VERSION ""

NS_ :

BS_:

BU_: PowertrainControlModule AtmosphericSensor SafetyRestraintSystem2 Aftertreatment_2_GasOutlet Aftertreatment_2_GasIntake DieselParticulateFilterControl Turbocharger SafetyRestraintSystem1 CabDisplay2 Aftertreatment_1_GasOutlet Aftertreatment_1_GasIntake OnBoardDataLogger OffBoardDiagnosticTool2 OffBoardDiagnosticTool1 FileServer ParkingBrakeController SeatController2 FanDriveController SteeringColumnUnit CommunicationUnitRadio CommunicationUnitSatellite CommunicationUnitCellular PropulsionBatteryCharger ChassisController2 ChassisController1 EngineValveControl AuxiliaryHeater2 AuxiliaryHeater1 ClutchUnit RampControl InformationSystem1 SuspensionSystemController2 OilSensor VehicleDynamicStability ExhaustEmissionController TransmissionDisplay2 TransmissionDisplay1 ClimateControl2 WaterPumpController RearAxleSteeringController LightingOperatorControl SeatController1 IgnitionController2 IgnitionController1 TirePressureController CabController2 CabController1 PneumaticSystemController SuspensionSystemController1 HydraulicPumpController EnduranceBrakingSystem RetarderExhaustEngine2 OnBoardDiagnosticUnit HeadwayController RetarderExhaustEngine1 CabDisplay1 ManagementComputer VirtualTerminal OffVehicleGateway PowerTakeOffFront HitchControl AuxiliaryValveControl BodyController TractorTrailerBridge1 StarterSystem ElectricalSystem VehicleSecurity VehicleNavigation AerodynamicControl ElectricalChargingSystem ClimateControl1 TripRecorder InstrumentCluster SuspensionDriveAxle2 SuspensionDriveAxle1 SuspensionSteerAxle SteeringController FuelSystem CruiseControl RetarderDriveline RetarderEngine BrakesDriveAxle2 BrakesDriveAxle1 BrakesSystemController BrakesSteerAxle AxleDrive2 AxleDrive1 AxleSteering PowerTakeOff ShiftConsoleSecondary ShiftConsolePrimary Transmission2 Transmission1 Engine2 Engine1
VAL_TABLE_ FMI 0 "Above normal (most severe)" 1 "Below normal (most severe)" 2 "Data erratic" 3 "Voltage above normal" 4 "Voltage below normal" 5 "Current below normal" 6 "Current above normal" 7 "Mechanical system not responding" 8 "Abnormal frequency" 9 "Abnormal update rate" 10 "Abnormal rate of change" 11 "Root cause not known" 12 "Bad intelligent device" 13 "Out of calibration" 14 "Special intstructions" 15 "Above normal (least severe)" 16 "Above normal (moderately severe)" 17 "Below normal (least severe)" 18 "Below normal (moderately severe)" 19 "Received network data in error" 20 "Data drifted high" 21 "Data drifted low" 31 "Condition exists" ;
VAL_TABLE_ InvertedBit 1 "orig: 0x0" 0 "orig: 0x1" ;
VAL_TABLE_ InvertedByte 129 "orig: 126 / 0x7E" 255 "orig: 0 / 0x0" 254 "orig: 1 / 0x1" 253 "orig: 2 / 0x2" 252 "orig: 3 / 0x3" 251 "orig: 4 / 0x4" 250 "orig: 5 / 0x5" 249 "orig: 6 / 0x6" 248 "orig: 7 / 0x7" 247 "orig: 8 / 0x8" 246 "orig: 9 / 0x9" 245 "orig: 10 / 0xA" 244 "orig: 11 / 0xB" 243 "orig: 12 / 0xC" 242 "orig: 13 / 0xD" 241 "orig: 14 / 0xE" 240 "orig: 15 / 0xF" 239 "orig: 16 / 0x10" 238 "orig: 17 / 0x11" 237 "orig: 17 / 0x12" 236 "orig: 19 / 0x13" 235 "orig: 20 / 0x14" 234 "orig: 21 / 0x15" 233 "orig: 22 / 0x16" 232 "orig: 23 / 0x17" 231 "orig: 24 / 0x18" 230 "orig: 25 / 0x19" 229 "orig: 26 / 0x1A" 228 "orig: 27 / 0x1B" 227 "orig: 28 / 0x1C" 226 "orig: 29 / 0x1D" 225 "orig: 30 / 0x1E" 224 "orig: 31 / 0x1F" 223 "orig: 32 / 0x20" 222 "orig: 33 / 0x21" 221 "orig: 34 / 0x22" 220 "orig: 35 / 0x23" 219 "orig: 36 / 0x24" 218 "orig: 37 / 0x25" 217 "orig: 38 / 0x26" 216 "orig: 39 / 0x27" 215 "orig: 40 / 0x28" 214 "orig: 41 / 0x29" 213 "orig: 42 / 0x2A" 212 "orig: 43 / 0x2B" 211 "orig: 44 / 0x2C" 210 "orig: 45 / 0x2D" 209 "orig: 46 / 0x2E" 208 "orig: 47 / 0x2F" 207 "orig: 48 / 0x30" 206 "orig: 49 / 0x31" 205 "orig: 50 / 0x32" 204 "orig: 51 / 0x33" 203 "orig: 52 / 0x34" 202 "orig: 53 / 0x35" 201 "orig: 54 / 0x36" 200 "orig: 55 / 0x37" 199 "orig: 56 / 0x38" 198 "orig: 57 / 0x39" 197 "orig: 58 / 0x3A" 196 "orig: 59 / 0x3B" 195 "orig: 60 / 0x3C" 194 "orig: 61 / 0x3D" 193 "orig: 62 / 0x3E" 192 "orig: 63 / 0x3F" 191 "orig: 64 / 0x40" 190 "orig: 65 / 0x41" 189 "orig: 66 / 0x42" 188 "orig: 67 / 0x43" 187 "orig: 68 / 0x44" 186 "orig: 69 / 0x45" 185 "orig: 70 / 0x46" 184 "orig: 71 / 0x47" 183 "orig: 72 / 0x48" 182 "orig: 73 / 0x49" 181 "orig: 74 / 0x4A" 180 "orig: 75 / 0x4B" 179 "orig: 76 / 0x4C" 178 "orig: 77 / 0x4D" 177 "orig: 78 / 0x4E" 176 "orig: 79 / 0x4F" 175 "orig: 80 / 0x50" 174 "orig: 81 / 0x51" 173 "orig: 82 / 0x52" 172 "orig: 83 / 0x53" 171 "orig: 84 / 0x54" 170 "orig: 85 / 0x55" 169 "orig: 86 / 0x56" 168 "orig: 87 / 0x57" 167 "orig: 88 / 0x58" 166 "orig: 89 / 0x59" 165 "orig: 90 / 0x5A" 164 "orig: 91 / 0x5B" 163 "orig: 92 / 0x5C" 162 "orig: 93 / 0x5D" 161 "orig: 94 / 0x5E" 160 "orig: 95 / 0x5F" 159 "orig: 96 / 0x60" 158 "orig: 97 / 0x61" 157 "orig: 98 / 0x62" 156 "orig: 99 / 0x63" 155 "orig: 100 / 0x64" 154 "orig: 101 / 0x65" 153 "orig: 102 / 0x66" 152 "orig: 103 / 0x67" 151 "orig: 104 / 0x68" 150 "orig: 105 / 0x69" 149 "orig: 106 / 0x6A" 148 "orig: 107 / 0x6B" 147 "orig: 108 / 0x6C" 146 "orig: 109 / 0x6D" 145 "orig: 110 / 0x6E" 144 "orig: 111 / 0x6F" 143 "orig: 112 / 0x70" 142 "orig: 113 / 0x71" 141 "orig: 114 / 0x72" 140 "orig: 115 / 0x73" 139 "orig: 116 / 0x74" 138 "orig: 117 / 0x75" 137 "orig: 118 / 0x76" 136 "orig: 119 / 0x77" 135 "orig: 120 / 0x78" 134 "orig: 121 / 0x79" 133 "orig: 122 / 0x7A" 132 "orig: 123 / 0x7B" 131 "orig: 124 / 0x7C" 130 "orig: 125 / 0x7D" 128 "orig: 127 / 0x7F" 127 "orig: 128 / 0x80" 126 "orig: 129 / 0x81" 125 "orig: 130 / 0x82" 124 "orig: 131 / 0x83" 123 "orig: 132 / 0x84" 122 "orig: 133 / 0x85" 121 "orig: 134 / 0x86" 120 "orig: 135 / 0x87" 119 "orig: 136 / 0x88" 118 "orig: 137 / 0x89" 117 "orig: 138 / 0x8A" 116 "orig: 139 / 0x8B" 115 "orig: 140 / 0x8C" 114 "orig: 141 / 0x8D" 113 "orig: 142 / 0x8E" 112 "orig: 143 / 0x8F" 111 "orig: 144 / 0x90" 110 "orig: 145 / 0x91" 109 "orig: 146 / 0x92" 108 "orig: 147 / 0x93" 107 "orig: 148 / 0x94" 106 "orig: 149 / 0x95" 105 "orig: 150 / 0x96" 104 "orig: 151 / 0x97" 103 "orig: 152 / 0x98" 102 "orig: 153 / 0x99" 101 "orig: 154 / 0x9A" 100 "orig: 155 / 0x9B" 99 "orig: 156 / 0x9C" 98 "orig: 157 / 0x9D" 97 "orig: 158 / 0x9E" 96 "orig: 159 / 0x9F" 95 "orig: 160 / 0xA0" 94 "orig: 161 / 0xA1" 93 "orig: 162 / 0xA2" 92 "orig: 163 / 0xA3" 91 "orig: 164 / 0xA4" 90 "orig: 165 / 0xA5" 89 "orig: 166 / 0xA6" 88 "orig: 167 / 0xA7" 87 "orig: 168 / 0xA8" 86 "orig: 169 / 0xA9" 85 "orig: 170 / 0xAA" 84 "orig: 171 / 0xAB" 83 "orig: 172 / 0xAC" 82 "orig: 173 / 0xAD" 81 "orig: 174 / 0xAE" 80 "orig: 175 / 0xAF" 79 "orig: 176 / 0xB0" 78 "orig: 177 / 0xB1" 77 "orig: 178 / 0xB2" 76 "orig: 179 / 0xB3" 75 "orig: 180 / 0xB4" 74 "orig: 181 / 0xB5" 73 "orig: 182 / 0xB6" 72 "orig: 183 / 0xB7" 71 "orig: 184 / 0xB8" 70 "orig: 185 / 0xB9" 69 "orig: 186 / 0xBA" 68 "orig: 187 / 0xBB" 67 "orig: 188 / 0xBC" 66 "orig: 189 / 0xBD" 65 "orig: 190 / 0xBE" 64 "orig: 191 / 0xBF" 63 "orig: 192 / 0xC0" 62 "orig: 193 / 0xC1" 61 "orig: 194 / 0xC2" 60 "orig: 195 / 0xC3" 59 "orig: 196 / 0xC4" 58 "orig: 197 / 0xC5" 57 "orig: 198 / 0xC6" 56 "orig: 199 / 0xC7" 55 "orig: 200 / 0xC8" 54 "orig: 201 / 0xC9" 53 "orig: 202 / 0xCA" 52 "orig: 203 / 0xCB" 51 "orig: 204 / 0xCC" 50 "orig: 205 / 0xCD" 49 "orig: 206 / 0xCE" 48 "orig: 207 / 0xCF" 47 "orig: 208 / 0xD0" 46 "orig: 209 / 0xD1" 45 "orig: 210 / 0xD2" 44 "orig: 211 / 0xD3" 43 "orig: 212 / 0xD4" 42 "orig: 213 / 0xD5" 41 "orig: 214 / 0xD6" 40 "orig: 215 / 0xD7" 39 "orig: 216 / 0xD8" 38 "orig: 217 / 0xD9" 37 "orig: 218 / 0xDA" 36 "orig: 219 / 0xDB" 35 "orig: 220 / 0xDC" 34 "orig: 221 / 0xDD" 33 "orig: 222 / 0xDE" 32 "orig: 223 / 0xDF" 31 "orig: 224 / 0xE0" 30 "orig: 225 / 0xE1" 29 "orig: 226 / 0xE2" 28 "orig: 227 / 0xE3" 27 "orig: 228 / 0xE4" 26 "orig: 229 / 0xE5" 25 "orig: 230 / 0xE6" 24 "orig: 231 / 0xE7" 23 "orig: 232 / 0xE8" 22 "orig: 233 / 0xE9" 21 "orig: 234 / 0xEA" 20 "orig: 235 / 0xEB" 19 "orig: 236 / 0xEC" 18 "orig: 237 / 0xED" 17 "orig: 238 / 0xEE" 16 "orig: 239 / 0xEF" 15 "orig: 240 / 0xF0" 14 "orig: 241 / 0xF1" 13 "orig: 242 / 0xF2" 12 "orig: 243 / 0xF3" 11 "orig: 244 / 0xF4" 10 "orig: 245 / 0xF5" 9 "orig: 246 / 0xF6" 8 "orig: 247 / 0xF7" 7 "orig: 248 / 0xF8" 6 "orig: 249 / 0xF9" 5 "orig: 250 / 0xFA" 4 "orig: 251 / 0xFB" 3 "orig: 252 / 0xFC" 2 "orig: 253 / 0xFD" 1 "orig: 254 / 0xFE" 0 "orig: 255 / 0xFF" ;
VAL_TABLE_ Ports 21 "Global (All ports)" 0 "Local" ;

BO_ 3221225472 VECTOR__INDEPENDENT_SIG_MSG: 0 Vector__XXX
 SG_ SourceAddress : 0|8@1+ (1,0) [0|0] "" Vector__XXX
 SG_ NncntnuslyMonitoredSystemsStatus : 0|16@1+ (1,0) [0|0] "" Vector__XXX
 SG_ NncntnslyMonitoredSystemsSupport : 0|16@1+ (1,0) [0|0] "" Vector__XXX
 SG_ CntnslyMntrdSystmsSupport_Status : 0|8@1+ (1,0) [0|0] "" Vector__XXX
 SG_ AETCTorqueValue : 0|16@1+ (1,0) [0|64255] "Nm" Vector__XXX
 SG_ TrailerWeight : 0|16@1+ (2,0) [0|128510] "kg" Vector__XXX
 SG_ ReferenceTirePressSetting : 0|8@1+ (8,0) [0|2000] "kPa" Vector__XXX
 SG_ ReferenceTirePress : 0|8@1+ (8,0) [0|2000] "kPa" Vector__XXX
 SG_ TirePressThresholdDetection : 0|3@1+ (1,0) [0|7] "" Vector__XXX
 SG_ TireAirLeakageRate : 0|16@1+ (0.1,0) [0|6425.5] "Pa/s" Vector__XXX
 SG_ CTIWheelEndElectricalFault : 0|2@1+ (1,0) [0|3] "" Vector__XXX
 SG_ CTITireStatus : 0|2@1+ (1,0) [0|3] "" Vector__XXX
 SG_ CTIWheelSensorStatus : 0|2@1+ (1,0) [0|3] "" Vector__XXX
 SG_ TireTemp : 0|16@1+ (0.03125,-273) [-273|1734.96875] "deg C" Vector__XXX
 SG_ TirePress : 0|8@1+ (4,0) [0|1000] "kPa" Vector__XXX
 SG_ EngTurningGearEngaged : 0|2@1+ (1,0) [0|3] "" Vector__XXX
 SG_ AETCSpeedValue : 0|16@1+ (0.125,0) [0|8031.875] "rpm" Vector__XXX
 SG_ CPGLen : 0|8@0+ (1,0) [0|60] "" Vector__XXX
 SG_ CPGN : 0|18@0+ (1,0) [0|262143] "" Vector__XXX
 SG_ TrailerFormat : 0|3@0+ (1,0) [0|7] "" Vector__XXX
 SG_ TypeOfService : 0|3@0+ (1,0) [0|7] "" Vector__XXX

BO_ 2365342974 HVESSD15: 8 Vector__XXX
 SG_ NomChargeCurLmt : 16|16@1+ (0.125,-4000) [0|4031.875] "A" Vector__XXX
 SG_ NomDisCurLmt : 0|16@1+ (0.125,-4000) [-4000|0] "A" Vector__XXX

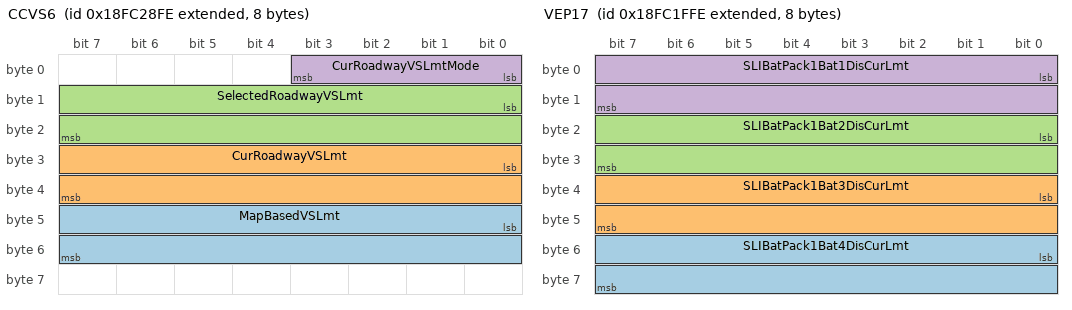
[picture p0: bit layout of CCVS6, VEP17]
BO_ 2566662398 CCVS6: 8 Vector__XXX
 SG_ MapBasedVSLmt : 40|16@1+ (0.00390625,0) [0|250.99609375] "km/h" Vector__XXX
 SG_ CurRoadwayVSLmt : 24|16@1+ (0.00390625,0) [0|250.99609375] "km/h" Vector__XXX
 SG_ SelectedRoadwayVSLmt : 8|16@1+ (0.00390625,0) [0|250.99609375] "km/h" Vector__XXX
 SG_ CurRoadwayVSLmtMode : 0|4@1+ (1,0) [0|15] "" Vector__XXX

BO_ 2365334014 HVESSMS3: 8 Vector__XXX
 SG_ Module96OperationalSt : 62|2@1+ (1,0) [0|3] "" Vector__XXX
 SG_ Module95OperationalSt : 60|2@1+ (1,0) [0|3] "" Vector__XXX
 SG_ Module94OperationalSt : 58|2@1+ (1,0) [0|3] "" Vector__XXX
 SG_ Module93OperationalSt : 56|2@1+ (1,0) [0|3] "" Vector__XXX
 SG_ Module92OperationalSt : 54|2@1+ (1,0) [0|3] "" Vector__XXX
 SG_ Module91OperationalSt : 52|2@1+ (1,0) [0|3] "" Vector__XXX
 SG_ Module90OperationalSt : 50|2@1+ (1,0) [0|3] "" Vector__XXX
 SG_ Module89OperationalSt : 48|2@1+ (1,0) [0|3] "" Vector__XXX
 SG_ Module88OperationalSt : 46|2@1+ (1,0) [0|3] "" Vector__XXX
 SG_ Module87OperationalSt : 44|2@1+ (1,0) [0|3] "" Vector__XXX
 SG_ Module86OperationalSt : 42|2@1+ (1,0) [0|3] "" Vector__XXX
 SG_ Module85OperationalSt : 40|2@1+ (1,0) [0|3] "" Vector__XXX
 SG_ Module84OperationalSt : 38|2@1+ (1,0) [0|3] "" Vector__XXX
 SG_ Module83OperationalSt : 36|2@1+ (1,0) [0|3] "" Vector__XXX
 SG_ Module82OperationalSt : 34|2@1+ (1,0) [0|3] "" Vector__XXX
 SG_ Module81OperationalSt : 32|2@1+ (1,0) [0|3] "" Vector__XXX
 SG_ Module80OperationalSt : 30|2@1+ (1,0) [0|3] "" Vector__XXX
 SG_ Module79OperationalSt : 28|2@1+ (1,0) [0|3] "" Vector__XXX
 SG_ Module78OperationalSt : 26|2@1+ (1,0) [0|3] "" Vector__XXX
 SG_ Module77OperationalSt : 24|2@1+ (1,0) [0|3] "" Vector__XXX
 SG_ Module76OperationalSt : 22|2@1+ (1,0) [0|3] "" Vector__XXX
 SG_ Module75OperationalSt : 20|2@1+ (1,0) [0|3] "" Vector__XXX
 SG_ Module74OperationalSt : 18|2@1+ (1,0) [0|3] "" Vector__XXX
 SG_ Module73OperationalSt : 16|2@1+ (1,0) [0|3] "" Vector__XXX
 SG_ Module72OperationalSt : 14|2@1+ (1,0) [0|3] "" Vector__XXX
 SG_ Module71OperationalSt : 12|2@1+ (1,0) [0|3] "" Vector__XXX
 SG_ Module70OperationalSt : 10|2@1+ (1,0) [0|3] "" Vector__XXX
 SG_ Module69OperationalSt : 8|2@1+ (1,0) [0|3] "" Vector__XXX
 SG_ Module68OperationalSt : 6|2@1+ (1,0) [0|3] "" Vector__XXX
 SG_ Module67OperationalSt : 4|2@1+ (1,0) [0|3] "" Vector__XXX
 SG_ Module66OperationalSt : 2|2@1+ (1,0) [0|3] "" Vector__XXX
 SG_ Module65OperationalSt : 0|2@1+ (1,0) [0|3] "" Vector__XXX

BO_ 2365333758 HVESSMS2: 8 Vector__XXX
 SG_ Module64OperationalSt : 62|2@1+ (1,0) [0|3] "" Vector__XXX
 SG_ Module63OperationalSt : 60|2@1+ (1,0) [0|3] "" Vector__XXX
 SG_ Module62OperationalSt : 58|2@1+ (1,0) [0|3] "" Vector__XXX
 SG_ Module61OperationalSt : 56|2@1+ (1,0) [0|3] "" Vector__XXX
 SG_ Module60OperationalSt : 54|2@1+ (1,0) [0|3] "" Vector__XXX
 SG_ Module59OperationalSt : 52|2@1+ (1,0) [0|3] "" Vector__XXX
 SG_ Module58OperationalSt : 50|2@1+ (1,0) [0|3] "" Vector__XXX
 SG_ Module57OperationalSt : 48|2@1+ (1,0) [0|3] "" Vector__XXX
 SG_ Module56OperationalSt : 46|2@1+ (1,0) [0|3] "" Vector__XXX
 SG_ Module55OperationalSt : 44|2@1+ (1,0) [0|3] "" Vector__XXX
 SG_ Module54OperationalSt : 42|2@1+ (1,0) [0|3] "" Vector__XXX
 SG_ Module53OperationalSt : 40|2@1+ (1,0) [0|3] "" Vector__XXX
 SG_ Module52OperationalSt : 38|2@1+ (1,0) [0|3] "" Vector__XXX
 SG_ Module51OperationalSt : 36|2@1+ (1,0) [0|3] "" Vector__XXX
 SG_ Module50OperationalSt : 34|2@1+ (1,0) [0|3] "" Vector__XXX
 SG_ Module49OperationalSt : 32|2@1+ (1,0) [0|3] "" Vector__XXX
 SG_ Module48OperationalSt : 30|2@1+ (1,0) [0|3] "" Vector__XXX
 SG_ Module47OperationalSt : 28|2@1+ (1,0) [0|3] "" Vector__XXX
 SG_ Module46OperationalSt : 26|2@1+ (1,0) [0|3] "" Vector__XXX
 SG_ Module45OperationalSt : 24|2@1+ (1,0) [0|3] "" Vector__XXX
 SG_ Module44OperationalSt : 22|2@1+ (1,0) [0|3] "" Vector__XXX
 SG_ Module43OperationalSt : 20|2@1+ (1,0) [0|3] "" Vector__XXX
 SG_ Module42OperationalSt : 18|2@1+ (1,0) [0|3] "" Vector__XXX
 SG_ Module41OperationalSt : 16|2@1+ (1,0) [0|3] "" Vector__XXX
 SG_ Module40OperationalSt : 14|2@1+ (1,0) [0|3] "" Vector__XXX
 SG_ Module39OperationalSt : 12|2@1+ (1,0) [0|3] "" Vector__XXX
 SG_ Module38OperationalSt : 10|2@1+ (1,0) [0|3] "" Vector__XXX
 SG_ Module37OperationalSt : 8|2@1+ (1,0) [0|3] "" Vector__XXX
 SG_ Module36OperationalSt : 6|2@1+ (1,0) [0|3] "" Vector__XXX
 SG_ Module35OperationalSt : 4|2@1+ (1,0) [0|3] "" Vector__XXX
 SG_ Module34OperationalSt : 2|2@1+ (1,0) [0|3] "" Vector__XXX
 SG_ Module33OperationalSt : 0|2@1+ (1,0) [0|3] "" Vector__XXX

BO_ 2566660094 VEP17: 8 Vector__XXX
 SG_ SLIBatPack1Bat4DisCurLmt : 48|16@1+ (0.05,-1600) [-1|0] "A" Vector__XXX
 SG_ SLIBatPack1Bat3DisCurLmt : 32|16@1+ (0.05,-1600) [-1|0] "A" Vector__XXX
 SG_ SLIBatPack1Bat2DisCurLmt : 16|16@1+ (0.05,-1600) [-1|0] "A" Vector__XXX
 SG_ SLIBatPack1Bat1DisCurLmt : 0|16@1+ (0.05,-1600) [-1|0] "A" Vector__XXX

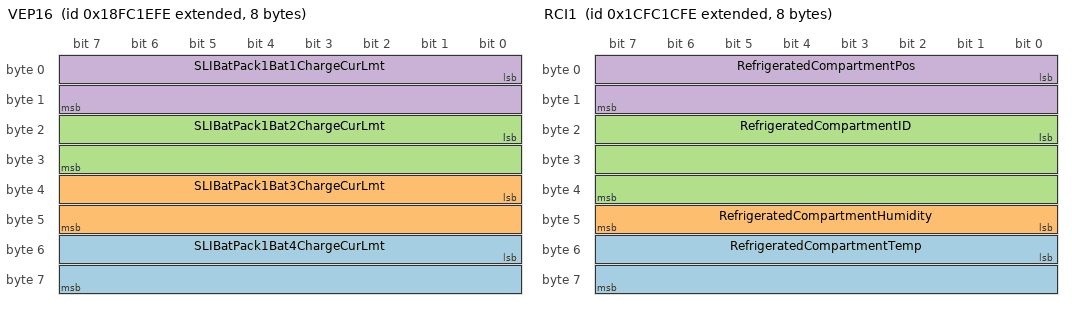
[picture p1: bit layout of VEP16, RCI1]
BO_ 2566659838 VEP16: 8 Vector__XXX
 SG_ SLIBatPack1Bat4ChargeCurLmt : 48|16@1+ (0.05,-1600) [0|1] "A" Vector__XXX
 SG_ SLIBatPack1Bat3ChargeCurLmt : 32|16@1+ (0.05,-1600) [0|1] "A" Vector__XXX
 SG_ SLIBatPack1Bat2ChargeCurLmt : 16|16@1+ (0.05,-1600) [0|1] "A" Vector__XXX
 SG_ SLIBatPack1Bat1ChargeCurLmt : 0|16@1+ (0.05,-1600) [0|1] "A" Vector__XXX

BO_ 2633768446 RCI2: 8 Vector__XXX
 SG_ TransportationCompartmentDoorSt : 8|2@1+ (1,0) [0|3] "" Vector__XXX
 SG_ TransportationCompartmentDoorID : 0|8@1+ (1,0) [0|250] "" Vector__XXX

BO_ 2633768190 RCI1: 8 Vector__XXX
 SG_ RefrigeratedCompartmentTemp : 48|16@1+ (0.03125,-273) [-273|1734.96875] "°C" Vector__XXX
 SG_ RefrigeratedCompartmentHumidity : 40|8@1+ (0.4,0) [0|100] "%" Vector__XXX
 SG_ RefrigeratedCompartmentID : 16|24@1+ (1,0) [0|16449535] "" Vector__XXX
 SG_ RefrigeratedCompartmentPos : 0|16@1+ (1,0) [0|64255] "" Vector__XXX

BO_ 2633761022 TWBW: 16 Vector__XXX
 SG_ RemTlrAxle8RightWheel : 120|8@1+ (0.4,0) [0|100] "%" Vector__XXX
 SG_ RemTlrAxle8LeftWheel : 112|8@1+ (0.4,0) [0|100] "%" Vector__XXX
 SG_ RemTlrAxle7RightWheel : 104|8@1+ (0.4,0) [0|100] "%" Vector__XXX
 SG_ RemTlrAxle7LeftWheel : 96|8@1+ (0.4,0) [0|100] "%" Vector__XXX
 SG_ RemTlrAxle6RightWheel : 88|8@1+ (0.4,0) [0|100] "%" Vector__XXX
 SG_ RemTlrAxle6LeftWheel : 80|8@1+ (0.4,0) [0|100] "%" Vector__XXX
 SG_ RemTlrAxle5RightWheel : 72|8@1+ (0.4,0) [0|100] "%" Vector__XXX
 SG_ RemTlrAxle5LeftWheel : 64|8@1+ (0.4,0) [0|100] "%" Vector__XXX
 SG_ RemTlrAxle4RightWheel : 56|8@1+ (0.4,0) [0|100] "%" Vector__XXX
 SG_ RemTlrAxle4LeftWheel : 48|8@1+ (0.4,0) [0|100] "%" Vector__XXX
 SG_ RemTlrAxle3RightWheel : 40|8@1+ (0.4,0) [0|100] "%" Vector__XXX
 SG_ RemTlrAxle3LeftWheel : 32|8@1+ (0.4,0) [0|100] "%" Vector__XXX
 SG_ RemTlrAxle2RightWheel : 24|8@1+ (0.4,0) [0|100] "%" Vector__XXX
 SG_ RemTlrAxle2LeftWheel : 16|8@1+ (0.4,0) [0|100] "%" Vector__XXX
 SG_ RemTlrAxle1RightWheel : 8|8@1+ (0.4,0) [0|100] "%" Vector__XXX
 SG_ RemTlrAxle1LeftWheel : 0|8@1+ (0.4,0) [0|100] "%" Vector__XXX

BO_ 2566648574 EFS3: 8 Vector__XXX
 SG_ FuelFilter : 16|16@1+ (0.03125,-273) [-273|1734.96875] "°C" Vector__XXX
 SG_ FuelFilterDiffPress : 0|16@1+ (0.01,0) [0|642.55] "kPa" Vector__XXX

BO_ 2566584574 ENGMXT: 8 Vector__XXX
 SG_ TrqValue : 40|8@1+ (0.4,0) [0|100] "%" Vector__XXX
 SG_ SpdValue : 32|16@1+ (0.125,0) [0|8031.875] "rpm" Vector__XXX
 SG_ ReferenceNetTrq : 24|16@1+ (1,0) [0|64255] "Nm" Vector__XXX
 SG_ ActiveDerate : 16|2@1+ (1,0) [0|3] "" Vector__XXX
 SG_ TotalCount : 12|4@1+ (1,0) [0|15] "" Vector__XXX
 SG_ ActiveInstance : 8|4@1+ (1,0) [0|15] "" Vector__XXX
 SG_ Instance : 4|4@1+ (1,0) [1|15] "" Vector__XXX
 SG_ NumOfPoints : 0|4@1+ (1,0) [2|15] "" Vector__XXX

BO_ 2566537214 EC4: 8 Vector__XXX
 SG_ CoolingFanInManifoldActTemp : 16|16@1+ (0.03125,-273) [-273|1734.96875] "°C" Vector__XXX
 SG_ CoolingFanCoolantActTemp : 0|16@1+ (0.03125,-273) [-273|1734.96875] "°C" Vector__XXX

BO_ 2499428094 TS: 8 Vector__XXX
 SG_ SignSpdLmt : 0|16@1+ (0.00390625,0) [0|250.99609375] "km/h" Vector__XXX

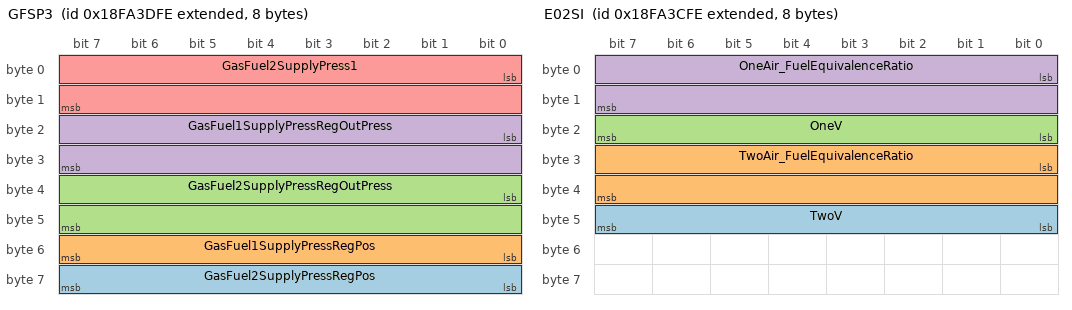
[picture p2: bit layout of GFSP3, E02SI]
BO_ 2566536702 GFSP3: 8 Vector__XXX
 SG_ GasFuel2SupplyPressRegPos : 56|8@1+ (0.4,0) [0|100] "%" Vector__XXX
 SG_ GasFuel1SupplyPressRegPos : 48|8@1+ (0.4,0) [0|100] "%" Vector__XXX
 SG_ GasFuel2SupplyPressRegOutPress : 32|16@1+ (1,0) [0|64255] "kPa" Vector__XXX
 SG_ GasFuel1SupplyPressRegOutPress : 16|16@1+ (1,0) [0|64255] "kPa" Vector__XXX
 SG_ GasFuel2SupplyPress1 : 0|16@1+ (0.5,0) [0|32127.5] "kPa" Vector__XXX

BO_ 2566536446 E02SI: 8 Vector__XXX
 SG_ TwoV : 40|8@1+ (0.01,0) [0|2.5] "V" Vector__XXX
 SG_ TwoAir_FuelEquivalenceRatio : 24|16@1+ (3.05E-005,0) [0|1.9597775] "" Vector__XXX
 SG_ OneV : 16|8@1+ (0.01,0) [0|2.5] "V" Vector__XXX
 SG_ OneAir_FuelEquivalenceRatio : 0|16@1+ (3.05E-005,0) [0|1.9597775] "" Vector__XXX

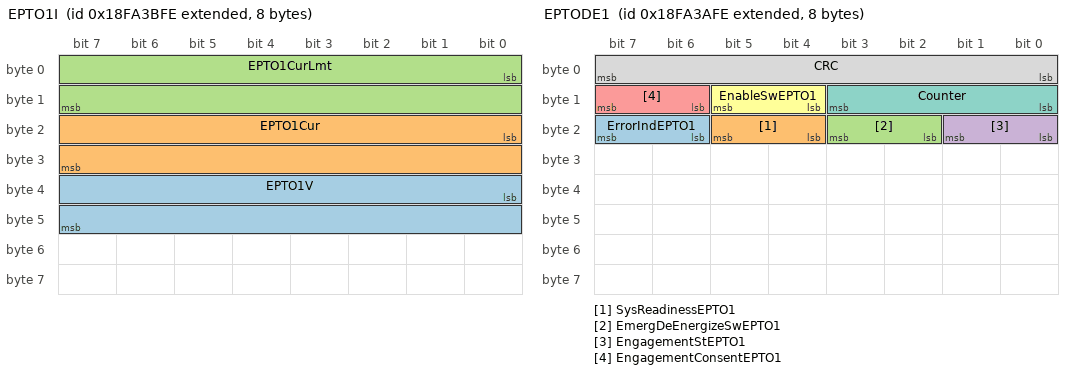
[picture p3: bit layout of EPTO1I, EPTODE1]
BO_ 2566536190 EPTO1I: 8 Vector__XXX
 SG_ EPTO1V : 32|16@1+ (0.05,0) [0|3212.75] "V" Vector__XXX
 SG_ EPTO1Cur : 16|16@1+ (0.05,0) [0|3212.75] "A" Vector__XXX
 SG_ EPTO1CurLmt : 0|16@1+ (0.05,0) [0|3212.75] "A" Vector__XXX

BO_ 2566535934 EPTODE1: 8 Vector__XXX
 SG_ ErrorIndEPTO1 : 22|2@1+ (1,0) [0|3] "" Vector__XXX
 SG_ SysReadinessEPTO1 : 20|2@1+ (1,0) [0|3] "" Vector__XXX
 SG_ EmergDeEnergizeSwEPTO1 : 18|2@1+ (1,0) [0|3] "" Vector__XXX
 SG_ EngagementStEPTO1 : 16|2@1+ (1,0) [0|3] "" Vector__XXX
 SG_ EngagementConsentEPTO1 : 14|2@1+ (1,0) [0|3] "" Vector__XXX
 SG_ EnableSwEPTO1 : 12|2@1+ (1,0) [0|3] "" Vector__XXX
 SG_ Counter : 8|4@1+ (1,0) [0|15] "" Vector__XXX
 SG_ CRC : 0|8@1+ (1,0) [0|255] "" Vector__XXX

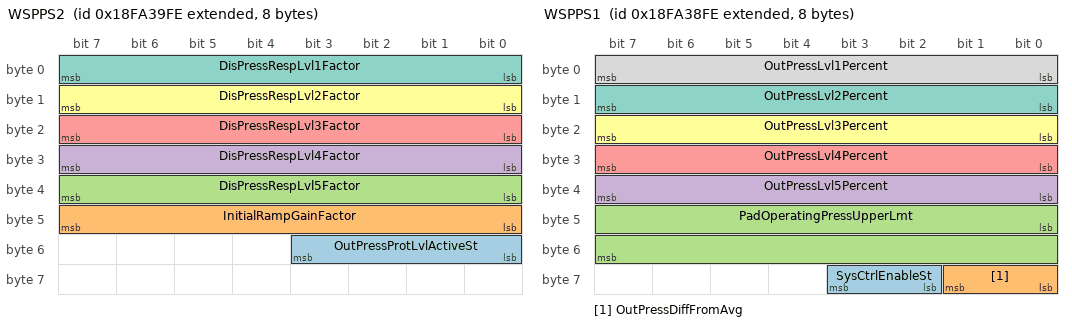
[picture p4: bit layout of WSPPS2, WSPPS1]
BO_ 2566535678 WSPPS2: 8 Vector__XXX
 SG_ OutPressProtLvlActiveSt : 48|4@1+ (1,0) [0|15] "" Vector__XXX
 SG_ InitialRampGainFactor : 40|8@1+ (0.5,0) [0|125] "%" Vector__XXX
 SG_ DisPressRespLvl5Factor : 32|8@1+ (0.5,0) [0|125] "%" Vector__XXX
 SG_ DisPressRespLvl4Factor : 24|8@1+ (0.5,0) [0|125] "%" Vector__XXX
 SG_ DisPressRespLvl3Factor : 16|8@1+ (0.5,0) [0|125] "%" Vector__XXX
 SG_ DisPressRespLvl2Factor : 8|8@1+ (0.5,0) [0|125] "%" Vector__XXX
 SG_ DisPressRespLvl1Factor : 0|8@1+ (0.5,0) [0|125] "%" Vector__XXX

BO_ 2566535422 WSPPS1: 8 Vector__XXX
 SG_ SysCtrlEnableSt : 58|2@1+ (1,0) [0|3] "" Vector__XXX
 SG_ OutPressDiffFromAvg : 56|2@1+ (1,0) [0|3] "" Vector__XXX
 SG_ PadOperatingPressUpperLmt : 40|16@1+ (5,0) [0|321275] "kPa" Vector__XXX
 SG_ OutPressLvl5Percent : 32|8@1+ (0.5,0) [0|125] "%" Vector__XXX
 SG_ OutPressLvl4Percent : 24|8@1+ (0.5,0) [0|125] "%" Vector__XXX
 SG_ OutPressLvl3Percent : 16|8@1+ (0.5,0) [0|125] "%" Vector__XXX
 SG_ OutPressLvl2Percent : 8|8@1+ (0.5,0) [0|125] "%" Vector__XXX
 SG_ OutPressLvl1Percent : 0|8@1+ (0.5,0) [0|125] "%" Vector__XXX

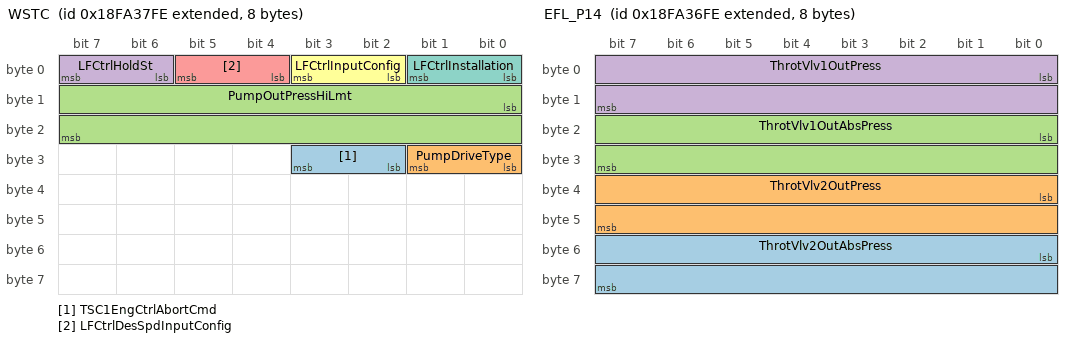
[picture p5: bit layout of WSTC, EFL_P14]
BO_ 2566535166 WSTC: 8 Vector__XXX
 SG_ TSC1EngCtrlAbortCmd : 26|2@1+ (1,0) [0|3] "" Vector__XXX
 SG_ PumpDriveType : 24|2@1+ (1,0) [0|3] "" Vector__XXX
 SG_ PumpOutPressHiLmt : 8|16@1+ (5,0) [0|321275] "kPa" Vector__XXX
 SG_ LFCtrlHoldSt : 6|2@1+ (1,0) [0|3] "" Vector__XXX
 SG_ LFCtrlDesSpdInputConfig : 4|2@1+ (1,0) [0|3] "" Vector__XXX
 SG_ LFCtrlInputConfig : 2|2@1+ (1,0) [0|3] "" Vector__XXX
 SG_ LFCtrlInstallation : 0|2@1+ (1,0) [0|3] "" Vector__XXX

BO_ 2566534910 EFL_P14: 8 Vector__XXX
 SG_ ThrotVlv2OutAbsPress : 48|16@1+ (0.1,0) [0|6425.5] "kPa" Vector__XXX
 SG_ ThrotVlv2OutPress : 32|16@1+ (0.1,0) [0|6425.5] "kPa" Vector__XXX
 SG_ ThrotVlv1OutAbsPress : 16|16@1+ (0.1,0) [0|6425.5] "kPa" Vector__XXX
 SG_ ThrotVlv1OutPress : 0|16@1+ (0.1,0) [0|6425.5] "kPa" Vector__XXX

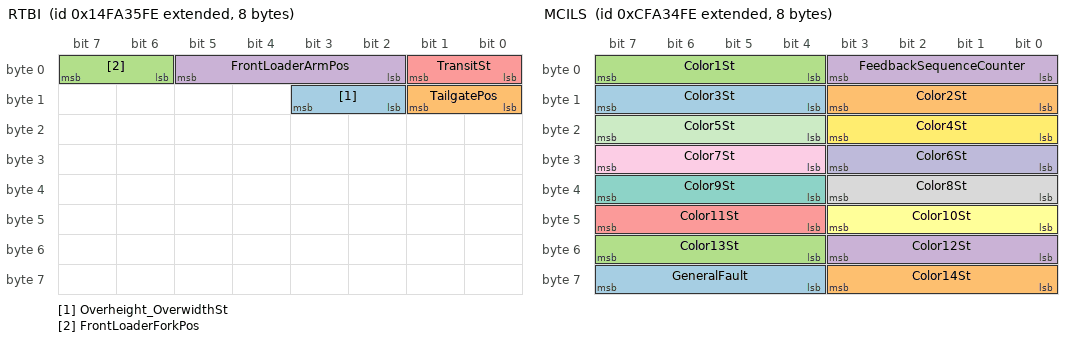
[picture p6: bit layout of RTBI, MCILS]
BO_ 2499425790 RTBI: 8 Vector__XXX
 SG_ Overheight_OverwidthSt : 10|2@1+ (1,0) [0|3] "" Vector__XXX
 SG_ TailgatePos : 8|2@1+ (1,0) [0|3] "" Vector__XXX
 SG_ FrontLoaderForkPos : 6|2@1+ (1,0) [0|3] "" Vector__XXX
 SG_ FrontLoaderArmPos : 2|4@1+ (1,0) [0|15] "" Vector__XXX
 SG_ TransitSt : 0|2@1+ (1,0) [0|3] "" Vector__XXX

BO_ 2365207806 MCILS: 8 Vector__XXX
 SG_ GeneralFault : 60|4@1+ (1,0) [0|15] "" Vector__XXX
 SG_ Color14St : 56|4@1+ (1,0) [0|15] "" Vector__XXX
 SG_ Color13St : 52|4@1+ (1,0) [0|15] "" Vector__XXX
 SG_ Color12St : 48|4@1+ (1,0) [0|15] "" Vector__XXX
 SG_ Color11St : 44|4@1+ (1,0) [0|15] "" Vector__XXX
 SG_ Color10St : 40|4@1+ (1,0) [0|15] "" Vector__XXX
 SG_ Color9St : 36|4@1+ (1,0) [0|15] "" Vector__XXX
 SG_ Color8St : 32|4@1+ (1,0) [0|15] "" Vector__XXX
 SG_ Color7St : 28|4@1+ (1,0) [0|15] "" Vector__XXX
 SG_ Color6St : 24|4@1+ (1,0) [0|15] "" Vector__XXX
 SG_ Color5St : 20|4@1+ (1,0) [0|15] "" Vector__XXX
 SG_ Color4St : 16|4@1+ (1,0) [0|15] "" Vector__XXX
 SG_ Color3St : 12|4@1+ (1,0) [0|15] "" Vector__XXX
 SG_ Color2St : 8|4@1+ (1,0) [0|15] "" Vector__XXX
 SG_ Color1St : 4|4@1+ (1,0) [0|15] "" Vector__XXX
 SG_ FeedbackSequenceCounter : 0|4@1+ (1,0) [0|13] "" Vector__XXX

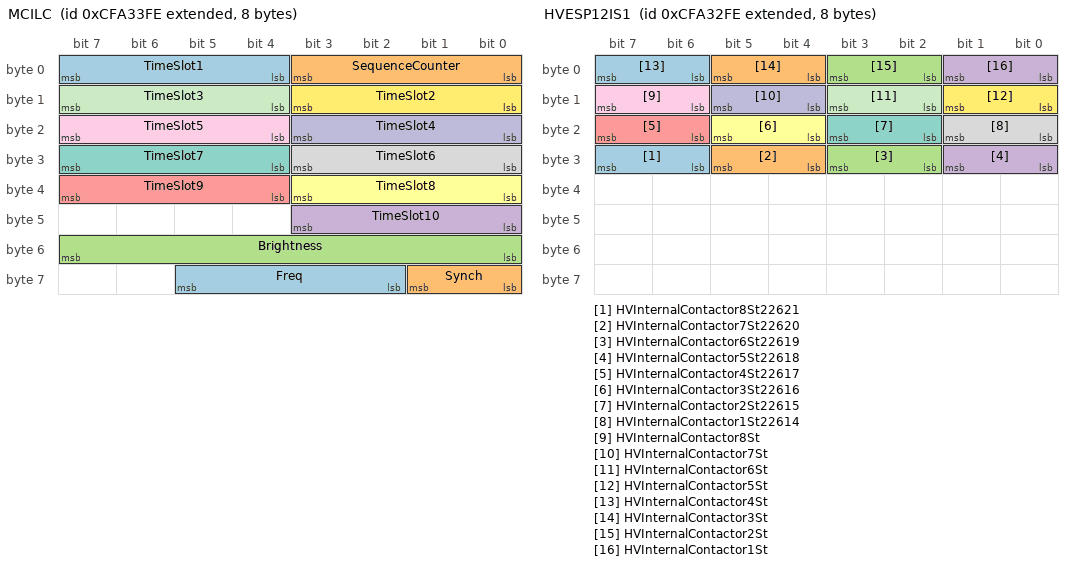
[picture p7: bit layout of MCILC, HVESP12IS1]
BO_ 2365207550 MCILC: 8 Vector__XXX
 SG_ Freq : 58|4@1+ (1,0) [0|15] "" Vector__XXX
 SG_ Synch : 56|2@1+ (1,0) [0|3] "" Vector__XXX
 SG_ Brightness : 48|8@1+ (1,0) [0|100] "%" Vector__XXX
 SG_ TimeSlot10 : 40|4@1+ (1,0) [0|15] "" Vector__XXX
 SG_ TimeSlot9 : 36|4@1+ (1,0) [0|15] "" Vector__XXX
 SG_ TimeSlot8 : 32|4@1+ (1,0) [0|15] "" Vector__XXX
 SG_ TimeSlot7 : 28|4@1+ (1,0) [0|15] "" Vector__XXX
 SG_ TimeSlot6 : 24|4@1+ (1,0) [0|15] "" Vector__XXX
 SG_ TimeSlot5 : 20|4@1+ (1,0) [0|15] "" Vector__XXX
 SG_ TimeSlot4 : 16|4@1+ (1,0) [0|15] "" Vector__XXX
 SG_ TimeSlot3 : 12|4@1+ (1,0) [0|15] "" Vector__XXX
 SG_ TimeSlot2 : 8|4@1+ (1,0) [0|15] "" Vector__XXX
 SG_ TimeSlot1 : 4|4@1+ (1,0) [0|15] "" Vector__XXX
 SG_ SequenceCounter : 0|4@1+ (1,0) [0|13] "" Vector__XXX

BO_ 2365207294 HVESP12IS1: 8 Vector__XXX
 SG_ HVInternalContactor8St22621 : 30|2@1+ (1,0) [0|3] "" Vector__XXX
 SG_ HVInternalContactor7St22620 : 28|2@1+ (1,0) [0|3] "" Vector__XXX
 SG_ HVInternalContactor6St22619 : 26|2@1+ (1,0) [0|3] "" Vector__XXX
 SG_ HVInternalContactor5St22618 : 24|2@1+ (1,0) [0|3] "" Vector__XXX
 SG_ HVInternalContactor4St22617 : 22|2@1+ (1,0) [0|3] "" Vector__XXX
 SG_ HVInternalContactor3St22616 : 20|2@1+ (1,0) [0|3] "" Vector__XXX
 SG_ HVInternalContactor2St22615 : 18|2@1+ (1,0) [0|3] "" Vector__XXX
 SG_ HVInternalContactor1St22614 : 16|2@1+ (1,0) [0|3] "" Vector__XXX
 SG_ HVInternalContactor8St : 14|2@1+ (1,0) [0|3] "" Vector__XXX
 SG_ HVInternalContactor7St : 12|2@1+ (1,0) [0|3] "" Vector__XXX
 SG_ HVInternalContactor6St : 10|2@1+ (1,0) [0|3] "" Vector__XXX
 SG_ HVInternalContactor5St : 8|2@1+ (1,0) [0|3] "" Vector__XXX
 SG_ HVInternalContactor4St : 6|2@1+ (1,0) [0|3] "" Vector__XXX
 SG_ HVInternalContactor3St : 4|2@1+ (1,0) [0|3] "" Vector__XXX
 SG_ HVInternalContactor2St : 2|2@1+ (1,0) [0|3] "" Vector__XXX
 SG_ HVInternalContactor1St : 0|2@1+ (1,0) [0|3] "" Vector__XXX

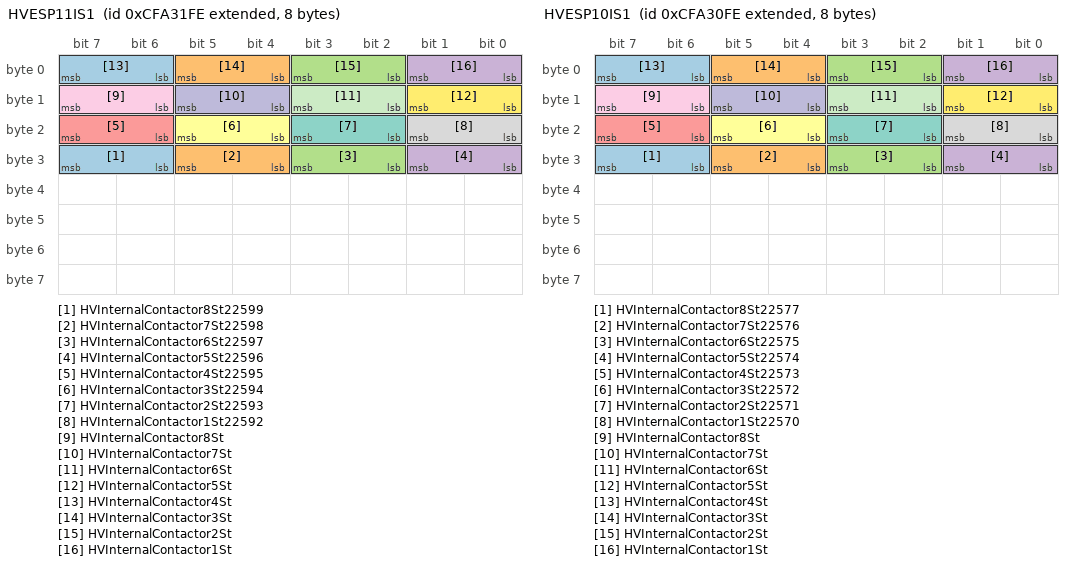
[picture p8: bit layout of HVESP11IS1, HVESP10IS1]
BO_ 2365207038 HVESP11IS1: 8 Vector__XXX
 SG_ HVInternalContactor8St22599 : 30|2@1+ (1,0) [0|3] "" Vector__XXX
 SG_ HVInternalContactor7St22598 : 28|2@1+ (1,0) [0|3] "" Vector__XXX
 SG_ HVInternalContactor6St22597 : 26|2@1+ (1,0) [0|3] "" Vector__XXX
 SG_ HVInternalContactor5St22596 : 24|2@1+ (1,0) [0|3] "" Vector__XXX
 SG_ HVInternalContactor4St22595 : 22|2@1+ (1,0) [0|3] "" Vector__XXX
 SG_ HVInternalContactor3St22594 : 20|2@1+ (1,0) [0|3] "" Vector__XXX
 SG_ HVInternalContactor2St22593 : 18|2@1+ (1,0) [0|3] "" Vector__XXX
 SG_ HVInternalContactor1St22592 : 16|2@1+ (1,0) [0|3] "" Vector__XXX
 SG_ HVInternalContactor8St : 14|2@1+ (1,0) [0|3] "" Vector__XXX
 SG_ HVInternalContactor7St : 12|2@1+ (1,0) [0|3] "" Vector__XXX
 SG_ HVInternalContactor6St : 10|2@1+ (1,0) [0|3] "" Vector__XXX
 SG_ HVInternalContactor5St : 8|2@1+ (1,0) [0|3] "" Vector__XXX
 SG_ HVInternalContactor4St : 6|2@1+ (1,0) [0|3] "" Vector__XXX
 SG_ HVInternalContactor3St : 4|2@1+ (1,0) [0|3] "" Vector__XXX
 SG_ HVInternalContactor2St : 2|2@1+ (1,0) [0|3] "" Vector__XXX
 SG_ HVInternalContactor1St : 0|2@1+ (1,0) [0|3] "" Vector__XXX

BO_ 2365206782 HVESP10IS1: 8 Vector__XXX
 SG_ HVInternalContactor8St22577 : 30|2@1+ (1,0) [0|3] "" Vector__XXX
 SG_ HVInternalContactor7St22576 : 28|2@1+ (1,0) [0|3] "" Vector__XXX
 SG_ HVInternalContactor6St22575 : 26|2@1+ (1,0) [0|3] "" Vector__XXX
 SG_ HVInternalContactor5St22574 : 24|2@1+ (1,0) [0|3] "" Vector__XXX
 SG_ HVInternalContactor4St22573 : 22|2@1+ (1,0) [0|3] "" Vector__XXX
 SG_ HVInternalContactor3St22572 : 20|2@1+ (1,0) [0|3] "" Vector__XXX
 SG_ HVInternalContactor2St22571 : 18|2@1+ (1,0) [0|3] "" Vector__XXX
 SG_ HVInternalContactor1St22570 : 16|2@1+ (1,0) [0|3] "" Vector__XXX
 SG_ HVInternalContactor8St : 14|2@1+ (1,0) [0|3] "" Vector__XXX
 SG_ HVInternalContactor7St : 12|2@1+ (1,0) [0|3] "" Vector__XXX
 SG_ HVInternalContactor6St : 10|2@1+ (1,0) [0|3] "" Vector__XXX
 SG_ HVInternalContactor5St : 8|2@1+ (1,0) [0|3] "" Vector__XXX
 SG_ HVInternalContactor4St : 6|2@1+ (1,0) [0|3] "" Vector__XXX
 SG_ HVInternalContactor3St : 4|2@1+ (1,0) [0|3] "" Vector__XXX
 SG_ HVInternalContactor2St : 2|2@1+ (1,0) [0|3] "" Vector__XXX
 SG_ HVInternalContactor1St : 0|2@1+ (1,0) [0|3] "" Vector__XXX

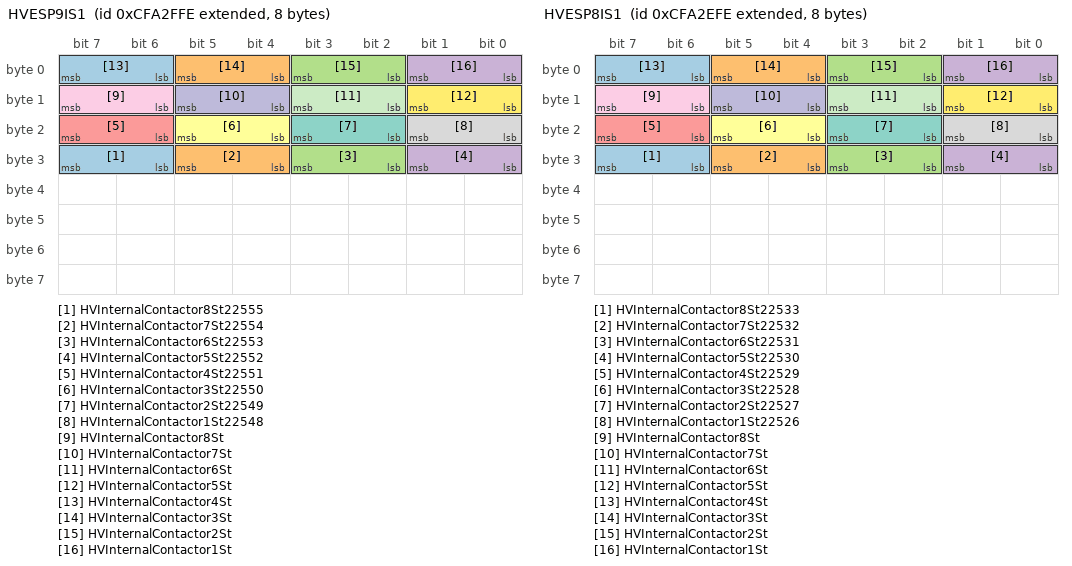
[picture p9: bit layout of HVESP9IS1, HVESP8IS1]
BO_ 2365206526 HVESP9IS1: 8 Vector__XXX
 SG_ HVInternalContactor8St22555 : 30|2@1+ (1,0) [0|3] "" Vector__XXX
 SG_ HVInternalContactor7St22554 : 28|2@1+ (1,0) [0|3] "" Vector__XXX
 SG_ HVInternalContactor6St22553 : 26|2@1+ (1,0) [0|3] "" Vector__XXX
 SG_ HVInternalContactor5St22552 : 24|2@1+ (1,0) [0|3] "" Vector__XXX
 SG_ HVInternalContactor4St22551 : 22|2@1+ (1,0) [0|3] "" Vector__XXX
 SG_ HVInternalContactor3St22550 : 20|2@1+ (1,0) [0|3] "" Vector__XXX
 SG_ HVInternalContactor2St22549 : 18|2@1+ (1,0) [0|3] "" Vector__XXX
 SG_ HVInternalContactor1St22548 : 16|2@1+ (1,0) [0|3] "" Vector__XXX
 SG_ HVInternalContactor8St : 14|2@1+ (1,0) [0|3] "" Vector__XXX
 SG_ HVInternalContactor7St : 12|2@1+ (1,0) [0|3] "" Vector__XXX
 SG_ HVInternalContactor6St : 10|2@1+ (1,0) [0|3] "" Vector__XXX
 SG_ HVInternalContactor5St : 8|2@1+ (1,0) [0|3] "" Vector__XXX
 SG_ HVInternalContactor4St : 6|2@1+ (1,0) [0|3] "" Vector__XXX
 SG_ HVInternalContactor3St : 4|2@1+ (1,0) [0|3] "" Vector__XXX
 SG_ HVInternalContactor2St : 2|2@1+ (1,0) [0|3] "" Vector__XXX
 SG_ HVInternalContactor1St : 0|2@1+ (1,0) [0|3] "" Vector__XXX

BO_ 2365206270 HVESP8IS1: 8 Vector__XXX
 SG_ HVInternalContactor8St22533 : 30|2@1+ (1,0) [0|3] "" Vector__XXX
 SG_ HVInternalContactor7St22532 : 28|2@1+ (1,0) [0|3] "" Vector__XXX
 SG_ HVInternalContactor6St22531 : 26|2@1+ (1,0) [0|3] "" Vector__XXX
 SG_ HVInternalContactor5St22530 : 24|2@1+ (1,0) [0|3] "" Vector__XXX
 SG_ HVInternalContactor4St22529 : 22|2@1+ (1,0) [0|3] "" Vector__XXX
 SG_ HVInternalContactor3St22528 : 20|2@1+ (1,0) [0|3] "" Vector__XXX
 SG_ HVInternalContactor2St22527 : 18|2@1+ (1,0) [0|3] "" Vector__XXX
 SG_ HVInternalContactor1St22526 : 16|2@1+ (1,0) [0|3] "" Vector__XXX
 SG_ HVInternalContactor8St : 14|2@1+ (1,0) [0|3] "" Vector__XXX
 SG_ HVInternalContactor7St : 12|2@1+ (1,0) [0|3] "" Vector__XXX
 SG_ HVInternalContactor6St : 10|2@1+ (1,0) [0|3] "" Vector__XXX
 SG_ HVInternalContactor5St : 8|2@1+ (1,0) [0|3] "" Vector__XXX
 SG_ HVInternalContactor4St : 6|2@1+ (1,0) [0|3] "" Vector__XXX
 SG_ HVInternalContactor3St : 4|2@1+ (1,0) [0|3] "" Vector__XXX
 SG_ HVInternalContactor2St : 2|2@1+ (1,0) [0|3] "" Vector__XXX
 SG_ HVInternalContactor1St : 0|2@1+ (1,0) [0|3] "" Vector__XXX

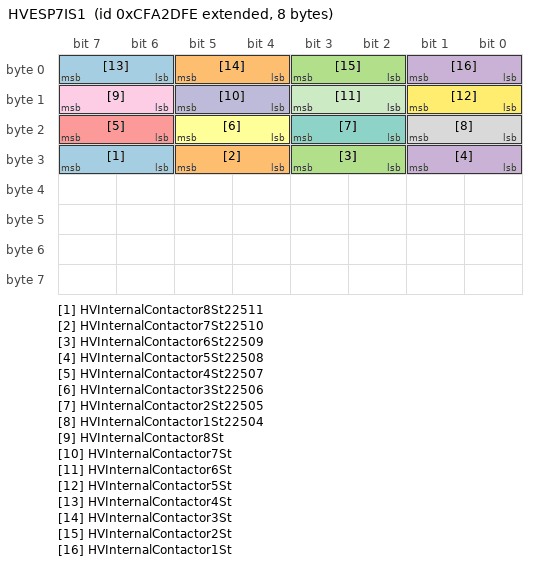
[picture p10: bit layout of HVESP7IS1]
BO_ 2365206014 HVESP7IS1: 8 Vector__XXX
 SG_ HVInternalContactor8St22511 : 30|2@1+ (1,0) [0|3] "" Vector__XXX
 SG_ HVInternalContactor7St22510 : 28|2@1+ (1,0) [0|3] "" Vector__XXX
 SG_ HVInternalContactor6St22509 : 26|2@1+ (1,0) [0|3] "" Vector__XXX
 SG_ HVInternalContactor5St22508 : 24|2@1+ (1,0) [0|3] "" Vector__XXX
 SG_ HVInternalContactor4St22507 : 22|2@1+ (1,0) [0|3] "" Vector__XXX
 SG_ HVInternalContactor3St22506 : 20|2@1+ (1,0) [0|3] "" Vector__XXX
 SG_ HVInternalContactor2St22505 : 18|2@1+ (1,0) [0|3] "" Vector__XXX
 SG_ HVInternalContactor1St22504 : 16|2@1+ (1,0) [0|3] "" Vector__XXX
 SG_ HVInternalContactor8St : 14|2@1+ (1,0) [0|3] "" Vector__XXX
 SG_ HVInternalContactor7St : 12|2@1+ (1,0) [0|3] "" Vector__XXX
 SG_ HVInternalContactor6St : 10|2@1+ (1,0) [0|3] "" Vector__XXX
 SG_ HVInternalContactor5St : 8|2@1+ (1,0) [0|3] "" Vector__XXX
 SG_ HVInternalContactor4St : 6|2@1+ (1,0) [0|3] "" Vector__XXX
 SG_ HVInternalContactor3St : 4|2@1+ (1,0) [0|3] "" Vector__XXX
 SG_ HVInternalContactor2St : 2|2@1+ (1,0) [0|3] "" Vector__XXX
 SG_ HVInternalContactor1St : 0|2@1+ (1,0) [0|3] "" Vector__XXX

CM_ BU_ PowertrainControlModule "Electronic control module in charge of controlling and coordinating the operation of a hybrid propulsion system.";
CM_ BU_ HitchControl "Straight truck hitch (NOT Agricultural hitch – it is in IG 2) ";
CM_ BO_ 3221225472 "This is a message for not used signals, created by Vector CANdb++ DBC OLE DB Provider.";
CM_ SG_ 3221225472 SourceAddress "Instance of a Source Address listed a Network Message data field.";
CM_ SG_ 3221225472 NncntnuslyMonitoredSystemsStatus "Identifies the non-continuously monitored systems status. Each bit identifies whether a particular test is complete for a given controller.
";
CM_ SG_ 3221225472 NncntnslyMonitoredSystemsSupport "Identifies the non-continuously monitored systems support.
";
CM_ SG_ 3221225472 CntnslyMntrdSystmsSupport_Status "Identifies the continuously monitored system support and status.
";
CM_ SG_ 3221225472 AETCTorqueValue "Engine torque value of the data points in PGN 64912 – Advertised Engine Torque Curve (AETC).";
CM_ SG_ 3221225472 TrailerWeight "Total mass of freight-carrying vehicle designed to be pulled by truck, including the weight of the contents.";
CM_ SG_ 3221225472 ReferenceTirePressSetting "Reference value of the tire pressure setting as basis for the tire pressure monitoring ...";
CM_ SG_ 3221225472 ReferenceTirePress "Reference value of the tire pressure as basis for the tire pressure monitoring ...";
CM_ SG_ 3221225472 TirePressThresholdDetection "Signal indicating the pressure level of the tire.  The levels defined represent different pressure conditions of the tire: 000 Extreme over pressure - The tire pressure is at a level where the safety of the vehicle may be jeopardised.";
CM_ SG_ 3221225472 TireAirLeakageRate "The pressure loss rate of a tire.";
CM_ SG_ 3221225472 CTIWheelEndElectricalFault "Indicates the status of electrical fault on CTI wheel interface.";
CM_ SG_ 3221225472 CTITireStatus "Indicates the status of the tire.";
CM_ SG_ 3221225472 CTIWheelSensorStatus "Indicates whether the wheel is being monitored by the CTI controller.";
CM_ SG_ 3221225472 TireTemp "Temperature at the surface of the tire sidewall.";
CM_ SG_ 3221225472 TirePress "Pressure at which air is contained in cavity formed by tire and rim.";
CM_ SG_ 3221225472 EngTurningGearEngaged "Status signal which indicates that the turning gear is engaged.  The turning gear is used to turn the flywheel/crankshaft, ...";
CM_ SG_ 3221225472 AETCSpeedValue "Engine speed value of the data points in PGN 64912 – Advertised Engine Torque Curve (AETC).";
CM_ BO_ 2365342974 "High Voltage Energy Storage System Data 15
Data set 15 (electrical data) for High Voltage Energy Storage System (or Pack 1 in systems with only one pack).";
CM_ SG_ 2365342974 NomChargeCurLmt "The nominal current flow limit into the High Voltage Energy Storage System (or Pack 1 in systems with only one pack).  This limit is a preferred boundary for normal operation.  Operating within this limit reduces negative impacts on battery life or ...";
CM_ SG_ 2365342974 NomDisCurLmt "The nominal current flow limit out of the High Voltage Energy Storage System (or Pack 1 in systems with only one pack).  This limit is a preferred boundary for normal operation.  Operating within this limit reduces negative impacts on battery life ...";
CM_ BO_ 2566662398 "Cruise Control / Vehicle Speed 6
Cruise Control / Vehicle Speed 6";
CM_ SG_ 2566662398 MapBasedVSLmt "The vehicle speed limit provided by digital map data.
Parameter Specific Indicator: A value of FB00h indicates there is not a speed limit provided by the map for the current location.
Note:  See SPN 21793 (Traffic Sign Speed Limit) for road sign ...";
CM_ SG_ 2566662398 CurRoadwayVSLmt "The vehicle speed limit in effect will be provided in Current Roadway Vehicle Speed Limit when the Current Roadway Vehicle Speed Limit Mode is 010b (Active).  This parameter may be used for operator displays if Current Roadway Vehicle Speed Limit ...";
CM_ SG_ 2566662398 SelectedRoadwayVSLmt "The value in this parameter defines a pending change in Current Roadway Vehicle Speed Limit when Current Roadway Vehicle Speed Limit Mode is 010b (Active) or 000b (Disabled).  This parameter may be used for operator displays of an upcoming vehicle ...";
CM_ SG_ 2566662398 CurRoadwayVSLmtMode "This signal indicates if current roadway vehicle speed is actively applied.
0000b = Disabled
0001b = Inactive
0010b = Active
0011b = Operator Override
0100b = Reserved
0101b = Reserved
0110b = Reserved
0111b = Reserved
1000b = Reserved
 ...";
CM_ BO_ 2365334014 "High Voltage Energy Storage System Module Status 3
Module Status message 3 for High Voltage Energy Storage System (or Pack 1 in systems with only one pack).";
CM_ SG_ 2365334014 Module96OperationalSt "Operational Status of Module 96 in the High Voltage Energy Storage System (or Pack 1 in systems with only one pack). Not Operational is used when the module is initializing or not able to function (e.g. internal module level monitors have failed) ...";
CM_ SG_ 2365334014 Module95OperationalSt "Operational Status of Module 95 in the High Voltage Energy Storage System (or Pack 1 in systems with only one pack). Not Operational is used when the module is initializing or not able to function (e.g. internal module level monitors have failed) ...";
CM_ SG_ 2365334014 Module94OperationalSt "Operational Status of Module 94 in the High Voltage Energy Storage System (or Pack 1 in systems with only one pack). Not Operational is used when the module is initializing or not able to function (e.g. internal module level monitors have failed) ...";
CM_ SG_ 2365334014 Module93OperationalSt "Operational Status of Module 93 in the High Voltage Energy Storage System (or Pack 1 in systems with only one pack). Not Operational is used when the module is initializing or not able to function (e.g. internal module level monitors have failed) ...";
CM_ SG_ 2365334014 Module92OperationalSt "Operational Status of Module 92 in the High Voltage Energy Storage System (or Pack 1 in systems with only one pack). Not Operational is used when the module is initializing or not able to function (e.g. internal module level monitors have failed) ...";
CM_ SG_ 2365334014 Module91OperationalSt "Operational Status of Module 91 in the High Voltage Energy Storage System (or Pack 1 in systems with only one pack). Not Operational is used when the module is initializing or not able to function (e.g. internal module level monitors have failed) ...";
CM_ SG_ 2365334014 Module90OperationalSt "Operational Status of Module 90 in the High Voltage Energy Storage System (or Pack 1 in systems with only one pack). Not Operational is used when the module is initializing or not able to function (e.g. internal module level monitors have failed) ...";
CM_ SG_ 2365334014 Module89OperationalSt "Operational Status of Module 89 in the High Voltage Energy Storage System (or Pack 1 in systems with only one pack). Not Operational is used when the module is initializing or not able to function (e.g. internal module level monitors have failed) ...";
CM_ SG_ 2365334014 Module88OperationalSt "Operational Status of Module 88 in the High Voltage Energy Storage System (or Pack 1 in systems with only one pack). Not Operational is used when the module is initializing or not able to function (e.g. internal module level monitors have failed) ...";
CM_ SG_ 2365334014 Module87OperationalSt "Operational Status of Module 87 in the High Voltage Energy Storage System (or Pack 1 in systems with only one pack). Not Operational is used when the module is initializing or not able to function (e.g. internal module level monitors have failed) ...";
CM_ SG_ 2365334014 Module86OperationalSt "Operational Status of Module 86 in the High Voltage Energy Storage System (or Pack 1 in systems with only one pack). Not Operational is used when the module is initializing or not able to function (e.g. internal module level monitors have failed) ...";
CM_ SG_ 2365334014 Module85OperationalSt "Operational Status of Module 85 in the High Voltage Energy Storage System (or Pack 1 in systems with only one pack). Not Operational is used when the module is initializing or not able to function (e.g. internal module level monitors have failed) ...";
CM_ SG_ 2365334014 Module84OperationalSt "Operational Status of Module 84 in the High Voltage Energy Storage System (or Pack 1 in systems with only one pack). Not Operational is used when the module is initializing or not able to function (e.g. internal module level monitors have failed) ...";
CM_ SG_ 2365334014 Module83OperationalSt "Operational Status of Module 83 in the High Voltage Energy Storage System (or Pack 1 in systems with only one pack). Not Operational is used when the module is initializing or not able to function (e.g. internal module level monitors have failed) ...";
CM_ SG_ 2365334014 Module82OperationalSt "Operational Status of Module 82 in the High Voltage Energy Storage System (or Pack 1 in systems with only one pack). Not Operational is used when the module is initializing or not able to function (e.g. internal module level monitors have failed) ...";
CM_ SG_ 2365334014 Module81OperationalSt "Operational Status of Module 81 in the High Voltage Energy Storage System (or Pack 1 in systems with only one pack). Not Operational is used when the module is initializing or not able to function (e.g. internal module level monitors have failed) ...";
CM_ SG_ 2365334014 Module80OperationalSt "Operational Status of Module 80 in the High Voltage Energy Storage System (or Pack 1 in systems with only one pack). Not Operational is used when the module is initializing or not able to function (e.g. internal module level monitors have failed) ...";
CM_ SG_ 2365334014 Module79OperationalSt "Operational Status of Module 79 in the High Voltage Energy Storage System (or Pack 1 in systems with only one pack). Not Operational is used when the module is initializing or not able to function (e.g. internal module level monitors have failed) ...";
CM_ SG_ 2365334014 Module78OperationalSt "Operational Status of Module 78 in the High Voltage Energy Storage System (or Pack 1 in systems with only one pack). Not Operational is used when the module is initializing or not able to function (e.g. internal module level monitors have failed) ...";
CM_ SG_ 2365334014 Module77OperationalSt "Operational Status of Module 77 in the High Voltage Energy Storage System (or Pack 1 in systems with only one pack). Not Operational is used when the module is initializing or not able to function (e.g. internal module level monitors have failed) ...";
CM_ SG_ 2365334014 Module76OperationalSt "Operational Status of Module 76 in the High Voltage Energy Storage System (or Pack 1 in systems with only one pack). Not Operational is used when the module is initializing or not able to function (e.g. internal module level monitors have failed) ...";
CM_ SG_ 2365334014 Module75OperationalSt "Operational Status of Module 75 in the High Voltage Energy Storage System (or Pack 1 in systems with only one pack). Not Operational is used when the module is initializing or not able to function (e.g. internal module level monitors have failed) ...";
CM_ SG_ 2365334014 Module74OperationalSt "Operational Status of Module 74 in the High Voltage Energy Storage System (or Pack 1 in systems with only one pack). Not Operational is used when the module is initializing or not able to function (e.g. internal module level monitors have failed) ...";
CM_ SG_ 2365334014 Module73OperationalSt "Operational Status of Module 73 in the High Voltage Energy Storage System (or Pack 1 in systems with only one pack). Not Operational is used when the module is initializing or not able to function (e.g. internal module level monitors have failed) ...";
CM_ SG_ 2365334014 Module72OperationalSt "Operational Status of Module 72 in the High Voltage Energy Storage System (or Pack 1 in systems with only one pack). Not Operational is used when the module is initializing or not able to function (e.g. internal module level monitors have failed) ...";
CM_ SG_ 2365334014 Module71OperationalSt "Operational Status of Module 71 in the High Voltage Energy Storage System (or Pack 1 in systems with only one pack). Not Operational is used when the module is initializing or not able to function (e.g. internal module level monitors have failed) ...";
CM_ SG_ 2365334014 Module70OperationalSt "Operational Status of Module 70 in the High Voltage Energy Storage System (or Pack 1 in systems with only one pack). Not Operational is used when the module is initializing or not able to function (e.g. internal module level monitors have failed) ...";
CM_ SG_ 2365334014 Module69OperationalSt "Operational Status of Module 69 in the High Voltage Energy Storage System (or Pack 1 in systems with only one pack). Not Operational is used when the module is initializing or not able to function (e.g. internal module level monitors have failed) ...";
CM_ SG_ 2365334014 Module68OperationalSt "Operational Status of Module 68 in the High Voltage Energy Storage System (or Pack 1 in systems with only one pack). Not Operational is used when the module is initializing or not able to function (e.g. internal module level monitors have failed) ...";
CM_ SG_ 2365334014 Module67OperationalSt "Operational Status of Module 67 in the High Voltage Energy Storage System (or Pack 1 in systems with only one pack). Not Operational is used when the module is initializing or not able to function (e.g. internal module level monitors have failed) ...";
CM_ SG_ 2365334014 Module66OperationalSt "Operational Status of Module 66 in the High Voltage Energy Storage System (or Pack 1 in systems with only one pack). Not Operational is used when the module is initializing or not able to function (e.g. internal module level monitors have failed) ...";
CM_ SG_ 2365334014 Module65OperationalSt "Operational Status of Module 65 in the High Voltage Energy Storage System (or Pack 1 in systems with only one pack). Not Operational is used when the module is initializing or not able to function (e.g. internal module level monitors have failed) ...";
CM_ BO_ 2365333758 "High Voltage Energy Storage System Module Status 2
Module Status message 2 for High Voltage Energy Storage System (or Pack 1 in systems with only one pack).";
CM_ SG_ 2365333758 Module64OperationalSt "Operational Status of Module 64 in the High Voltage Energy Storage System (or Pack 1 in systems with only one pack). Not Operational is used when the module is initializing or not able to function (e.g. internal module level monitors have failed) ...";
CM_ SG_ 2365333758 Module63OperationalSt "Operational Status of Module 63 in the High Voltage Energy Storage System (or Pack 1 in systems with only one pack). Not Operational is used when the module is initializing or not able to function (e.g. internal module level monitors have failed) ...";
CM_ SG_ 2365333758 Module62OperationalSt "Operational Status of Module 62 in the High Voltage Energy Storage System (or Pack 1 in systems with only one pack). Not Operational is used when the module is initializing or not able to function (e.g. internal module level monitors have failed) ...";
CM_ SG_ 2365333758 Module61OperationalSt "Operational Status of Module 61 in the High Voltage Energy Storage System (or Pack 1 in systems with only one pack). Not Operational is used when the module is initializing or not able to function (e.g. internal module level monitors have failed) ...";
CM_ SG_ 2365333758 Module60OperationalSt "Operational Status of Module 60 in the High Voltage Energy Storage System (or Pack 1 in systems with only one pack). Not Operational is used when the module is initializing or not able to function (e.g. internal module level monitors have failed) ...";
CM_ SG_ 2365333758 Module59OperationalSt "Operational Status of Module 59 in the High Voltage Energy Storage System (or Pack 1 in systems with only one pack). Not Operational is used when the module is initializing or not able to function (e.g. internal module level monitors have failed) ...";
CM_ SG_ 2365333758 Module58OperationalSt "Operational Status of Module 58 in the High Voltage Energy Storage System (or Pack 1 in systems with only one pack). Not Operational is used when the module is initializing or not able to function (e.g. internal module level monitors have failed) ...";
CM_ SG_ 2365333758 Module57OperationalSt "Operational Status of Module 57 in the High Voltage Energy Storage System (or Pack 1 in systems with only one pack). Not Operational is used when the module is initializing or not able to function (e.g. internal module level monitors have failed) ...";
CM_ SG_ 2365333758 Module56OperationalSt "Operational Status of Module 56 in the High Voltage Energy Storage System (or Pack 1 in systems with only one pack). Not Operational is used when the module is initializing or not able to function (e.g. internal module level monitors have failed) ...";
CM_ SG_ 2365333758 Module55OperationalSt "Operational Status of Module 55 in the High Voltage Energy Storage System (or Pack 1 in systems with only one pack). Not Operational is used when the module is initializing or not able to function (e.g. internal module level monitors have failed) ...";
CM_ SG_ 2365333758 Module54OperationalSt "Operational Status of Module 54 in the High Voltage Energy Storage System (or Pack 1 in systems with only one pack). Not Operational is used when the module is initializing or not able to function (e.g. internal module level monitors have failed) ...";
CM_ SG_ 2365333758 Module53OperationalSt "Operational Status of Module 53 in the High Voltage Energy Storage System (or Pack 1 in systems with only one pack). Not Operational is used when the module is initializing or not able to function (e.g. internal module level monitors have failed) ...";
CM_ SG_ 2365333758 Module52OperationalSt "Operational Status of Module 52 in the High Voltage Energy Storage System (or Pack 1 in systems with only one pack). Not Operational is used when the module is initializing or not able to function (e.g. internal module level monitors have failed) ...";
CM_ SG_ 2365333758 Module51OperationalSt "Operational Status of Module 51 in the High Voltage Energy Storage System (or Pack 1 in systems with only one pack). Not Operational is used when the module is initializing or not able to function (e.g. internal module level monitors have failed) ...";
CM_ SG_ 2365333758 Module50OperationalSt "Operational Status of Module 50 in the High Voltage Energy Storage System (or Pack 1 in systems with only one pack). Not Operational is used when the module is initializing or not able to function (e.g. internal module level monitors have failed) ...";
CM_ SG_ 2365333758 Module49OperationalSt "Operational Status of Module 49 in the High Voltage Energy Storage System (or Pack 1 in systems with only one pack). Not Operational is used when the module is initializing or not able to function (e.g. internal module level monitors have failed) ...";
CM_ SG_ 2365333758 Module48OperationalSt "Operational Status of Module 48 in the High Voltage Energy Storage System (or Pack 1 in systems with only one pack). Not Operational is used when the module is initializing or not able to function (e.g. internal module level monitors have failed) ...";
CM_ SG_ 2365333758 Module47OperationalSt "Operational Status of Module 47 in the High Voltage Energy Storage System (or Pack 1 in systems with only one pack). Not Operational is used when the module is initializing or not able to function (e.g. internal module level monitors have failed) ...";
CM_ SG_ 2365333758 Module46OperationalSt "Operational Status of Module 46 in the High Voltage Energy Storage System (or Pack 1 in systems with only one pack). Not Operational is used when the module is initializing or not able to function (e.g. internal module level monitors have failed) ...";
CM_ SG_ 2365333758 Module45OperationalSt "Operational Status of Module 45 in the High Voltage Energy Storage System (or Pack 1 in systems with only one pack). Not Operational is used when the module is initializing or not able to function (e.g. internal module level monitors have failed) ...";
CM_ SG_ 2365333758 Module44OperationalSt "Operational Status of Module 44 in the High Voltage Energy Storage System (or Pack 1 in systems with only one pack). Not Operational is used when the module is initializing or not able to function (e.g. internal module level monitors have failed) ...";
CM_ SG_ 2365333758 Module43OperationalSt "Operational Status of Module 43 in the High Voltage Energy Storage System (or Pack 1 in systems with only one pack). Not Operational is used when the module is initializing or not able to function (e.g. internal module level monitors have failed) ...";
CM_ SG_ 2365333758 Module42OperationalSt "Operational Status of Module 42 in the High Voltage Energy Storage System (or Pack 1 in systems with only one pack). Not Operational is used when the module is initializing or not able to function (e.g. internal module level monitors have failed) ...";
CM_ SG_ 2365333758 Module41OperationalSt "Operational Status of Module 41 in the High Voltage Energy Storage System (or Pack 1 in systems with only one pack). Not Operational is used when the module is initializing or not able to function (e.g. internal module level monitors have failed) ...";
CM_ SG_ 2365333758 Module40OperationalSt "Operational Status of Module 40 in the High Voltage Energy Storage System (or Pack 1 in systems with only one pack). Not Operational is used when the module is initializing or not able to function (e.g. internal module level monitors have failed) ...";
CM_ SG_ 2365333758 Module39OperationalSt "Operational Status of Module 39 in the High Voltage Energy Storage System (or Pack 1 in systems with only one pack). Not Operational is used when the module is initializing or not able to function (e.g. internal module level monitors have failed) ...";
CM_ SG_ 2365333758 Module38OperationalSt "Operational Status of Module 38 in the High Voltage Energy Storage System (or Pack 1 in systems with only one pack). Not Operational is used when the module is initializing or not able to function (e.g. internal module level monitors have failed) ...";
CM_ SG_ 2365333758 Module37OperationalSt "Operational Status of Module 37 in the High Voltage Energy Storage System (or Pack 1 in systems with only one pack). Not Operational is used when the module is initializing or not able to function (e.g. internal module level monitors have failed) ...";
CM_ SG_ 2365333758 Module36OperationalSt "Operational Status of Module 36 in the High Voltage Energy Storage System (or Pack 1 in systems with only one pack). Not Operational is used when the module is initializing or not able to function (e.g. internal module level monitors have failed) ...";
CM_ SG_ 2365333758 Module35OperationalSt "Operational Status of Module 35 in the High Voltage Energy Storage System (or Pack 1 in systems with only one pack). Not Operational is used when the module is initializing or not able to function (e.g. internal module level monitors have failed) ...";
CM_ SG_ 2365333758 Module34OperationalSt "Operational Status of Module 34 in the High Voltage Energy Storage System (or Pack 1 in systems with only one pack). Not Operational is used when the module is initializing or not able to function (e.g. internal module level monitors have failed) ...";
CM_ SG_ 2365333758 Module33OperationalSt "Operational Status of Module 33 in the High Voltage Energy Storage System (or Pack 1 in systems with only one pack). Not Operational is used when the module is initializing or not able to function (e.g. internal module level monitors have failed) ...";
CM_ BO_ 2566660094 "Vehicle Electrical Power 17
Battery discharge current limit parameter for SLI Battery Pack 1.";
CM_ SG_ 2566660094 SLIBatPack1Bat4DisCurLmt "The maximum permissible current flow out of the fourth battery in the first battery pack used for starting, lighting and ignition (SLI).";
CM_ SG_ 2566660094 SLIBatPack1Bat3DisCurLmt "The maximum permissible current flow out of the third battery in the first battery pack used for starting, lighting and ignition (SLI).";
CM_ SG_ 2566660094 SLIBatPack1Bat2DisCurLmt "The maximum permissible current flow out of the second battery in the first battery pack used for starting, lighting and ignition (SLI).";
CM_ SG_ 2566660094 SLIBatPack1Bat1DisCurLmt "The maximum permissible current flow out of the first battery in the first battery pack used for starting, lighting and ignition (SLI).";
CM_ BO_ 2566659838 "Vehicle Electrical Power 16
Battery charge current limit parameter for SLI Battery Pack 1.";
CM_ SG_ 2566659838 SLIBatPack1Bat4ChargeCurLmt "The maximum permissible current flow into fourth battery in the first battery pack used for starting, lighting and ignition (SLI).";
CM_ SG_ 2566659838 SLIBatPack1Bat3ChargeCurLmt "The maximum permissible current flow into third battery in the first battery pack used for starting, lighting and ignition (SLI).";
CM_ SG_ 2566659838 SLIBatPack1Bat2ChargeCurLmt "The maximum permissible current flow into second battery in the first battery pack used for starting, lighting and ignition (SLI).";
CM_ SG_ 2566659838 SLIBatPack1Bat1ChargeCurLmt "The maximum permissible current flow into first battery in the first battery pack used for starting, lighting and ignition (SLI).";
CM_ BO_ 2633768446 "Refrigeration Compartment Information 2
Data from the transportation refrigerated compartment.
Note that the transmitter will send its data from all compartments frame by frame each update (every 10 seconds).  One frame contains the data of one ...";
CM_ SG_ 2633768446 TransportationCompartmentDoorSt "The status of the transportation compartment door.

00b = Door open
01b = Door closed
10b = Error
11b = Not available";
CM_ SG_ 2633768446 TransportationCompartmentDoorID "The ID of the transportation compartment door.
A refrigerated container can be divided into a few compartments, usually referred to as zones (for example, zone 1, zone 2, etc.).  Each compartment could have its own door. Compartment door number can ...";
CM_ BO_ 2633768190 "Refrigeration Compartment Information 1
Data from the transportation refrigerated compartment.
Note that the transmitter will send its data from all compartments frame by frame each update (every 30 seconds).  One frame contains the data of one ...";
CM_ SG_ 2633768190 RefrigeratedCompartmentTemp "The temperature of the transportation refrigerated compartment.";
CM_ SG_ 2633768190 RefrigeratedCompartmentHumidity "The humidity of the transportation refrigerated compartment.";
CM_ SG_ 2633768190 RefrigeratedCompartmentID "The ID of the tansportation refrigerated compartment.

The ID can be the ID assigned to the compartment (zone / pallet / box, etc.), or the ID of the sensor that is put in the compartment (zone / pallet / box, etc.).";
CM_ SG_ 2633768190 RefrigeratedCompartmentPos "The position of the transportation refrigerated compartment.
There are two kinds of positions in a transportation refrigerated vehicle.
1) The first situation is a refrigerated container itself is divided into a few compartments, usually referred ...";
CM_ BO_ 2633761022 "Trailer Wheel Brake Wear Life Remaining Information
Brake wear life remaining is defined as the sum of the remaining material left on the rotor and brake pads. 100% represents new brake linings and rotor, 0% represents totally worn condition. Axle ...";
CM_ SG_ 2633761022 RemTlrAxle8RightWheel "The percentage of brake wear life remaining which can still be measured for the right wheel on trailer axle 8.";
CM_ SG_ 2633761022 RemTlrAxle8LeftWheel "The percentage of brake wear life remaining which can still be measured for the left wheel on trailer axle 8.";
CM_ SG_ 2633761022 RemTlrAxle7RightWheel "The percentage of brake wear life remaining which can still be measured for the right wheel on trailer axle 7.";
CM_ SG_ 2633761022 RemTlrAxle7LeftWheel "The percentage of brake wear life remaining which can still be measured for the left wheel on trailer axle 7.";
CM_ SG_ 2633761022 RemTlrAxle6RightWheel "The percentage of brake wear life remaining which can still be measured for the right wheel on trailer axle 6.";
CM_ SG_ 2633761022 RemTlrAxle6LeftWheel "The percentage of brake wear life remaining which can still be measured for the left wheel on trailer axle 6.";
CM_ SG_ 2633761022 RemTlrAxle5RightWheel "The percentage of brake wear life remaining which can still be measured for the right wheel on trailer axle 5.";
CM_ SG_ 2633761022 RemTlrAxle5LeftWheel "The percentage of brake wear life remaining which can still be measured for the left wheel on trailer axle 5.";
CM_ SG_ 2633761022 RemTlrAxle4RightWheel "The percentage of brake wear life remaining which can still be measured for the right wheel on trailer axle 4.";
CM_ SG_ 2633761022 RemTlrAxle4LeftWheel "The percentage of brake wear life remaining which can still be measured for the left wheel on trailer axle 4.";
CM_ SG_ 2633761022 RemTlrAxle3RightWheel "The percentage of brake wear life remaining which can still be measured for the right wheel on trailer axle 3.";
CM_ SG_ 2633761022 RemTlrAxle3LeftWheel "The percentage of brake wear life remaining which can still be measured for the left wheel on trailer axle 3.";
CM_ SG_ 2633761022 RemTlrAxle2RightWheel "The percentage of brake wear life remaining which can still be measured for the right wheel on trailer axle 2.";
CM_ SG_ 2633761022 RemTlrAxle2LeftWheel "The percentage of brake wear life remaining which can still be measured for the left wheel on trailer axle 2.";
CM_ SG_ 2633761022 RemTlrAxle1RightWheel "The percentage of brake wear life remaining which can still be measured for the right wheel on trailer axle 1.";
CM_ SG_ 2633761022 RemTlrAxle1LeftWheel "The percentage of brake wear life remaining which can still be measured for the left wheel on trailer axle 1.";
CM_ BO_ 2566648574 "Engine Fuel/Lube Systems 3
Contains information on the engine fuel and lube system.";
CM_ SG_ 2566648574 FuelFilter "Change in fuel delivery pressure, measured across the filter, due to accumulation of solid or semisolid matter on the filter element.

See SPN 1382 (Engine Fuel Filter (Suction Side) Differential Pressure) for alternate resolution.";
CM_ SG_ 2566648574 FuelFilterDiffPress "Change in fuel delivery pressure, measured across the filter, due to accumulation of solid or semisolid matter on the filter element.

See SPN 95 (Engine Fuel Filter Differential Pressure) for alternate resolution.";
CM_ BO_ 2566584574 "Engine Maximum Net Torque Map
This is the maximum net torque map of the engine.  Included in this map will be steady state derates.  For applications that support more than one maximum net torque map, multiple instances of this PG shall be ...";
CM_ SG_ 2566584574 TrqValue "Engine torque value for the torque map data point that corresponds to the paired engine speed value (SPN 22716).  This is for one map data point of the total number of points in this torque map, as specified by the SPN 22711 (Engine Maximum Net ...";
CM_ SG_ 2566584574 SpdValue "Engine speed value for the torque map data point that corresponds to the paired engine torque value (SPN 22717).  This is for one map data point of the total number of points in this torque map, as specified by the SPN 22711 (Engine Maximum Net ...";
CM_ SG_ 2566584574 ReferenceNetTrq "The 100% reference value for engine net torque values (SPN 22717) reported in all instances of the PG from a reporting application.  All torque maps shall use the same value for this parameter.";
CM_ SG_ 2566584574 ActiveDerate "Indicates if the active net torque map identified in SP 22713 has had a derate applied.  This could include a torque derate and/or a speed derate.
00b - No derate has been applied to the active net torque map
01b - A derate has been applied to the ...";
CM_ SG_ 2566584574 TotalCount "The total count of net torque maps supported by this application and reported in this message.";
CM_ SG_ 2566584574 ActiveInstance "This number identifies the active net torque map instance.";
CM_ SG_ 2566584574 Instance "Unique identifier for the torque map described in this PG instance.  When an application reports only one torque map, this value shall always be set to 1.  When an application reports multiple torque maps, each torque map shall have a unique value ...";
CM_ SG_ 2566584574 NumOfPoints "Indicates the number of speed / net torque data points conveyed.  A minimum of 2 points is required, with a maximum of 15 points available as needed to accurately convey the curve.  The number of points for a given net torque map should not change ...";
CM_ BO_ 2566537214 "Engine Configuration 4
Contains static information about the engine. To be used with data that will not change during operation.";
CM_ SG_ 2566537214 CoolingFanInManifoldActTemp "Indicates the intake manifold temperature at which the engine cooling fan is activated at 100 percent.";
CM_ SG_ 2566537214 CoolingFanCoolantActTemp "Indicates the engine coolant temperature at which the engine cooling fan is activated at 100 percent.";
CM_ BO_ 2499428094 "Traffic Signage
Traffic Sign Information";
CM_ SG_ 2499428094 SignSpdLmt "Indicates the traffic sign speed limit as currently detected by a camera on one of the vehicle devices.
See SPN 22773 (Map Based Vehicle Speed Limit) for digital map speed limit data.
Parameter Specific Indicator:
A value of FB00h indicates a ...";
CM_ BO_ 2566536702 "Gaseous Fuel Supply Pressure 3
Transmits information on pressures at various points of Gaseous fuel supplied to the engine.";
CM_ SG_ 2566536702 GasFuel2SupplyPressRegPos "Position of regulator valve, which is used to control the flow of the second gaseous fuel through the fuel supply unit. 0% represents valve fully closed and 100% represents valve fully open.";
CM_ SG_ 2566536702 GasFuel1SupplyPressRegPos "Position of regulator valve, which is used to control the flow of gaseous fuel through the fuel supply unit. 0% represents valve fully closed and 100% represents valve fully open.";
CM_ SG_ 2566536702 GasFuel2SupplyPressRegOutPress "The pressure of the second gaseous fuel at the outlet of the pressure regulator.";
CM_ SG_ 2566536702 GasFuel1SupplyPressRegOutPress "The pressure of the first gaseous fuel at the outlet of the pressure regulator.";
CM_ SG_ 2566536702 GasFuel2SupplyPress1 "The pressure of the second gaseous fuel measured by first pressure sensor in the primary, as delivered from the supply pump to the injector metering intake.";
CM_ BO_ 2566536446 "Engine Exhaust O2 Sensor  Information
Engine Exhaust O2 Sensor Information";
CM_ SG_ 2566536446 TwoV "O2 sensor 2 voltage.
Note:  J1979 equivalent (PID F414) for O2 sensor 1 Air/Fuel equivalence ratio. See Emission Remote Supervision System of Heavy-Duty Vehicles HJ 1239.3 document (China Regulation) for more information.
A value of FB00h shall be ...";
CM_ SG_ 2566536446 TwoAir_FuelEquivalenceRatio "Sensor 2 actual air fuel ratio to desired air fuel ratio in the exhaust gas that controls the intake air flow.
Note:  See Emission Remote Supervision System of Heavy-Duty Vehicles HJ 1239.3 document (China Regulation) for more information.
A value ...";
CM_ SG_ 2566536446 OneV "O2 sensor 1 voltage.
Note:  See Emission Remote Supervision System of Heavy-Duty Vehicles HJ 1239.3 document (China Regulation) for more information.
A value of FB00h shall be provided when ambient or engine operating conditions do not permit the ...";
CM_ SG_ 2566536446 OneAir_FuelEquivalenceRatio "Sensor 1 actual air fuel ratio to desired air fuel ratio in the exhaust gas that controls the intake air flow.
Note:  J1979 equivalent (PID F444) for O2 sensor 1 Air/Fuel equivalence ratio. See Emission Remote Supervision System of Heavy-Duty ...";
CM_ BO_ 2566536190 "Electric PTO 1 Information
Information relating to the operational parameters of ePTO equipment.";
CM_ SG_ 2566536190 EPTO1V "Voltage applied at the ePTO equipment terminals";
CM_ SG_ 2566536190 EPTO1Cur "Actual current consumed by ePTO equipment";
CM_ SG_ 2566536190 EPTO1CurLmt "Maximum current ePTO equipment is allowed to draw.";
CM_ BO_ 2566535934 "Electric PTO Drive Engagement 1
Information relating to the request for engagement, consent for engagement, and status of engagement of various specific electric PTO equipment.  This message may be broadcast by one or all controllers involved in ...";
CM_ SG_ 2566535934 ErrorIndEPTO1 "Signal to the operator that some ePTO error exists, such as failed to activate when requested

00b = no ePTO error detected or ePTO not enabled
01b = ePTO error detected
10b = Reserved
11b = Not available";
CM_ SG_ 2566535934 SysReadinessEPTO1 "Indicates availability of the power source to energize ePTO equipment or operational readiness of ePTO equipment to be energized

00b = ePTO not available due to system error
01b = ePTO available
10b = Reserved
11b = Not available";
CM_ SG_ 2566535934 EmergDeEnergizeSwEPTO1 "Initiates emergency shutdown procedure as appropriate to the application, which may include active discharge of ePTO bus.

00b = Emergency De-energize not active
01b = Emergency De-energize active - initiate shutdown
10b = Error
11b = Not available";
CM_ SG_ 2566535934 EngagementStEPTO1 "Indicates whether electric power is applied to the ePTO equipment.

00b = Drive not activated or \"engaged\"
01b = Drive is activated or \"engaged\"
10b = Error
11b = Not available";
CM_ SG_ 2566535934 EngagementConsentEPTO1 "Indicates equipment controller's consent to activate or \"engage\" the high voltage ePTO.  The vehicle controller may only apply high voltage to ePTO equipment when consent is given.  Removal of consent initiates normal power down. Lack of consent may ...";
CM_ SG_ 2566535934 EnableSwEPTO1 "Status of the operator's switch or other input on vehicle which indicates the desire for activating or \"engaging\" the ePTO equipment
00b = Enable switch off - ePTO operation not desired
01b = Enable switch on - ePTO operation desired
10b = Error
 ...";
CM_ SG_ 2566535934 Counter "The message counter is used to detect situations where the transmitting ECU malfunction repeats the same frame all the time. The receiver of the information may use the counter parameter to detect this situation. The transmitting device will ...";
CM_ SG_ 2566535934 CRC "The CRC is defined as follows:
• Length: 8 bits
• Polynomial: x^8+x^5+x^3+x^2+x+1
• Initial Value: FFh
• Input Data Reflection: Not reflected
• Result Data Reflection: Not reflected
• XOR value: FFh
SAE makes no claim of the functional safety ...";
CM_ BO_ 2566535678 "Well Stimulation Pump Protection System Configuration Command 2
Used to configure threshold and operating parameters of a well simulation pump used in oil and gas drilling applications.";
CM_ SG_ 2566535678 OutPressProtLvlActiveSt "Used to indicate the active outlet pressure protection status of well stimulation system.
0000b = Not in use
0001b = Outlet Pressure Protection Waiting
0010b = Outlet Pressure Protection Level 1 Active
0011b = Outlet Pressure Protection Level 2 ...";
CM_ SG_ 2566535678 InitialRampGainFactor "Used to adjust the Level 1 thru Level 5 gain factor implemented in pressure protection feature on detection on ramp from neutral/park to pumping operations.";
CM_ SG_ 2566535678 DisPressRespLvl5Factor "Used to adjust the response after crossing level 5 pressure protection indicated in SPN 22203 (Well Stimulation Pump Outlet Pressure Level 5 Percent)";
CM_ SG_ 2566535678 DisPressRespLvl4Factor "Used to adjust the response after crossing level 4 pressure protection indicated in SPN 22202 (Well Stimulation Pump Outlet Pressure Level 4 Percent)";
CM_ SG_ 2566535678 DisPressRespLvl3Factor "Used to adjust the response after crossing level 3 pressure protection indicated in SPN 22201 (Well Stimulation Pump Outlet Pressure Level 3 Percent)";
CM_ SG_ 2566535678 DisPressRespLvl2Factor "Used to adjust the response after crossing level 2 pressure protection indicated in SPN 22200 (Well Stimulation Pump Outlet Pressure Level 2 Percent)";
CM_ SG_ 2566535678 DisPressRespLvl1Factor "Used to adjust the response after crossing level 1 pressure protection indicated in SPN 22199 (Well Stimulation Pump Outlet Pressure Level 1 Percent)";
CM_ BO_ 2566535422 "Well Stimulation Pump Protection System Configuration Command 1
Used to configure threshold and operating parameters of a well simulation pump used in oil and gas drilling applications.";
CM_ SG_ 2566535422 SysCtrlEnableSt "Indicates whether the main controller application used for the well stimulation system is enabled or disabled.

00b = Disabled
01b = Enabled
10b = Reserved
11b = Not Available";
CM_ SG_ 2566535422 OutPressDiffFromAvg "Indicates whether a pump outlet pressure difference has been detected between a fracking trailer pressure sensor compared against the well stimulation pad average.
00b = No Outlet Pressure Discrepancy Detected
01b = Outlet Pressure Discrepancy ...";
CM_ SG_ 2566535422 PadOperatingPressUpperLmt "Outlet pressure limit of the well stimulation pad.";
CM_ SG_ 2566535422 OutPressLvl5Percent "Outlet pressure percent level 5 used to trigger level 5 response in a pump protection system.";
CM_ SG_ 2566535422 OutPressLvl4Percent "Outlet pressure percent level 4 used to trigger level 4 response in a pump protection system.";
CM_ SG_ 2566535422 OutPressLvl3Percent "Outlet pressure percent level 3 used to trigger level 3 response in a pump protection system.";
CM_ SG_ 2566535422 OutPressLvl2Percent "Outlet pressure percent level 2 used to trigger level 2 response in a pump protection system.";
CM_ SG_ 2566535422 OutPressLvl1Percent "Outlet pressure percent level 1 used to trigger level 1 response in a pump protection system.";
CM_ BO_ 2566535166 "Well Stimulation Transmission Control
Parameters related to the transmission control of fracking trailer.";
CM_ SG_ 2566535166 TSC1EngCtrlAbortCmd "Command for the transmission to stop broadcasting TSC1 messages to the engine. Parameter is only intended for well stimulation applications.

00b = Abort Not Requested
01b = Abort requested
10b = Reserved
11b = Don't Care / Take No Action";
CM_ SG_ 2566535166 PumpDriveType "Pressure high limit of a outlet pump connected to a well stimulation transmission.

00b = Not Configured
01b = Mechincal Drive
10b = Electrical Drive
11b = Not Supported";
CM_ SG_ 2566535166 PumpOutPressHiLmt "Pressure high limit of a outlet pump connected to a well stimulation transmission";
CM_ SG_ 2566535166 LFCtrlHoldSt "Indicates the transition from normal operation, automatic transmission shift control logic, to low flow operation where the transmission output speed will lock the current output speed.

00b = Inactive
01b = Active
10b = Error
11b = Not Available";
CM_ SG_ 2566535166 LFCtrlDesSpdInputConfig "Indicates which input configuration is used for transmissions equipped with low flow control for well stimulation.

00b = Hardwired
01b = SAE J1939
10b = Error
11b = Not Available";
CM_ SG_ 2566535166 LFCtrlInputConfig "Indicates the input configuration of transmissions equipped with low flow control software.

00b = Hardwired
01b = SAE J1939
10b = Error
11b = Not Available";
CM_ SG_ 2566535166 LFCtrlInstallation "Indicates whether the transmission low flow control feature is installed.

00b = Not Installed
01b = Installed
10b = Error
11b = Not Available";
CM_ BO_ 2566534910 "Engine Fluid Level/Pressure 14
14th PG which identifies parameters that are either measuring various pressures within the engine.";
CM_ SG_ 2566534910 ThrotVlv2OutAbsPress "Absolute pressure of air measured downstream of the discharge side of the second throttle valve.";
CM_ SG_ 2566534910 ThrotVlv2OutPress "Gage pressure of air measured downstream of the discharge side of the second throttle valve.";
CM_ SG_ 2566534910 ThrotVlv1OutAbsPress "Absolute pressure of air measured downstream of the discharge side of the first throttle valve.";
CM_ SG_ 2566534910 ThrotVlv1OutPress "Gage pressure of air measured downstream of the discharge side of the first throttle valve.";
CM_ BO_ 2499425790 "Refuse Truck Body Information
Communicates the status and positions of refuse truck equipment";
CM_ SG_ 2499425790 Overheight_OverwidthSt "Indicates whether arms, forks, or other equipment has been detected as in an overheight/overwidth condition

00b = no overheight/overwidth condition detected
01b = overheight/overwidth condition detected
10b = Error
11b = Not Available";
CM_ SG_ 2499425790 TailgatePos "Indicates the position of the tailgate.

00b = tailgate is not closed
01b = tailgate is closed
10b = Error
11b = Not Available";
CM_ SG_ 2499425790 FrontLoaderForkPos "Indicates the position of the front loader forks of a refuse truck.

00b = forks are not tucked
01b = forks are tucked
10b = Error
11b = Not Available";
CM_ SG_ 2499425790 FrontLoaderArmPos "Indicates the position of the front loader arms of a refuse truck.
0000b = arms are lowered
0001b = arms are above cab
0010b = reserved
0011b = reserved
0100b = reserved
0101b = reserved
0110b = reserved
0111b = reserved
1000b = reserved
 ...";
CM_ SG_ 2499425790 TransitSt "Indicates whether refuse body equipment is in a transit position.

00b = arms, forks, or other equipment is not in transit position
01b = arms, forks, and other equipment are ready for transit
10b = Error
11b = Not Available";
CM_ BO_ 2365207806 "Multi-Color Indicator Lamp Status
Indicates the status of the multi-color indicator lamp.";
CM_ SG_ 2365207806 GeneralFault "Used to communicate general faults on multi-color indicator lamp.
0000b = No Fault
0001b = Out of Sync with other lamps
0010b = Command message not received
0011b = Reserved
0100b = Reserved
0101b = Reserved
0110b = Reserved
0111b = Reserved
 ...";
CM_ SG_ 2365207806 Color14St "Used to indicate status of Color 14 in the multi-color indicator lamp.
0000b = No Fault
0001b = Color On Fault (Commanded off)
0010b = Color Off fault (Commanded on)
0011b = Low Brightness
0100b = High Brightness
0101b = LED chipset failure
 ...";
CM_ SG_ 2365207806 Color13St "Used to indicate status of Color 13 in the multi-color indicator lamp.
0000b = No Fault
0001b = Color On Fault (Commanded off)
0010b = Color Off fault (Commanded on)
0011b = Low Brightness
0100b = High Brightness
0101b = LED chipset failure
 ...";
CM_ SG_ 2365207806 Color12St "Used to indicate status of Color 12 in the multi-color indicator lamp.
0000b = No Fault
0001b = Color On Fault (Commanded off)
0010b = Color Off fault (Commanded on)
0011b = Low Brightness
0100b = High Brightness
0101b = LED chipset failure
 ...";
CM_ SG_ 2365207806 Color11St "Used to indicate status of Color 11 in the multi-color indicator lamp.
0000b = No Fault
0001b = Color On Fault (Commanded off)
0010b = Color Off fault (Commanded on)
0011b = Low Brightness
0100b = High Brightness
0101b = LED chipset failure
 ...";
CM_ SG_ 2365207806 Color10St "Used to indicate status of Color 10 in the multi-color indicator lamp.
0000b = No Fault
0001b = Color On Fault (Commanded off)
0010b = Color Off fault (Commanded on)
0011b = Low Brightness
0100b = High Brightness
0101b = LED chipset failure
 ...";
CM_ SG_ 2365207806 Color9St "Used to indicate status of Color 9 in the multi-color indicator lamp.
0000b = No Fault
0001b = Color On Fault (Commanded off)
0010b = Color Off fault (Commanded on)
0011b = Low Brightness
0100b = High Brightness
0101b = LED chipset failure
 ...";
CM_ SG_ 2365207806 Color8St "Used to indicate status of Color 8 in the multi-color indicator lamp.
0000b = No Fault
0001b = Color On Fault (Commanded off)
0010b = Color Off fault (Commanded on)
0011b = Low Brightness
0100b = High Brightness
0101b = LED chipset failure
 ...";
CM_ SG_ 2365207806 Color7St "Used to indicate status of Color 7 in the multi-color indicator lamp.
0000b = No Fault
0001b = Color On Fault (Commanded off)
0010b = Color Off fault (Commanded on)
0011b = Low Brightness
0100b = High Brightness
0101b = LED chipset failure
 ...";
CM_ SG_ 2365207806 Color6St "Used to indicate status of Color 6 in the multi-color indicator lamp.
0000b = No Fault
0001b = Color On Fault (Commanded off)
0010b = Color Off fault (Commanded on)
0011b = Low Brightness
0100b = High Brightness
0101b = LED chipset failure
 ...";
CM_ SG_ 2365207806 Color5St "Used to indicate status of Color 5 in the multi-color indicator lamp.
0000b = No Fault
0001b = Color On Fault (Commanded off)
0010b = Color Off fault (Commanded on)
0011b = Low Brightness
0100b = High Brightness
0101b = LED chipset failure
 ...";
CM_ SG_ 2365207806 Color4St "Used to indicate status of Color 4 in the multi-color indicator lamp.
0000b = No Fault
0001b = Color On Fault (Commanded off)
0010b = Color Off fault (Commanded on)
0011b = Low Brightness
0100b = High Brightness
0101b = LED chipset failure
 ...";
CM_ SG_ 2365207806 Color3St "Used to indicate status of Color 3 in the multi-color indicator lamp.
0000b = No Fault
0001b = Color On Fault (Commanded off)
0010b = Color Off fault (Commanded on)
0011b = Low Brightness
0100b = High Brightness
0101b = LED chipset failure
 ...";
CM_ SG_ 2365207806 Color2St "Used to indicate status of Color 2 in the multi-color indicator lamp.
0000b = No Fault
0001b = Color On Fault (Commanded off)
0010b = Color Off fault (Commanded on)
0011b = Low Brightness
0100b = High Brightness
0101b = LED chipset failure
 ...";
CM_ SG_ 2365207806 Color1St "Used to indicate status of Color 1 in the multi-color indicator lamp.
0000b = No Fault
0001b = Color On Fault (Commanded off)
0010b = Color Off fault (Commanded on)
0011b = Low Brightness
0100b = High Brightness
0101b = LED chipset failure
 ...";
CM_ SG_ 2365207806 FeedbackSequenceCounter "A feedback counter value which increments per each transmission of data of the multi-color indicator lamp.
Note: The counter for the first message is arbitary. In each following message or group of messages (if multiple instances) the value is ...";
CM_ BO_ 2365207550 "Multi-Color Indicator Lamp Command
Used to control the state of multi-Color indicator lamp.  The state values indicate how the Lamp shall turn ON and OFF a particular color.
See PGN 64052 (Multi-Color Indicator Lamp Status) for the message to ...";
CM_ SG_ 2365207550 Freq "Command from the source for the multi-color indicator lamp to target operations for 0.5 Hz, 1 Hz, or 2 Hz.
0000b = 0.5 Hz
0001b = 1 Hz
0010b = 2 Hz
0011b = Reserved
0100b = Reserved
0101b = Reserved
0110b = Reserved
0111b = Reserved
1000b = ...";
CM_ SG_ 2365207550 Synch "Command for an indicator lamp to synchronize with other indicator lamps on the network and flash the same pattern.

00b = Not Requested
01b = Requested
10b = Reserved
11b = Not Available";
CM_ SG_ 2365207550 Brightness "Commanded brightness level for the multi-color indicator lamp.
0% means low brightness level and 100% means full brightness level.";
CM_ SG_ 2365207550 TimeSlot10 "Tenth time slot for the multi-color indicator lamp.
Command to turn selected color on or off in multi-color indicator lamp for (period/frequency) ms.
0000b = Off
0001b = Color 1
0010b = Color 2
0011b = Color 3
0100b = Color 4
0101b = Color 5
 ...";
CM_ SG_ 2365207550 TimeSlot9 "Ninth time slot for the multi-color indicator lamp.
Command to turn selected color on or off in multi-color indicator lamp for (period/frequency) ms.
0000b = Off
0001b = Color 1
0010b = Color 2
0011b = Color 3
0100b = Color 4
0101b = Color 5
 ...";
CM_ SG_ 2365207550 TimeSlot8 "Eighth time slot for the multi-color indicator lamp.
Command to turn selected color on or off in multi-color indicator lamp for (period/frequency) ms.
0000b = Off
0001b = Color 1
0010b = Color 2
0011b = Color 3
0100b = Color 4
0101b = Color 5
 ...";
CM_ SG_ 2365207550 TimeSlot7 "Seventh time slot for the multi-color indicator lamp.
Command to turn selected color on or off in multi-color indicator lamp for (period/frequency) ms.
0000b = Off
0001b = Color 1
0010b = Color 2
0011b = Color 3
0100b = Color 4
0101b = Color ...";
CM_ SG_ 2365207550 TimeSlot6 "Sixth time slot for the multi-color indicator lamp.
Command to turn selected color on or off in multi-color indicator lamp for (period/frequency) ms.
0000b = Off
0001b = Color 1
0010b = Color 2
0011b = Color 3
0100b = Color 4
0101b = Color 5
 ...";
CM_ SG_ 2365207550 TimeSlot5 "Fifth time slot for the multi-color indicator lamp.
Command to turn selected color on or off in multi-color indicator lamp for (period/frequency) ms.
0000b = Off
0001b = Color 1
0010b = Color 2
0011b = Color 3
0100b = Color 4
0101b = Color 5
 ...";
CM_ SG_ 2365207550 TimeSlot4 "Fourth time slot for the multi-color indicator lamp.
Command to turn selected color on or off in multi-color indicator lamp for (period/frequency) ms.
0000b = Off
0001b = Color 1
0010b = Color 2
0011b = Color 3
0100b = Color 4
0101b = Color 5
 ...";
CM_ SG_ 2365207550 TimeSlot3 "Third time slot for the multi-color indicator lamp.
Command to turn selected color on or off in multi-color indicator lamp for (period/frequency) ms.
0000b = Off
0001b = Color 1
0010b = Color 2
0011b = Color 3
0100b = Color 4
0101b = Color 5
 ...";
CM_ SG_ 2365207550 TimeSlot2 "Second time slot for the multi-color indicator lamp.
Command to turn selected color on or off in multi-color indicator lamp for (period/frequency) ms.
0000b = Off
0001b = Color 1
0010b = Color 2
0011b = Color 3
0100b = Color 4
0101b = Color 5
 ...";
CM_ SG_ 2365207550 TimeSlot1 "First time slot for the multi-color indicator lamp.
Command to turn selected color on or off in multi-color indicator lamp for (period/frequency) ms.
0000b = Off
0001b = Color 1
0010b = Color 2
0011b = Color 3
0100b = Color 4
0101b = Color 5
 ...";
CM_ SG_ 2365207550 SequenceCounter "A counter value which increments per each transmission of data.
Note: The counter for the first message is arbitrary.  In each following message or group of messages (if multiple instances) the value is incremented by 1 (0 follows 13).";
CM_ BO_ 2365207294 "High Voltage Energy Storage Pack 12 Internal Status 1
Internal status data set 1 for High Voltage Energy Storage Pack 12.
The purpose of this PG is to assist in High Voltage Energy Storage Packs that require additional measurement and contactor ...";
CM_ SG_ 2365207294 HVInternalContactor8St22621 "Position of the High Voltage Energy Storage Pack 12 Internal 8 positive side bus contactor.
Refer to PGN description for usage of this SPN

00b = Contactor Open
01b = Contactor Closed
10b = Error
11b = Not Available";
CM_ SG_ 2365207294 HVInternalContactor7St22620 "Position of the High Voltage Energy Storage Pack 12 Internal 7 positive side bus contactor.
Refer to PGN description for usage of this SPN

00b = Contactor Open
01b = Contactor Closed
10b = Error
11b = Not Available";
CM_ SG_ 2365207294 HVInternalContactor6St22619 "Position of the High Voltage Energy Storage Pack 12 Internal 6 positive side bus contactor.
Refer to PGN description for usage of this SPN

00b = Contactor Open
01b = Contactor Closed
10b = Error
11b = Not Available";
CM_ SG_ 2365207294 HVInternalContactor5St22618 "Position of the High Voltage Energy Storage Pack 12 Internal 5 positive side bus contactor.
Refer to PGN description for usage of this SPN

00b = Contactor Open
01b = Contactor Closed
10b = Error
11b = Not Available";
CM_ SG_ 2365207294 HVInternalContactor4St22617 "Position of the High Voltage Energy Storage Pack 12 Internal 4 positive side bus contactor.
Refer to PGN description for usage of this SPN

00b = Contactor Open
01b = Contactor Closed
10b = Error
11b = Not Available";
CM_ SG_ 2365207294 HVInternalContactor3St22616 "Position of the High Voltage Energy Storage Pack 12 Internal 3 positive side bus contactor.
Refer to PGN description for usage of this SPN

00b = Contactor Open
01b = Contactor Closed
10b = Error
11b = Not Available";
CM_ SG_ 2365207294 HVInternalContactor2St22615 "Position of the High Voltage Energy Storage Pack 12 Internal 2 positive side bus contactor.
Refer to PGN description for usage of this SPN

00b = Contactor Open
01b = Contactor Closed
10b = Error
11b = Not Available";
CM_ SG_ 2365207294 HVInternalContactor1St22614 "Position of the High Voltage Energy Storage Pack 12 Internal 1 positive side bus contactor.
Refer to PGN description for usage of this SPN

00b = Contactor Open
01b = Contactor Closed
10b = Error
11b = Not Available";
CM_ SG_ 2365207294 HVInternalContactor8St "Position of the High Voltage Energy Storage  Pack 12 Internal 8 negative side bus contactor. 
Refer to PGN description for usage of this SPN

00b = Contactor Open
01b = Contactor Closed
10b = Error
11b = Not Available";
CM_ SG_ 2365207294 HVInternalContactor7St "Position of the High Voltage Energy Storage  Pack 12 Internal 7 negative side bus contactor. 
Refer to PGN description for usage of this SPN

00b = Contactor Open
01b = Contactor Closed
10b = Error
11b = Not Available";
CM_ SG_ 2365207294 HVInternalContactor6St "Position of the High Voltage Energy Storage  Pack 12 Internal 6 negative side bus contactor. 
Refer to PGN description for usage of this SPN

00b = Contactor Open
01b = Contactor Closed
10b = Error
11b = Not Available";
CM_ SG_ 2365207294 HVInternalContactor5St "Position of the High Voltage Energy Storage  Pack 12 Internal 5 negative side bus contactor. 
Refer to PGN description for usage of this SPN

00b = Contactor Open
01b = Contactor Closed
10b = Error
11b = Not Available";
CM_ SG_ 2365207294 HVInternalContactor4St "Position of the High Voltage Energy Storage  Pack 12 Internal 4 negative side bus contactor. 
Refer to PGN description for usage of this SPN

00b = Contactor Open
01b = Contactor Closed
10b = Error
11b = Not Available";
CM_ SG_ 2365207294 HVInternalContactor3St "Position of the High Voltage Energy Storage  Pack 12 Internal 3 negative side bus contactor. 
Refer to PGN description for usage of this SPN

00b = Contactor Open
01b = Contactor Closed
10b = Error
11b = Not Available";
CM_ SG_ 2365207294 HVInternalContactor2St "Position of the High Voltage Energy Storage  Pack 12 Internal 2 negative side bus contactor. 
Refer to PGN description for usage of this SPN

00b = Contactor Open
01b = Contactor Closed
10b = Error
11b = Not Available";
CM_ SG_ 2365207294 HVInternalContactor1St "Position of the High Voltage Energy Storage  Pack 12 Internal 1 negative side bus contactor. 
Refer to PGN description for usage of this SPN

00b = Contactor Open
01b = Contactor Closed
10b = Error
11b = Not Available";
CM_ BO_ 2365207038 "High Voltage Energy Storage Pack 11 Internal Status 1
Internal status data set 1 for High Voltage Energy Storage Pack 11.
The purpose of this PG is to assist in High Voltage Energy Storage Packs that require additional measurement and contactor ...";
CM_ SG_ 2365207038 HVInternalContactor8St22599 "Position of the High Voltage Energy Storage Pack 11 Internal 8 positive side bus contactor.
Refer to PGN description for usage of this SPN

00b = Contactor Open
01b = Contactor Closed
10b = Error
11b = Not Available";
CM_ SG_ 2365207038 HVInternalContactor7St22598 "Position of the High Voltage Energy Storage Pack 11 Internal 7 positive side bus contactor.
Refer to PGN description for usage of this SPN

00b = Contactor Open
01b = Contactor Closed
10b = Error
11b = Not Available";
CM_ SG_ 2365207038 HVInternalContactor6St22597 "Position of the High Voltage Energy Storage Pack 11 Internal 6 positive side bus contactor.
Refer to PGN description for usage of this SPN

00b = Contactor Open
01b = Contactor Closed
10b = Error
11b = Not Available";
CM_ SG_ 2365207038 HVInternalContactor5St22596 "Position of the High Voltage Energy Storage Pack 11 Internal 5 positive side bus contactor.
Refer to PGN description for usage of this SPN

00b = Contactor Open
01b = Contactor Closed
10b = Error
11b = Not Available";
CM_ SG_ 2365207038 HVInternalContactor4St22595 "Position of the High Voltage Energy Storage Pack 11 Internal 4 positive side bus contactor.
Refer to PGN description for usage of this SPN

00b = Contactor Open
01b = Contactor Closed
10b = Error
11b = Not Available";
CM_ SG_ 2365207038 HVInternalContactor3St22594 "Position of the High Voltage Energy Storage Pack 11 Internal 3 positive side bus contactor.
Refer to PGN description for usage of this SPN

00b = Contactor Open
01b = Contactor Closed
10b = Error
11b = Not Available";
CM_ SG_ 2365207038 HVInternalContactor2St22593 "Position of the High Voltage Energy Storage Pack 11 Internal 2 positive side bus contactor.
Refer to PGN description for usage of this SPN

00b = Contactor Open
01b = Contactor Closed
10b = Error
11b = Not Available";
CM_ SG_ 2365207038 HVInternalContactor1St22592 "Position of the High Voltage Energy Storage Pack 11 Internal 1 positive side bus contactor.
Refer to PGN description for usage of this SPN

00b = Contactor Open
01b = Contactor Closed
10b = Error
11b = Not Available";
CM_ SG_ 2365207038 HVInternalContactor8St "Position of the High Voltage Energy Storage  Pack 11 Internal 8 negative side bus contactor. 
Refer to PGN description for usage of this SPN

00b = Contactor Open
01b = Contactor Closed
10b = Error
11b = Not Available";
CM_ SG_ 2365207038 HVInternalContactor7St "Position of the High Voltage Energy Storage  Pack 11 Internal 7 negative side bus contactor. 
Refer to PGN description for usage of this SPN

00b = Contactor Open
01b = Contactor Closed
10b = Error
11b = Not Available";
CM_ SG_ 2365207038 HVInternalContactor6St "Position of the High Voltage Energy Storage  Pack 11 Internal 6 negative side bus contactor. 
Refer to PGN description for usage of this SPN

00b = Contactor Open
01b = Contactor Closed
10b = Error
11b = Not Available";
CM_ SG_ 2365207038 HVInternalContactor5St "Position of the High Voltage Energy Storage  Pack 11 Internal 5 negative side bus contactor. 
Refer to PGN description for usage of this SPN

00b = Contactor Open
01b = Contactor Closed
10b = Error
11b = Not Available";
CM_ SG_ 2365207038 HVInternalContactor4St "Position of the High Voltage Energy Storage  Pack 11 Internal 4 negative side bus contactor. 
Refer to PGN description for usage of this SPN

00b = Contactor Open
01b = Contactor Closed
10b = Error
11b = Not Available";
CM_ SG_ 2365207038 HVInternalContactor3St "Position of the High Voltage Energy Storage  Pack 11 Internal 3 negative side bus contactor. 
Refer to PGN description for usage of this SPN

00b = Contactor Open
01b = Contactor Closed
10b = Error
11b = Not Available";
CM_ SG_ 2365207038 HVInternalContactor2St "Position of the High Voltage Energy Storage  Pack 11 Internal 2 negative side bus contactor. 
Refer to PGN description for usage of this SPN

00b = Contactor Open
01b = Contactor Closed
10b = Error
11b = Not Available";
CM_ SG_ 2365207038 HVInternalContactor1St "Position of the High Voltage Energy Storage  Pack 11 Internal 1 negative side bus contactor. 
Refer to PGN description for usage of this SPN

00b = Contactor Open
01b = Contactor Closed
10b = Error
11b = Not Available";
CM_ BO_ 2365206782 "High Voltage Energy Storage Pack 10 Internal Status 1
Internal status data set 1 for High Voltage Energy Storage Pack 10.
The purpose of this PG is to assist in High Voltage Energy Storage Packs that require additional measurement and contactor ...";
CM_ SG_ 2365206782 HVInternalContactor8St22577 "Position of the High Voltage Energy Storage Pack 10 Internal 8 positive side bus contactor.
Refer to PGN description for usage of this SPN

00b = Contactor Open
01b = Contactor Closed
10b = Error
11b = Not Available";
CM_ SG_ 2365206782 HVInternalContactor7St22576 "Position of the High Voltage Energy Storage Pack 10 Internal 7 positive side bus contactor.
Refer to PGN description for usage of this SPN

00b = Contactor Open
01b = Contactor Closed
10b = Error
11b = Not Available";
CM_ SG_ 2365206782 HVInternalContactor6St22575 "Position of the High Voltage Energy Storage Pack 10 Internal 6 positive side bus contactor.
Refer to PGN description for usage of this SPN

00b = Contactor Open
01b = Contactor Closed
10b = Error
11b = Not Available";
CM_ SG_ 2365206782 HVInternalContactor5St22574 "Position of the High Voltage Energy Storage Pack 10 Internal 5 positive side bus contactor.
Refer to PGN description for usage of this SPN

00b = Contactor Open
01b = Contactor Closed
10b = Error
11b = Not Available";
CM_ SG_ 2365206782 HVInternalContactor4St22573 "Position of the High Voltage Energy Storage Pack 10 Internal 4 positive side bus contactor.
Refer to PGN description for usage of this SPN

00b = Contactor Open
01b = Contactor Closed
10b = Error
11b = Not Available";
CM_ SG_ 2365206782 HVInternalContactor3St22572 "Position of the High Voltage Energy Storage Pack 10 Internal 3 positive side bus contactor.
Refer to PGN description for usage of this SPN

00b = Contactor Open
01b = Contactor Closed
10b = Error
11b = Not Available";
CM_ SG_ 2365206782 HVInternalContactor2St22571 "Position of the High Voltage Energy Storage Pack 10 Internal 2 positive side bus contactor.
Refer to PGN description for usage of this SPN

00b = Contactor Open
01b = Contactor Closed
10b = Error
11b = Not Available";
CM_ SG_ 2365206782 HVInternalContactor1St22570 "Position of the High Voltage Energy Storage Pack 10 Internal 1 positive side bus contactor.
Refer to PGN description for usage of this SPN

00b = Contactor Open
01b = Contactor Closed
10b = Error
11b = Not Available";
CM_ SG_ 2365206782 HVInternalContactor8St "Position of the High Voltage Energy Storage  Pack 10 Internal 8 negative side bus contactor. 
Refer to PGN description for usage of this SPN

00b = Contactor Open
01b = Contactor Closed
10b = Error
11b = Not Available";
CM_ SG_ 2365206782 HVInternalContactor7St "Position of the High Voltage Energy Storage  Pack 10 Internal 7 negative side bus contactor. 
Refer to PGN description for usage of this SPN

00b = Contactor Open
01b = Contactor Closed
10b = Error
11b = Not Available";
CM_ SG_ 2365206782 HVInternalContactor6St "Position of the High Voltage Energy Storage  Pack 10 Internal 6 negative side bus contactor. 
Refer to PGN description for usage of this SPN

00b = Contactor Open
01b = Contactor Closed
10b = Error
11b = Not Available";
CM_ SG_ 2365206782 HVInternalContactor5St "Position of the High Voltage Energy Storage  Pack 10 Internal 5 negative side bus contactor. 
Refer to PGN description for usage of this SPN

00b = Contactor Open
01b = Contactor Closed
10b = Error
11b = Not Available";
CM_ SG_ 2365206782 HVInternalContactor4St "Position of the High Voltage Energy Storage  Pack 10 Internal 4 negative side bus contactor. 
Refer to PGN description for usage of this SPN

00b = Contactor Open
01b = Contactor Closed
10b = Error
11b = Not Available";
CM_ SG_ 2365206782 HVInternalContactor3St "Position of the High Voltage Energy Storage  Pack 10 Internal 3 negative side bus contactor. 
Refer to PGN description for usage of this SPN

00b = Contactor Open
01b = Contactor Closed
10b = Error
11b = Not Available";
CM_ SG_ 2365206782 HVInternalContactor2St "Position of the High Voltage Energy Storage  Pack 10 Internal 2 negative side bus contactor. 
Refer to PGN description for usage of this SPN

00b = Contactor Open
01b = Contactor Closed
10b = Error
11b = Not Available";
CM_ SG_ 2365206782 HVInternalContactor1St "Position of the High Voltage Energy Storage  Pack 10 Internal 1 negative side bus contactor. 
Refer to PGN description for usage of this SPN

00b = Contactor Open
01b = Contactor Closed
10b = Error
11b = Not Available";
CM_ BO_ 2365206526 "High Voltage Energy Storage Pack 9 Internal Status 1
Internal status data set 1 for High Voltage Energy Storage Pack 9.
The purpose of this PG is to assist in High Voltage Energy Storage Packs that require additional measurement and contactor ...";
CM_ SG_ 2365206526 HVInternalContactor8St22555 "Position of the High Voltage Energy Storage Pack 9 Internal 8 positive side bus contactor.
Refer to PGN description for usage of this SPN

00b = Contactor Open
01b = Contactor Closed
10b = Error
11b = Not Available";
CM_ SG_ 2365206526 HVInternalContactor7St22554 "Position of the High Voltage Energy Storage Pack 9 Internal 7 positive side bus contactor.
Refer to PGN description for usage of this SPN

00b = Contactor Open
01b = Contactor Closed
10b = Error
11b = Not Available";
CM_ SG_ 2365206526 HVInternalContactor6St22553 "Position of the High Voltage Energy Storage Pack 9 Internal 6 positive side bus contactor.
Refer to PGN description for usage of this SPN

00b = Contactor Open
01b = Contactor Closed
10b = Error
11b = Not Available";
CM_ SG_ 2365206526 HVInternalContactor5St22552 "Position of the High Voltage Energy Storage Pack 9 Internal 5 positive side bus contactor.
Refer to PGN description for usage of this SPN

00b = Contactor Open
01b = Contactor Closed
10b = Error
11b = Not Available";
CM_ SG_ 2365206526 HVInternalContactor4St22551 "Position of the High Voltage Energy Storage Pack 9 Internal 4 positive side bus contactor.
Refer to PGN description for usage of this SPN

00b = Contactor Open
01b = Contactor Closed
10b = Error
11b = Not Available";
CM_ SG_ 2365206526 HVInternalContactor3St22550 "Position of the High Voltage Energy Storage Pack 9 Internal 3 positive side bus contactor.
Refer to PGN description for usage of this SPN

00b = Contactor Open
01b = Contactor Closed
10b = Error
11b = Not Available";
CM_ SG_ 2365206526 HVInternalContactor2St22549 "Position of the High Voltage Energy Storage Pack 9 Internal 2 positive side bus contactor.
Refer to PGN description for usage of this SPN

00b = Contactor Open
01b = Contactor Closed
10b = Error
11b = Not Available";
CM_ SG_ 2365206526 HVInternalContactor1St22548 "Position of the High Voltage Energy Storage Pack 9 Internal 1 positive side bus contactor.
Refer to PGN description for usage of this SPN

00b = Contactor Open
01b = Contactor Closed
10b = Error
11b = Not Available";
CM_ SG_ 2365206526 HVInternalContactor8St "Position of the High Voltage Energy Storage  Pack 9 Internal 8 negative side bus contactor. 
Refer to PGN description for usage of this SPN

00b = Contactor Open
01b = Contactor Closed
10b = Error
11b = Not Available";
CM_ SG_ 2365206526 HVInternalContactor7St "Position of the High Voltage Energy Storage  Pack 9 Internal 7 negative side bus contactor. 
Refer to PGN description for usage of this SPN

00b = Contactor Open
01b = Contactor Closed
10b = Error
11b = Not Available";
CM_ SG_ 2365206526 HVInternalContactor6St "Position of the High Voltage Energy Storage  Pack 9 Internal 6 negative side bus contactor. 
Refer to PGN description for usage of this SPN

00b = Contactor Open
01b = Contactor Closed
10b = Error
11b = Not Available";
CM_ SG_ 2365206526 HVInternalContactor5St "Position of the High Voltage Energy Storage  Pack 9 Internal 5 negative side bus contactor. 
Refer to PGN description for usage of this SPN

00b = Contactor Open
01b = Contactor Closed
10b = Error
11b = Not Available";
CM_ SG_ 2365206526 HVInternalContactor4St "Position of the High Voltage Energy Storage  Pack 9 Internal 4 negative side bus contactor. 
Refer to PGN description for usage of this SPN

00b = Contactor Open
01b = Contactor Closed
10b = Error
11b = Not Available";
CM_ SG_ 2365206526 HVInternalContactor3St "Position of the High Voltage Energy Storage  Pack 9 Internal 3 negative side bus contactor. 
Refer to PGN description for usage of this SPN

00b = Contactor Open
01b = Contactor Closed
10b = Error
11b = Not Available";
CM_ SG_ 2365206526 HVInternalContactor2St "Position of the High Voltage Energy Storage  Pack 9 Internal 2 negative side bus contactor. 
Refer to PGN description for usage of this SPN

00b = Contactor Open
01b = Contactor Closed
10b = Error
11b = Not Available";
CM_ SG_ 2365206526 HVInternalContactor1St "Position of the High Voltage Energy Storage  Pack 9 Internal 1 negative side bus contactor. 
Refer to PGN description for usage of this SPN

00b = Contactor Open
01b = Contactor Closed
10b = Error
11b = Not Available";
CM_ BO_ 2365206270 "High Voltage Energy Storage Pack 8 Internal Status 1
Internal status data set 1 for High Voltage Energy Storage Pack 8.
The purpose of this PG is to assist in High Voltage Energy Storage Packs that require additional measurement and contactor ...";
CM_ SG_ 2365206270 HVInternalContactor8St22533 "Position of the High Voltage Energy Storage Pack 8 Internal 8 positive side bus contactor.
Refer to PGN description for usage of this SPN

00b = Contactor Open
01b = Contactor Closed
10b = Error
11b = Not Available";
CM_ SG_ 2365206270 HVInternalContactor7St22532 "Position of the High Voltage Energy Storage Pack 8 Internal 7 positive side bus contactor.
Refer to PGN description for usage of this SPN

00b = Contactor Open
01b = Contactor Closed
10b = Error
11b = Not Available";
CM_ SG_ 2365206270 HVInternalContactor6St22531 "Position of the High Voltage Energy Storage Pack 8 Internal 6 positive side bus contactor.
Refer to PGN description for usage of this SPN

00b = Contactor Open
01b = Contactor Closed
10b = Error
11b = Not Available";
CM_ SG_ 2365206270 HVInternalContactor5St22530 "Position of the High Voltage Energy Storage Pack 8 Internal 5 positive side bus contactor.
Refer to PGN description for usage of this SPN

00b = Contactor Open
01b = Contactor Closed
10b = Error
11b = Not Available";
CM_ SG_ 2365206270 HVInternalContactor4St22529 "Position of the High Voltage Energy Storage Pack 8 Internal 4 positive side bus contactor.
Refer to PGN description for usage of this SPN

00b = Contactor Open
01b = Contactor Closed
10b = Error
11b = Not Available";
CM_ SG_ 2365206270 HVInternalContactor3St22528 "Position of the High Voltage Energy Storage Pack 8 Internal 3 positive side bus contactor.
Refer to PGN description for usage of this SPN

00b = Contactor Open
01b = Contactor Closed
10b = Error
11b = Not Available";
CM_ SG_ 2365206270 HVInternalContactor2St22527 "Position of the High Voltage Energy Storage Pack 8 Internal 2 positive side bus contactor.
Refer to PGN description for usage of this SPN

00b = Contactor Open
01b = Contactor Closed
10b = Error
11b = Not Available";
CM_ SG_ 2365206270 HVInternalContactor1St22526 "Position of the High Voltage Energy Storage Pack 8 Internal 1 positive side bus contactor.
Refer to PGN description for usage of this SPN

00b = Contactor Open
01b = Contactor Closed
10b = Error
11b = Not Available";
CM_ SG_ 2365206270 HVInternalContactor8St "Position of the High Voltage Energy Storage  Pack 8 Internal 8 negative side bus contactor. 
Refer to PGN description for usage of this SPN

00b = Contactor Open
01b = Contactor Closed
10b = Error
11b = Not Available";
CM_ SG_ 2365206270 HVInternalContactor7St "Position of the High Voltage Energy Storage  Pack 8 Internal 7 negative side bus contactor. 
Refer to PGN description for usage of this SPN

00b = Contactor Open
01b = Contactor Closed
10b = Error
11b = Not Available";
CM_ SG_ 2365206270 HVInternalContactor6St "Position of the High Voltage Energy Storage  Pack 8 Internal 6 negative side bus contactor. 
Refer to PGN description for usage of this SPN

00b = Contactor Open
01b = Contactor Closed
10b = Error
11b = Not Available";
CM_ SG_ 2365206270 HVInternalContactor5St "Position of the High Voltage Energy Storage  Pack 8 Internal 5 negative side bus contactor. 
Refer to PGN description for usage of this SPN

00b = Contactor Open
01b = Contactor Closed
10b = Error
11b = Not Available";
CM_ SG_ 2365206270 HVInternalContactor4St "Position of the High Voltage Energy Storage  Pack 8 Internal 4 negative side bus contactor. 
Refer to PGN description for usage of this SPN

00b = Contactor Open
01b = Contactor Closed
10b = Error
11b = Not Available";
CM_ SG_ 2365206270 HVInternalContactor3St "Position of the High Voltage Energy Storage  Pack 8 Internal 3 negative side bus contactor. 
Refer to PGN description for usage of this SPN

00b = Contactor Open
01b = Contactor Closed
10b = Error
11b = Not Available";
CM_ SG_ 2365206270 HVInternalContactor2St "Position of the High Voltage Energy Storage  Pack 8 Internal 2 negative side bus contactor. 
Refer to PGN description for usage of this SPN

00b = Contactor Open
01b = Contactor Closed
10b = Error
11b = Not Available";
CM_ SG_ 2365206270 HVInternalContactor1St "Position of the High Voltage Energy Storage  Pack 8 Internal 1 negative side bus contactor. 
Refer to PGN description for usage of this SPN

00b = Contactor Open
01b = Contactor Closed
10b = Error
11b = Not Available";
CM_ BO_ 2365206014 "High Voltage Energy Storage Pack 7 Internal Status 1
Internal status data set 1 for High Voltage Energy Storage Pack 7.
The purpose of this PG is to assist in High Voltage Energy Storage Packs that require additional measurement and contactor ...";
CM_ SG_ 2365206014 HVInternalContactor8St22511 "Position of the High Voltage Energy Storage Pack 7 Internal 8 positive side bus contactor.
Refer to PGN description for usage of this SPN

00b = Contactor Open
01b = Contactor Closed
10b = Error
11b = Not Available";
CM_ SG_ 2365206014 HVInternalContactor7St22510 "Position of the High Voltage Energy Storage Pack 7 Internal 7 positive side bus contactor.
Refer to PGN description for usage of this SPN

00b = Contactor Open
01b = Contactor Closed
10b = Error
11b = Not Available";
CM_ SG_ 2365206014 HVInternalContactor6St22509 "Position of the High Voltage Energy Storage Pack 7 Internal 6 positive side bus contactor.
Refer to PGN description for usage of this SPN

00b = Contactor Open
01b = Contactor Closed
10b = Error
11b = Not Available";
CM_ SG_ 2365206014 HVInternalContactor5St22508 "Position of the High Voltage Energy Storage Pack 7 Internal 5 positive side bus contactor.
Refer to PGN description for usage of this SPN

00b = Contactor Open
01b = Contactor Closed
10b = Error
11b = Not Available";
CM_ SG_ 2365206014 HVInternalContactor4St22507 "Position of the High Voltage Energy Storage Pack 7 Internal 4 positive side bus contactor.
Refer to PGN description for usage of this SPN

00b = Contactor Open
01b = Contactor Closed
10b = Error
11b = Not Available";
CM_ SG_ 2365206014 HVInternalContactor3St22506 "Position of the High Voltage Energy Storage Pack 7 Internal 3 positive side bus contactor.
Refer to PGN description for usage of this SPN

00b = Contactor Open
01b = Contactor Closed
10b = Error
11b = Not Available";
CM_ SG_ 2365206014 HVInternalContactor2St22505 "Position of the High Voltage Energy Storage Pack 7 Internal 2 positive side bus contactor.
Refer to PGN description for usage of this SPN

00b = Contactor Open
01b = Contactor Closed
10b = Error
11b = Not Available";
CM_ SG_ 2365206014 HVInternalContactor1St22504 "Position of the High Voltage Energy Storage Pack 7 Internal 1 positive side bus contactor.
Refer to PGN description for usage of this SPN

00b = Contactor Open
01b = Contactor Closed
10b = Error
11b = Not Available";
CM_ SG_ 2365206014 HVInternalContactor8St "Position of the High Voltage Energy Storage  Pack 7 Internal 8 negative side bus contactor. 
Refer to PGN description for usage of this SPN

00b = Contactor Open
01b = Contactor Closed
10b = Error
11b = Not Available";
CM_ SG_ 2365206014 HVInternalContactor7St "Position of the High Voltage Energy Storage  Pack 7 Internal 7 negative side bus contactor. 
Refer to PGN description for usage of this SPN

00b = Contactor Open
01b = Contactor Closed
10b = Error
11b = Not Available";
CM_ SG_ 2365206014 HVInternalContactor6St "Position of the High Voltage Energy Storage  Pack 7 Internal 6 negative side bus contactor. 
Refer to PGN description for usage of this SPN

00b = Contactor Open
01b = Contactor Closed
10b = Error
11b = Not Available";
CM_ SG_ 2365206014 HVInternalContactor5St "Position of the High Voltage Energy Storage  Pack 7 Internal 5 negative side bus contactor. 
Refer to PGN description for usage of this SPN

00b = Contactor Open
01b = Contactor Closed
10b = Error
11b = Not Available";
CM_ SG_ 2365206014 HVInternalContactor4St "Position of the High Voltage Energy Storage  Pack 7 Internal 4 negative side bus contactor. 
Refer to PGN description for usage of this SPN

00b = Contactor Open
01b = Contactor Closed
10b = Error
11b = Not Available";
CM_ SG_ 2365206014 HVInternalContactor3St "Position of the High Voltage Energy Storage  Pack 7 Internal 3 negative side bus contactor. 
Refer to PGN description for usage of this SPN

00b = Contactor Open
01b = Contactor Closed
10b = Error
11b = Not Available";
CM_ SG_ 2365206014 HVInternalContactor2St "Position of the High Voltage Energy Storage  Pack 7 Internal 2 negative side bus contactor. 
Refer to PGN description for usage of this SPN

00b = Contactor Open
01b = Contactor Closed
10b = Error
11b = Not Available";
CM_ SG_ 2365206014 HVInternalContactor1St "Position of the High Voltage Energy Storage  Pack 7 Internal 1 negative side bus contactor. 
Refer to PGN description for usage of this SPN

00b = Contactor Open
01b = Contactor Closed
10b = Error
11b = Not Available";
BA_DEF_ SG_  "GenSigInactiveValue" INT 0 0;
BA_DEF_ SG_  "SigType" ENUM  "Default","Range","RangeSigned","ASCII","Discrete","Control","ReferencePGN","DTC","StringDelimiter","StringLength","StringLengthControl","MessageCounter","MessageChecksum";
BA_DEF_ SG_  "GenSigStartValue" INT 0 2147483647;
BA_DEF_ SG_  "GenSigSendType" ENUM  "Cyclic","OnWrite","OnWriteWithRepetition","OnChange","OnChangeWithRepetition","IfActive","IfActiveWithRepetition","NoSigSendType";
BA_DEF_ SG_  "GenSigILSupport" ENUM  "No","Yes";
BA_DEF_ SG_  "SPN" INT 0 524287;
BA_DEF_ BO_  "J1939CPgSendTimeout" INT -1 3600000;
BA_DEF_ BO_  "J1939CPgTOS" INT 0 7;
BA_DEF_ BO_  "J1939PgAppearanceOnBus" ENUM  "Default","CAN_Extended","CANFD_Extended";
BA_DEF_ BO_  "FsJ1939UseCrcAndCounter" STRING ;
BA_DEF_ BO_  "TpJ1939VarDlc" ENUM  "No","Yes";
BA_DEF_ BO_  "GenMsgNrOfRepetition" INT 0 1000000;
BA_DEF_ BO_  "GenMsgCycleTimeFast" INT 0 3600000;
BA_DEF_ BO_  "GenMsgFastOnStart" INT 0 100000;
BA_DEF_ BO_  "GenMsgStartDelayTime" INT 0 100000;
BA_DEF_ BO_  "GenMsgILSupport" ENUM  "No","Yes";
BA_DEF_ BO_  "GenMsgDelayTime" INT 0 1000;
BA_DEF_ BO_  "GenMsgRequestable" INT 0 1;
BA_DEF_ BO_  "GenMsgSendType" ENUM  "cyclic","NotUsed","NotUsed","NotUsed","NotUsed","NotUsed","NotUsed","IfActive","noMsgSendType";
BA_DEF_ BO_  "VFrameFormat" ENUM  "StandardCAN","ExtendedCAN","reserved","J1939PG","reserved","reserved","reserved","reserved","reserved","reserved","reserved","reserved","reserved","reserved","StandardCAN_FD","ExtendedCAN_FD";
BA_DEF_ BO_  "SingleFrame" INT 0 1;
BA_DEF_ BO_  "GenMsgCycleTime" INT 0 3600000;
BA_DEF_ BU_  "J1939MultiPgSendTimeout" INT 0 3600000;
BA_DEF_ BU_  "J1939MultiPgSizeThreshold" INT 0 64;
BA_DEF_ BU_  "J1939MultiPgBroadcastType" ENUM  "FBFF","FEFF";
BA_DEF_ BU_  "NmStationAddress" INT 0 255;
BA_DEF_ BU_  "NmJ1939IndustryGroup" INT 0 7;
BA_DEF_ BU_  "NmJ1939System" INT 0 127;
BA_DEF_ BU_  "NmJ1939Function" INT 0 255;
BA_DEF_ BU_  "NmJ1939FunctionInstance" INT 0 7;
BA_DEF_ BU_  "NmJ1939ECUInstance" INT 0 7;
BA_DEF_  "SAE_J1939_22_SpecVersion" STRING ;
BA_DEF_  "SAE_J1939_76_SpecVersion" STRING ;
BA_DEF_  "SAE_J1939_DA_SpecVersion" STRING ;
BA_DEF_  "SAE_J1939_81_SpecVersion" STRING ;
BA_DEF_  "DatabaseVersion" STRING ;
BA_DEF_  "BusType" STRING ;
BA_DEF_  "ProtocolType" STRING ;
BA_DEF_  "SAE_J1939_75_SpecVersion" STRING ;
BA_DEF_  "SAE_J1939_21_SpecVersion" STRING ;
BA_DEF_  "SAE_J1939_73_SpecVersion" STRING ;
BA_DEF_  "SAE_J1939_71_SpecVersion" STRING ;
BA_DEF_ SG_  "SystemSignalLongSymbol" STRING ;
BA_DEF_DEF_  "GenSigInactiveValue" 0;
BA_DEF_DEF_  "SigType" "Default";
BA_DEF_DEF_  "GenSigStartValue" 0;
BA_DEF_DEF_  "GenSigSendType" "NoSigSendType";
BA_DEF_DEF_  "GenSigILSupport" "Yes";
BA_DEF_DEF_  "SPN" 0;
BA_DEF_DEF_  "J1939CPgSendTimeout" -1;
BA_DEF_DEF_  "J1939CPgTOS" 2;
BA_DEF_DEF_  "J1939PgAppearanceOnBus" "Default";
BA_DEF_DEF_  "FsJ1939UseCrcAndCounter" "";
BA_DEF_DEF_  "TpJ1939VarDlc" "No";
BA_DEF_DEF_  "GenMsgNrOfRepetition" 0;
BA_DEF_DEF_  "GenMsgCycleTimeFast" 0;
BA_DEF_DEF_  "GenMsgFastOnStart" 0;
BA_DEF_DEF_  "GenMsgStartDelayTime" 0;
BA_DEF_DEF_  "GenMsgILSupport" "Yes";
BA_DEF_DEF_  "GenMsgDelayTime" 0;
BA_DEF_DEF_  "GenMsgRequestable" 1;
BA_DEF_DEF_  "GenMsgSendType" "noMsgSendType";
BA_DEF_DEF_  "VFrameFormat" "J1939PG";
BA_DEF_DEF_  "SingleFrame" 1;
BA_DEF_DEF_  "GenMsgCycleTime" 0;
BA_DEF_DEF_  "J1939MultiPgSendTimeout" 2;
BA_DEF_DEF_  "J1939MultiPgSizeThreshold" 56;
BA_DEF_DEF_  "J1939MultiPgBroadcastType" "FBFF";
BA_DEF_DEF_  "NmStationAddress" 254;
BA_DEF_DEF_  "NmJ1939IndustryGroup" 0;
BA_DEF_DEF_  "NmJ1939System" 0;
BA_DEF_DEF_  "NmJ1939Function" 0;
BA_DEF_DEF_  "NmJ1939FunctionInstance" 0;
BA_DEF_DEF_  "NmJ1939ECUInstance" 0;
BA_DEF_DEF_  "SAE_J1939_22_SpecVersion" "";
BA_DEF_DEF_  "SAE_J1939_76_SpecVersion" "";
BA_DEF_DEF_  "SAE_J1939_DA_SpecVersion" "";
BA_DEF_DEF_  "SAE_J1939_81_SpecVersion" "";
BA_DEF_DEF_  "DatabaseVersion" "";
BA_DEF_DEF_  "BusType" "";
BA_DEF_DEF_  "ProtocolType" "";
BA_DEF_DEF_  "SAE_J1939_75_SpecVersion" "";
BA_DEF_DEF_  "SAE_J1939_21_SpecVersion" "";
BA_DEF_DEF_  "SAE_J1939_73_SpecVersion" "";
BA_DEF_DEF_  "SAE_J1939_71_SpecVersion" "";
BA_DEF_DEF_  "SystemSignalLongSymbol" "";
BA_ "SAE_J1939_22_SpecVersion" "2021-03";
BA_ "SAE_J1939_76_SpecVersion" "2018-11";
BA_ "SAE_J1939_DA_SpecVersion" "2023-07";
BA_ "SAE_J1939_81_SpecVersion" "2017-03";
BA_ "DatabaseVersion" "17 SP3";
BA_ "BusType" "CAN";
BA_ "ProtocolType" "J1939";
BA_ "SAE_J1939_75_SpecVersion" "2015-11";
BA_ "SAE_J1939_21_SpecVersion" "2018-10";
BA_ "SAE_J1939_73_SpecVersion" "2019-01";
BA_ "SAE_J1939_71_SpecVersion" "2020-02";
BA_ "NmStationAddress" BU_ PowertrainControlModule 90;
BA_ "NmStationAddress" BU_ AtmosphericSensor 89;
BA_ "NmJ1939Function" BU_ AtmosphericSensor 76;
BA_ "NmStationAddress" BU_ SafetyRestraintSystem2 88;
BA_ "NmJ1939Function" BU_ SafetyRestraintSystem2 132;
BA_ "NmJ1939FunctionInstance" BU_ SafetyRestraintSystem2 1;
BA_ "NmStationAddress" BU_ Aftertreatment_2_GasOutlet 87;
BA_ "NmJ1939Function" BU_ Aftertreatment_2_GasOutlet 68;
BA_ "NmJ1939FunctionInstance" BU_ Aftertreatment_2_GasOutlet 1;
BA_ "NmJ1939ECUInstance" BU_ Aftertreatment_2_GasOutlet 1;
BA_ "NmStationAddress" BU_ Aftertreatment_2_GasIntake 86;
BA_ "NmJ1939Function" BU_ Aftertreatment_2_GasIntake 68;
BA_ "NmJ1939FunctionInstance" BU_ Aftertreatment_2_GasIntake 1;
BA_ "NmStationAddress" BU_ DieselParticulateFilterControl 85;
BA_ "NmJ1939Function" BU_ DieselParticulateFilterControl 69;
BA_ "NmStationAddress" BU_ Turbocharger 2;
BA_ "NmJ1939Function" BU_ Turbocharger 133;
BA_ "NmStationAddress" BU_ SafetyRestraintSystem1 83;
BA_ "NmJ1939Function" BU_ SafetyRestraintSystem1 132;
BA_ "NmStationAddress" BU_ CabDisplay2 84;
BA_ "NmJ1939Function" BU_ CabDisplay2 60;
BA_ "NmJ1939FunctionInstance" BU_ CabDisplay2 1;
BA_ "NmStationAddress" BU_ Aftertreatment_1_GasOutlet 82;
BA_ "NmJ1939Function" BU_ Aftertreatment_1_GasOutlet 68;
BA_ "NmJ1939ECUInstance" BU_ Aftertreatment_1_GasOutlet 1;
BA_ "NmStationAddress" BU_ Aftertreatment_1_GasIntake 81;
BA_ "NmJ1939Function" BU_ Aftertreatment_1_GasIntake 68;
BA_ "NmStationAddress" BU_ OnBoardDataLogger 251;
BA_ "NmJ1939Function" BU_ OnBoardDataLogger 130;
BA_ "NmStationAddress" BU_ OffBoardDiagnosticTool2 250;
BA_ "NmJ1939Function" BU_ OffBoardDiagnosticTool2 129;
BA_ "NmJ1939FunctionInstance" BU_ OffBoardDiagnosticTool2 1;
BA_ "NmStationAddress" BU_ OffBoardDiagnosticTool1 249;
BA_ "NmJ1939Function" BU_ OffBoardDiagnosticTool1 129;
BA_ "NmStationAddress" BU_ FileServer 248;
BA_ "NmJ1939Function" BU_ FileServer 61;
BA_ "NmStationAddress" BU_ ParkingBrakeController 80;
BA_ "NmJ1939Function" BU_ ParkingBrakeController 9;
BA_ "NmJ1939FunctionInstance" BU_ ParkingBrakeController 1;
BA_ "NmStationAddress" BU_ SeatController2 79;
BA_ "NmJ1939Function" BU_ SeatController2 40;
BA_ "NmJ1939FunctionInstance" BU_ SeatController2 1;
BA_ "NmStationAddress" BU_ FanDriveController 78;
BA_ "NmJ1939Function" BU_ FanDriveController 58;
BA_ "NmStationAddress" BU_ SteeringColumnUnit 77;
BA_ "NmJ1939Function" BU_ SteeringColumnUnit 57;
BA_ "NmStationAddress" BU_ CommunicationUnitRadio 76;
BA_ "NmJ1939Function" BU_ CommunicationUnitRadio 56;
BA_ "NmStationAddress" BU_ CommunicationUnitSatellite 75;
BA_ "NmJ1939Function" BU_ CommunicationUnitSatellite 55;
BA_ "NmStationAddress" BU_ CommunicationUnitCellular 74;
BA_ "NmJ1939Function" BU_ CommunicationUnitCellular 54;
BA_ "NmStationAddress" BU_ PropulsionBatteryCharger 73;
BA_ "NmJ1939Function" BU_ PropulsionBatteryCharger 31;
BA_ "NmStationAddress" BU_ ChassisController2 72;
BA_ "NmJ1939Function" BU_ ChassisController2 52;
BA_ "NmJ1939FunctionInstance" BU_ ChassisController2 1;
BA_ "NmStationAddress" BU_ ChassisController1 71;
BA_ "NmJ1939Function" BU_ ChassisController1 52;
BA_ "NmStationAddress" BU_ EngineValveControl 70;
BA_ "NmJ1939Function" BU_ EngineValveControl 63;
BA_ "NmStationAddress" BU_ AuxiliaryHeater2 69;
BA_ "NmJ1939Function" BU_ AuxiliaryHeater2 50;
BA_ "NmJ1939FunctionInstance" BU_ AuxiliaryHeater2 1;
BA_ "NmStationAddress" BU_ AuxiliaryHeater1 68;
BA_ "NmJ1939Function" BU_ AuxiliaryHeater1 50;
BA_ "NmStationAddress" BU_ ClutchUnit 67;
BA_ "NmJ1939Function" BU_ ClutchUnit 49;
BA_ "NmStationAddress" BU_ RampControl 66;
BA_ "NmJ1939Function" BU_ RampControl 48;
BA_ "NmStationAddress" BU_ InformationSystem1 65;
BA_ "NmJ1939Function" BU_ InformationSystem1 47;
BA_ "NmStationAddress" BU_ SuspensionSystemController2 64;
BA_ "NmJ1939Function" BU_ SuspensionSystemController2 35;
BA_ "NmJ1939FunctionInstance" BU_ SuspensionSystemController2 1;
BA_ "NmStationAddress" BU_ OilSensor 63;
BA_ "NmJ1939Function" BU_ OilSensor 46;
BA_ "NmStationAddress" BU_ VehicleDynamicStability 62;
BA_ "NmJ1939Function" BU_ VehicleDynamicStability 45;
BA_ "NmStationAddress" BU_ ExhaustEmissionController 61;
BA_ "NmJ1939Function" BU_ ExhaustEmissionController 44;
BA_ "NmStationAddress" BU_ TransmissionDisplay2 60;
BA_ "NmJ1939Function" BU_ TransmissionDisplay2 43;
BA_ "NmJ1939FunctionInstance" BU_ TransmissionDisplay2 1;
BA_ "NmStationAddress" BU_ TransmissionDisplay1 59;
BA_ "NmJ1939Function" BU_ TransmissionDisplay1 43;
BA_ "NmStationAddress" BU_ ClimateControl2 58;
BA_ "NmJ1939Function" BU_ ClimateControl2 21;
BA_ "NmJ1939FunctionInstance" BU_ ClimateControl2 1;
BA_ "NmStationAddress" BU_ WaterPumpController 57;
BA_ "NmJ1939Function" BU_ WaterPumpController 42;
BA_ "NmStationAddress" BU_ RearAxleSteeringController 56;
BA_ "NmJ1939Function" BU_ RearAxleSteeringController 16;
BA_ "NmJ1939FunctionInstance" BU_ RearAxleSteeringController 1;
BA_ "NmStationAddress" BU_ LightingOperatorControl 55;
BA_ "NmJ1939Function" BU_ LightingOperatorControl 41;
BA_ "NmStationAddress" BU_ SeatController1 54;
BA_ "NmJ1939Function" BU_ SeatController1 40;
BA_ "NmStationAddress" BU_ IgnitionController2 53;
BA_ "NmJ1939Function" BU_ IgnitionController2 39;
BA_ "NmJ1939FunctionInstance" BU_ IgnitionController2 1;
BA_ "NmStationAddress" BU_ IgnitionController1 52;
BA_ "NmJ1939Function" BU_ IgnitionController1 39;
BA_ "NmStationAddress" BU_ TirePressureController 51;
BA_ "NmJ1939Function" BU_ TirePressureController 38;
BA_ "NmStationAddress" BU_ CabController2 50;
BA_ "NmJ1939Function" BU_ CabController2 37;
BA_ "NmJ1939FunctionInstance" BU_ CabController2 1;
BA_ "NmStationAddress" BU_ CabController1 49;
BA_ "NmJ1939Function" BU_ CabController1 37;
BA_ "NmStationAddress" BU_ PneumaticSystemController 48;
BA_ "NmJ1939Function" BU_ PneumaticSystemController 36;
BA_ "NmStationAddress" BU_ SuspensionSystemController1 47;
BA_ "NmJ1939Function" BU_ SuspensionSystemController1 35;
BA_ "NmStationAddress" BU_ HydraulicPumpController 46;
BA_ "NmJ1939Function" BU_ HydraulicPumpController 34;
BA_ "NmStationAddress" BU_ EnduranceBrakingSystem 45;
BA_ "NmJ1939Function" BU_ EnduranceBrakingSystem 64;
BA_ "NmStationAddress" BU_ RetarderExhaustEngine2 44;
BA_ "NmJ1939Function" BU_ RetarderExhaustEngine2 12;
BA_ "NmJ1939FunctionInstance" BU_ RetarderExhaustEngine2 1;
BA_ "NmStationAddress" BU_ OnBoardDiagnosticUnit 43;
BA_ "NmJ1939Function" BU_ OnBoardDiagnosticUnit 62;
BA_ "NmStationAddress" BU_ HeadwayController 42;
BA_ "NmJ1939Function" BU_ HeadwayController 32;
BA_ "NmStationAddress" BU_ RetarderExhaustEngine1 41;
BA_ "NmJ1939Function" BU_ RetarderExhaustEngine1 12;
BA_ "NmStationAddress" BU_ CabDisplay1 40;
BA_ "NmJ1939Function" BU_ CabDisplay1 60;
BA_ "NmStationAddress" BU_ ManagementComputer 39;
BA_ "NmJ1939Function" BU_ ManagementComputer 30;
BA_ "NmStationAddress" BU_ VirtualTerminal 38;
BA_ "NmJ1939Function" BU_ VirtualTerminal 29;
BA_ "NmStationAddress" BU_ OffVehicleGateway 37;
BA_ "NmJ1939Function" BU_ OffVehicleGateway 28;
BA_ "NmStationAddress" BU_ PowerTakeOffFront 36;
BA_ "NmJ1939Function" BU_ PowerTakeOffFront 27;
BA_ "NmStationAddress" BU_ HitchControl 35;
BA_ "NmStationAddress" BU_ AuxiliaryValveControl 34;
BA_ "NmJ1939IndustryGroup" BU_ AuxiliaryValveControl 2;
BA_ "NmJ1939System" BU_ AuxiliaryValveControl 1;
BA_ "NmJ1939Function" BU_ AuxiliaryValveControl 129;
BA_ "NmStationAddress" BU_ BodyController 33;
BA_ "NmJ1939Function" BU_ BodyController 26;
BA_ "NmStationAddress" BU_ TractorTrailerBridge1 32;
BA_ "NmJ1939Function" BU_ TractorTrailerBridge1 25;
BA_ "NmStationAddress" BU_ StarterSystem 31;
BA_ "NmJ1939Function" BU_ StarterSystem 59;
BA_ "NmStationAddress" BU_ ElectricalSystem 30;
BA_ "NmJ1939Function" BU_ ElectricalSystem 67;
BA_ "NmStationAddress" BU_ VehicleSecurity 29;
BA_ "NmJ1939Function" BU_ VehicleSecurity 24;
BA_ "NmStationAddress" BU_ VehicleNavigation 28;
BA_ "NmJ1939Function" BU_ VehicleNavigation 23;
BA_ "NmStationAddress" BU_ AerodynamicControl 27;
BA_ "NmJ1939Function" BU_ AerodynamicControl 22;
BA_ "NmStationAddress" BU_ ElectricalChargingSystem 26;
BA_ "NmJ1939Function" BU_ ElectricalChargingSystem 53;
BA_ "NmStationAddress" BU_ ClimateControl1 25;
BA_ "NmJ1939Function" BU_ ClimateControl1 21;
BA_ "NmStationAddress" BU_ TripRecorder 24;
BA_ "NmJ1939Function" BU_ TripRecorder 20;
BA_ "NmStationAddress" BU_ InstrumentCluster 23;
BA_ "NmJ1939Function" BU_ InstrumentCluster 19;
BA_ "NmStationAddress" BU_ SuspensionDriveAxle2 22;
BA_ "NmJ1939Function" BU_ SuspensionDriveAxle2 18;
BA_ "NmJ1939FunctionInstance" BU_ SuspensionDriveAxle2 1;
BA_ "NmStationAddress" BU_ SuspensionDriveAxle1 21;
BA_ "NmJ1939Function" BU_ SuspensionDriveAxle1 18;
BA_ "NmStationAddress" BU_ SuspensionSteerAxle 20;
BA_ "NmJ1939Function" BU_ SuspensionSteerAxle 17;
BA_ "NmStationAddress" BU_ SteeringController 19;
BA_ "NmJ1939Function" BU_ SteeringController 16;
BA_ "NmStationAddress" BU_ FuelSystem 18;
BA_ "NmJ1939Function" BU_ FuelSystem 15;
BA_ "NmStationAddress" BU_ CruiseControl 17;
BA_ "NmJ1939Function" BU_ CruiseControl 14;
BA_ "NmStationAddress" BU_ RetarderDriveline 16;
BA_ "NmJ1939Function" BU_ RetarderDriveline 13;
BA_ "NmStationAddress" BU_ RetarderEngine 15;
BA_ "NmJ1939Function" BU_ RetarderEngine 12;
BA_ "NmStationAddress" BU_ BrakesDriveAxle2 14;
BA_ "NmJ1939Function" BU_ BrakesDriveAxle2 11;
BA_ "NmJ1939FunctionInstance" BU_ BrakesDriveAxle2 1;
BA_ "NmStationAddress" BU_ BrakesDriveAxle1 13;
BA_ "NmJ1939Function" BU_ BrakesDriveAxle1 11;
BA_ "NmStationAddress" BU_ BrakesSystemController 11;
BA_ "NmJ1939Function" BU_ BrakesSystemController 9;
BA_ "NmStationAddress" BU_ BrakesSteerAxle 12;
BA_ "NmJ1939Function" BU_ BrakesSteerAxle 10;
BA_ "NmStationAddress" BU_ AxleDrive2 10;
BA_ "NmJ1939Function" BU_ AxleDrive2 8;
BA_ "NmJ1939FunctionInstance" BU_ AxleDrive2 1;
BA_ "NmStationAddress" BU_ AxleDrive1 9;
BA_ "NmJ1939Function" BU_ AxleDrive1 8;
BA_ "NmStationAddress" BU_ AxleSteering 8;
BA_ "NmJ1939Function" BU_ AxleSteering 7;
BA_ "NmStationAddress" BU_ PowerTakeOff 7;
BA_ "NmJ1939Function" BU_ PowerTakeOff 6;
BA_ "NmStationAddress" BU_ ShiftConsoleSecondary 6;
BA_ "NmJ1939Function" BU_ ShiftConsoleSecondary 5;
BA_ "NmJ1939FunctionInstance" BU_ ShiftConsoleSecondary 1;
BA_ "NmStationAddress" BU_ ShiftConsolePrimary 5;
BA_ "NmJ1939Function" BU_ ShiftConsolePrimary 5;
BA_ "NmStationAddress" BU_ Transmission2 4;
BA_ "NmJ1939Function" BU_ Transmission2 3;
BA_ "NmJ1939FunctionInstance" BU_ Transmission2 1;
BA_ "NmStationAddress" BU_ Transmission1 3;
BA_ "NmJ1939Function" BU_ Transmission1 3;
BA_ "NmStationAddress" BU_ Engine2 1;
BA_ "NmJ1939FunctionInstance" BU_ Engine2 1;
BA_ "NmStationAddress" BU_ Engine1 0;
BA_ "GenMsgSendType" BO_ 2365342974 0;
BA_ "GenMsgCycleTime" BO_ 2365342974 100;
BA_ "GenMsgSendType" BO_ 2566662398 0;
BA_ "GenMsgCycleTime" BO_ 2566662398 1000;
BA_ "GenMsgSendType" BO_ 2365334014 0;
BA_ "GenMsgCycleTime" BO_ 2365334014 100;
BA_ "GenMsgSendType" BO_ 2365333758 0;
BA_ "GenMsgCycleTime" BO_ 2365333758 100;
BA_ "GenMsgSendType" BO_ 2566660094 0;
BA_ "GenMsgCycleTime" BO_ 2566660094 1000;
BA_ "GenMsgSendType" BO_ 2566659838 0;
BA_ "GenMsgCycleTime" BO_ 2566659838 1000;
BA_ "GenMsgSendType" BO_ 2633768446 0;
BA_ "GenMsgCycleTime" BO_ 2633768446 10000;
BA_ "GenMsgSendType" BO_ 2633768190 0;
BA_ "GenMsgCycleTime" BO_ 2633768190 30000;
BA_ "GenMsgSendType" BO_ 2633761022 0;
BA_ "GenMsgCycleTime" BO_ 2633761022 30000;
BA_ "GenMsgSendType" BO_ 2566648574 0;
BA_ "GenMsgCycleTime" BO_ 2566648574 500;
BA_ "TpJ1939VarDlc" BO_ 2566584574 1;
BA_ "GenMsgDelayTime" BO_ 2566584574 1000;
BA_ "GenMsgDelayTime" BO_ 2499428094 100;
BA_ "GenMsgSendType" BO_ 2499428094 0;
BA_ "GenMsgCycleTime" BO_ 2499428094 1000;
BA_ "GenMsgSendType" BO_ 2566536702 0;
BA_ "GenMsgCycleTime" BO_ 2566536702 500;
BA_ "GenMsgSendType" BO_ 2566536446 0;
BA_ "GenMsgCycleTime" BO_ 2566536446 100;
BA_ "GenMsgSendType" BO_ 2566536190 0;
BA_ "GenMsgCycleTime" BO_ 2566536190 100;
BA_ "FsJ1939UseCrcAndCounter" BO_ 2566535934 "Bc";
BA_ "GenMsgSendType" BO_ 2566535934 0;
BA_ "GenMsgCycleTime" BO_ 2566535934 100;
BA_ "GenMsgSendType" BO_ 2566535678 0;
BA_ "GenMsgCycleTime" BO_ 2566535678 100;
BA_ "GenMsgSendType" BO_ 2566535422 0;
BA_ "GenMsgCycleTime" BO_ 2566535422 100;
BA_ "GenMsgSendType" BO_ 2566535166 0;
BA_ "GenMsgCycleTime" BO_ 2566535166 100;
BA_ "GenMsgSendType" BO_ 2566534910 0;
BA_ "GenMsgCycleTime" BO_ 2566534910 500;
BA_ "GenMsgSendType" BO_ 2499425790 0;
BA_ "GenMsgCycleTime" BO_ 2499425790 100;
BA_ "GenMsgDelayTime" BO_ 2365207806 100;
BA_ "GenMsgSendType" BO_ 2365207806 0;
BA_ "GenMsgCycleTime" BO_ 2365207806 1000;
BA_ "GenMsgDelayTime" BO_ 2365207550 100;
BA_ "GenMsgSendType" BO_ 2365207550 0;
BA_ "GenMsgCycleTime" BO_ 2365207550 1000;
BA_ "GenMsgSendType" BO_ 2365207294 0;
BA_ "GenMsgCycleTime" BO_ 2365207294 100;
BA_ "GenMsgSendType" BO_ 2365207038 0;
BA_ "GenMsgCycleTime" BO_ 2365207038 100;
BA_ "GenMsgSendType" BO_ 2365206782 0;
BA_ "GenMsgCycleTime" BO_ 2365206782 100;
BA_ "GenMsgSendType" BO_ 2365206526 0;
BA_ "GenMsgCycleTime" BO_ 2365206526 100;
BA_ "GenMsgSendType" BO_ 2365206270 0;
BA_ "GenMsgCycleTime" BO_ 2365206270 100;
BA_ "GenMsgSendType" BO_ 2365206014 0;
BA_ "GenMsgCycleTime" BO_ 2365206014 100;
BA_ "SPN" SG_ 3221225472 SourceAddress 5600;
BA_ "SPN" SG_ 3221225472 NncntnuslyMonitoredSystemsStatus 1223;
BA_ "SPN" SG_ 3221225472 NncntnslyMonitoredSystemsSupport 1222;
BA_ "SPN" SG_ 3221225472 CntnslyMntrdSystmsSupport_Status 1221;
BA_ "SigType" SG_ 3221225472 AETCTorqueValue 1;
BA_ "SPN" SG_ 3221225472 AETCTorqueValue 3561;
BA_ "SigType" SG_ 3221225472 TrailerWeight 1;
BA_ "SPN" SG_ 3221225472 TrailerWeight 180;
BA_ "SPN" SG_ 3221225472 ReferenceTirePressSetting 3193;
BA_ "SPN" SG_ 3221225472 ReferenceTirePress 3191;
BA_ "SPN" SG_ 3221225472 TirePressThresholdDetection 2587;
BA_ "SigType" SG_ 3221225472 TireAirLeakageRate 1;
BA_ "SPN" SG_ 3221225472 TireAirLeakageRate 2586;
BA_ "SigType" SG_ 3221225472 CTIWheelEndElectricalFault 4;
BA_ "SPN" SG_ 3221225472 CTIWheelEndElectricalFault 1697;
BA_ "SigType" SG_ 3221225472 CTITireStatus 4;
BA_ "SPN" SG_ 3221225472 CTITireStatus 1698;
BA_ "SigType" SG_ 3221225472 CTIWheelSensorStatus 4;
BA_ "SPN" SG_ 3221225472 CTIWheelSensorStatus 1699;
BA_ "SigType" SG_ 3221225472 TireTemp 1;
BA_ "SPN" SG_ 3221225472 TireTemp 242;
BA_ "SigType" SG_ 3221225472 TirePress 1;
BA_ "SPN" SG_ 3221225472 TirePress 241;
BA_ "SigType" SG_ 3221225472 EngTurningGearEngaged 4;
BA_ "SPN" SG_ 3221225472 EngTurningGearEngaged 1206;
BA_ "SigType" SG_ 3221225472 AETCSpeedValue 1;
BA_ "SPN" SG_ 3221225472 AETCSpeedValue 3560;
BA_ "SigType" SG_ 2365342974 NomChargeCurLmt 1;
BA_ "GenSigStartValue" SG_ 2365342974 NomChargeCurLmt 32000;
BA_ "SPN" SG_ 2365342974 NomChargeCurLmt 22850;
BA_ "SigType" SG_ 2365342974 NomDisCurLmt 1;
BA_ "SPN" SG_ 2365342974 NomDisCurLmt 22849;
BA_ "SigType" SG_ 2566662398 MapBasedVSLmt 1;
BA_ "SPN" SG_ 2566662398 MapBasedVSLmt 22773;
BA_ "SigType" SG_ 2566662398 CurRoadwayVSLmt 1;
BA_ "SPN" SG_ 2566662398 CurRoadwayVSLmt 22772;
BA_ "SigType" SG_ 2566662398 SelectedRoadwayVSLmt 1;
BA_ "SPN" SG_ 2566662398 SelectedRoadwayVSLmt 22771;
BA_ "SPN" SG_ 2566662398 CurRoadwayVSLmtMode 22770;
BA_ "SigType" SG_ 2365334014 Module96OperationalSt 4;
BA_ "SPN" SG_ 2365334014 Module96OperationalSt 22914;
BA_ "SigType" SG_ 2365334014 Module95OperationalSt 4;
BA_ "SPN" SG_ 2365334014 Module95OperationalSt 22913;
BA_ "SigType" SG_ 2365334014 Module94OperationalSt 4;
BA_ "SPN" SG_ 2365334014 Module94OperationalSt 22912;
BA_ "SigType" SG_ 2365334014 Module93OperationalSt 4;
BA_ "SPN" SG_ 2365334014 Module93OperationalSt 22911;
BA_ "SigType" SG_ 2365334014 Module92OperationalSt 4;
BA_ "SPN" SG_ 2365334014 Module92OperationalSt 22910;
BA_ "SigType" SG_ 2365334014 Module91OperationalSt 4;
BA_ "SPN" SG_ 2365334014 Module91OperationalSt 22909;
BA_ "SigType" SG_ 2365334014 Module90OperationalSt 4;
BA_ "SPN" SG_ 2365334014 Module90OperationalSt 22908;
BA_ "SigType" SG_ 2365334014 Module89OperationalSt 4;
BA_ "SPN" SG_ 2365334014 Module89OperationalSt 22907;
BA_ "SigType" SG_ 2365334014 Module88OperationalSt 4;
BA_ "SPN" SG_ 2365334014 Module88OperationalSt 22906;
BA_ "SigType" SG_ 2365334014 Module87OperationalSt 4;
BA_ "SPN" SG_ 2365334014 Module87OperationalSt 22905;
BA_ "SigType" SG_ 2365334014 Module86OperationalSt 4;
BA_ "SPN" SG_ 2365334014 Module86OperationalSt 22904;
BA_ "SigType" SG_ 2365334014 Module85OperationalSt 4;
BA_ "SPN" SG_ 2365334014 Module85OperationalSt 22903;
BA_ "SigType" SG_ 2365334014 Module84OperationalSt 4;
BA_ "SPN" SG_ 2365334014 Module84OperationalSt 22902;
BA_ "SigType" SG_ 2365334014 Module83OperationalSt 4;
BA_ "SPN" SG_ 2365334014 Module83OperationalSt 22901;
BA_ "SigType" SG_ 2365334014 Module82OperationalSt 4;
BA_ "SPN" SG_ 2365334014 Module82OperationalSt 22900;
BA_ "SigType" SG_ 2365334014 Module81OperationalSt 4;
BA_ "SPN" SG_ 2365334014 Module81OperationalSt 22899;
BA_ "SigType" SG_ 2365334014 Module80OperationalSt 4;
BA_ "SPN" SG_ 2365334014 Module80OperationalSt 22898;
BA_ "SigType" SG_ 2365334014 Module79OperationalSt 4;
BA_ "SPN" SG_ 2365334014 Module79OperationalSt 22897;
BA_ "SigType" SG_ 2365334014 Module78OperationalSt 4;
BA_ "SPN" SG_ 2365334014 Module78OperationalSt 22896;
BA_ "SigType" SG_ 2365334014 Module77OperationalSt 4;
BA_ "SPN" SG_ 2365334014 Module77OperationalSt 22895;
BA_ "SigType" SG_ 2365334014 Module76OperationalSt 4;
BA_ "SPN" SG_ 2365334014 Module76OperationalSt 22894;
BA_ "SigType" SG_ 2365334014 Module75OperationalSt 4;
BA_ "SPN" SG_ 2365334014 Module75OperationalSt 22893;
BA_ "SigType" SG_ 2365334014 Module74OperationalSt 4;
BA_ "SPN" SG_ 2365334014 Module74OperationalSt 22892;
BA_ "SigType" SG_ 2365334014 Module73OperationalSt 4;
BA_ "SPN" SG_ 2365334014 Module73OperationalSt 22891;
BA_ "SigType" SG_ 2365334014 Module72OperationalSt 4;
BA_ "SPN" SG_ 2365334014 Module72OperationalSt 22890;
BA_ "SigType" SG_ 2365334014 Module71OperationalSt 4;
BA_ "SPN" SG_ 2365334014 Module71OperationalSt 22889;
BA_ "SigType" SG_ 2365334014 Module70OperationalSt 4;
BA_ "SPN" SG_ 2365334014 Module70OperationalSt 22888;
BA_ "SigType" SG_ 2365334014 Module69OperationalSt 4;
BA_ "SPN" SG_ 2365334014 Module69OperationalSt 22887;
BA_ "SigType" SG_ 2365334014 Module68OperationalSt 4;
BA_ "SPN" SG_ 2365334014 Module68OperationalSt 22886;
BA_ "SigType" SG_ 2365334014 Module67OperationalSt 4;
BA_ "SPN" SG_ 2365334014 Module67OperationalSt 22885;
BA_ "SigType" SG_ 2365334014 Module66OperationalSt 4;
BA_ "SPN" SG_ 2365334014 Module66OperationalSt 22884;
BA_ "SigType" SG_ 2365334014 Module65OperationalSt 4;
BA_ "SPN" SG_ 2365334014 Module65OperationalSt 22883;
BA_ "SigType" SG_ 2365333758 Module64OperationalSt 4;
BA_ "SPN" SG_ 2365333758 Module64OperationalSt 22882;
BA_ "SigType" SG_ 2365333758 Module63OperationalSt 4;
BA_ "SPN" SG_ 2365333758 Module63OperationalSt 22881;
BA_ "SigType" SG_ 2365333758 Module62OperationalSt 4;
BA_ "SPN" SG_ 2365333758 Module62OperationalSt 22880;
BA_ "SigType" SG_ 2365333758 Module61OperationalSt 4;
BA_ "SPN" SG_ 2365333758 Module61OperationalSt 22879;
BA_ "SigType" SG_ 2365333758 Module60OperationalSt 4;
BA_ "SPN" SG_ 2365333758 Module60OperationalSt 22878;
BA_ "SigType" SG_ 2365333758 Module59OperationalSt 4;
BA_ "SPN" SG_ 2365333758 Module59OperationalSt 22877;
BA_ "SigType" SG_ 2365333758 Module58OperationalSt 4;
BA_ "SPN" SG_ 2365333758 Module58OperationalSt 22876;
BA_ "SigType" SG_ 2365333758 Module57OperationalSt 4;
BA_ "SPN" SG_ 2365333758 Module57OperationalSt 22875;
BA_ "SigType" SG_ 2365333758 Module56OperationalSt 4;
BA_ "SPN" SG_ 2365333758 Module56OperationalSt 22874;
BA_ "SigType" SG_ 2365333758 Module55OperationalSt 4;
BA_ "SPN" SG_ 2365333758 Module55OperationalSt 22873;
BA_ "SigType" SG_ 2365333758 Module54OperationalSt 4;
BA_ "SPN" SG_ 2365333758 Module54OperationalSt 22872;
BA_ "SigType" SG_ 2365333758 Module53OperationalSt 4;
BA_ "SPN" SG_ 2365333758 Module53OperationalSt 22871;
BA_ "SigType" SG_ 2365333758 Module52OperationalSt 4;
BA_ "SPN" SG_ 2365333758 Module52OperationalSt 22870;
BA_ "SigType" SG_ 2365333758 Module51OperationalSt 4;
BA_ "SPN" SG_ 2365333758 Module51OperationalSt 22869;
BA_ "SigType" SG_ 2365333758 Module50OperationalSt 4;
BA_ "SPN" SG_ 2365333758 Module50OperationalSt 22868;
BA_ "SigType" SG_ 2365333758 Module49OperationalSt 4;
BA_ "SPN" SG_ 2365333758 Module49OperationalSt 22867;
BA_ "SigType" SG_ 2365333758 Module48OperationalSt 4;
BA_ "SPN" SG_ 2365333758 Module48OperationalSt 22866;
BA_ "SigType" SG_ 2365333758 Module47OperationalSt 4;
BA_ "SPN" SG_ 2365333758 Module47OperationalSt 22865;
BA_ "SigType" SG_ 2365333758 Module46OperationalSt 4;
BA_ "SPN" SG_ 2365333758 Module46OperationalSt 22864;
BA_ "SigType" SG_ 2365333758 Module45OperationalSt 4;
BA_ "SPN" SG_ 2365333758 Module45OperationalSt 22863;
BA_ "SigType" SG_ 2365333758 Module44OperationalSt 4;
BA_ "SPN" SG_ 2365333758 Module44OperationalSt 22862;
BA_ "SigType" SG_ 2365333758 Module43OperationalSt 4;
BA_ "SPN" SG_ 2365333758 Module43OperationalSt 22861;
BA_ "SigType" SG_ 2365333758 Module42OperationalSt 4;
BA_ "SPN" SG_ 2365333758 Module42OperationalSt 22860;
BA_ "SigType" SG_ 2365333758 Module41OperationalSt 4;
BA_ "SPN" SG_ 2365333758 Module41OperationalSt 22859;
BA_ "SigType" SG_ 2365333758 Module40OperationalSt 4;
BA_ "SPN" SG_ 2365333758 Module40OperationalSt 22858;
BA_ "SigType" SG_ 2365333758 Module39OperationalSt 4;
BA_ "SPN" SG_ 2365333758 Module39OperationalSt 22857;
BA_ "SigType" SG_ 2365333758 Module38OperationalSt 4;
BA_ "SPN" SG_ 2365333758 Module38OperationalSt 22856;
BA_ "SigType" SG_ 2365333758 Module37OperationalSt 4;
BA_ "SPN" SG_ 2365333758 Module37OperationalSt 22855;
BA_ "SigType" SG_ 2365333758 Module36OperationalSt 4;
BA_ "SPN" SG_ 2365333758 Module36OperationalSt 22854;
BA_ "SigType" SG_ 2365333758 Module35OperationalSt 4;
BA_ "SPN" SG_ 2365333758 Module35OperationalSt 22853;
BA_ "SigType" SG_ 2365333758 Module34OperationalSt 4;
BA_ "SPN" SG_ 2365333758 Module34OperationalSt 22852;
BA_ "SigType" SG_ 2365333758 Module33OperationalSt 4;
BA_ "SPN" SG_ 2365333758 Module33OperationalSt 22851;
BA_ "SigType" SG_ 2566660094 SLIBatPack1Bat4DisCurLmt 1;
BA_ "GenSigStartValue" SG_ 2566660094 SLIBatPack1Bat4DisCurLmt 31980;
BA_ "SPN" SG_ 2566660094 SLIBatPack1Bat4DisCurLmt 22753;
BA_ "SigType" SG_ 2566660094 SLIBatPack1Bat3DisCurLmt 1;
BA_ "GenSigStartValue" SG_ 2566660094 SLIBatPack1Bat3DisCurLmt 31980;
BA_ "SPN" SG_ 2566660094 SLIBatPack1Bat3DisCurLmt 22752;
BA_ "SigType" SG_ 2566660094 SLIBatPack1Bat2DisCurLmt 1;
BA_ "GenSigStartValue" SG_ 2566660094 SLIBatPack1Bat2DisCurLmt 31980;
BA_ "SPN" SG_ 2566660094 SLIBatPack1Bat2DisCurLmt 22751;
BA_ "SigType" SG_ 2566660094 SLIBatPack1Bat1DisCurLmt 1;
BA_ "GenSigStartValue" SG_ 2566660094 SLIBatPack1Bat1DisCurLmt 31980;
BA_ "SPN" SG_ 2566660094 SLIBatPack1Bat1DisCurLmt 22750;
BA_ "SigType" SG_ 2566659838 SLIBatPack1Bat4ChargeCurLmt 1;
BA_ "GenSigStartValue" SG_ 2566659838 SLIBatPack1Bat4ChargeCurLmt 32000;
BA_ "SPN" SG_ 2566659838 SLIBatPack1Bat4ChargeCurLmt 22749;
BA_ "SigType" SG_ 2566659838 SLIBatPack1Bat3ChargeCurLmt 1;
BA_ "GenSigStartValue" SG_ 2566659838 SLIBatPack1Bat3ChargeCurLmt 32000;
BA_ "SPN" SG_ 2566659838 SLIBatPack1Bat3ChargeCurLmt 22748;
BA_ "SigType" SG_ 2566659838 SLIBatPack1Bat2ChargeCurLmt 1;
BA_ "GenSigStartValue" SG_ 2566659838 SLIBatPack1Bat2ChargeCurLmt 32000;
BA_ "SPN" SG_ 2566659838 SLIBatPack1Bat2ChargeCurLmt 22747;
BA_ "SigType" SG_ 2566659838 SLIBatPack1Bat1ChargeCurLmt 1;
BA_ "GenSigStartValue" SG_ 2566659838 SLIBatPack1Bat1ChargeCurLmt 32000;
BA_ "SPN" SG_ 2566659838 SLIBatPack1Bat1ChargeCurLmt 22746;
BA_ "SigType" SG_ 2633768446 TransportationCompartmentDoorSt 5;
BA_ "SPN" SG_ 2633768446 TransportationCompartmentDoorSt 3617;
BA_ "SigType" SG_ 2633768446 TransportationCompartmentDoorID 1;
BA_ "SPN" SG_ 2633768446 TransportationCompartmentDoorID 3616;
BA_ "SigType" SG_ 2633768190 RefrigeratedCompartmentTemp 1;
BA_ "SPN" SG_ 2633768190 RefrigeratedCompartmentTemp 3450;
BA_ "SigType" SG_ 2633768190 RefrigeratedCompartmentHumidity 1;
BA_ "SPN" SG_ 2633768190 RefrigeratedCompartmentHumidity 3449;
BA_ "SPN" SG_ 2633768190 RefrigeratedCompartmentID 3321;
BA_ "SigType" SG_ 2633768190 RefrigeratedCompartmentPos 1;
BA_ "SPN" SG_ 2633768190 RefrigeratedCompartmentPos 3320;
BA_ "SigType" SG_ 2633761022 RemTlrAxle8RightWheel 1;
BA_ "SPN" SG_ 2633761022 RemTlrAxle8RightWheel 22769;
BA_ "SigType" SG_ 2633761022 RemTlrAxle8LeftWheel 1;
BA_ "SPN" SG_ 2633761022 RemTlrAxle8LeftWheel 22768;
BA_ "SigType" SG_ 2633761022 RemTlrAxle7RightWheel 1;
BA_ "SPN" SG_ 2633761022 RemTlrAxle7RightWheel 22767;
BA_ "SigType" SG_ 2633761022 RemTlrAxle7LeftWheel 1;
BA_ "SPN" SG_ 2633761022 RemTlrAxle7LeftWheel 22766;
BA_ "SigType" SG_ 2633761022 RemTlrAxle6RightWheel 1;
BA_ "SPN" SG_ 2633761022 RemTlrAxle6RightWheel 22765;
BA_ "SigType" SG_ 2633761022 RemTlrAxle6LeftWheel 1;
BA_ "SPN" SG_ 2633761022 RemTlrAxle6LeftWheel 22764;
BA_ "SigType" SG_ 2633761022 RemTlrAxle5RightWheel 1;
BA_ "SPN" SG_ 2633761022 RemTlrAxle5RightWheel 22763;
BA_ "SigType" SG_ 2633761022 RemTlrAxle5LeftWheel 1;
BA_ "SPN" SG_ 2633761022 RemTlrAxle5LeftWheel 22762;
BA_ "SigType" SG_ 2633761022 RemTlrAxle4RightWheel 1;
BA_ "SPN" SG_ 2633761022 RemTlrAxle4RightWheel 22761;
BA_ "SigType" SG_ 2633761022 RemTlrAxle4LeftWheel 1;
BA_ "SPN" SG_ 2633761022 RemTlrAxle4LeftWheel 22760;
BA_ "SigType" SG_ 2633761022 RemTlrAxle3RightWheel 1;
BA_ "SPN" SG_ 2633761022 RemTlrAxle3RightWheel 22759;
BA_ "SigType" SG_ 2633761022 RemTlrAxle3LeftWheel 1;
BA_ "SPN" SG_ 2633761022 RemTlrAxle3LeftWheel 22758;
BA_ "SigType" SG_ 2633761022 RemTlrAxle2RightWheel 1;
BA_ "SPN" SG_ 2633761022 RemTlrAxle2RightWheel 22757;
BA_ "SigType" SG_ 2633761022 RemTlrAxle2LeftWheel 1;
BA_ "SPN" SG_ 2633761022 RemTlrAxle2LeftWheel 22756;
BA_ "SigType" SG_ 2633761022 RemTlrAxle1RightWheel 1;
BA_ "SPN" SG_ 2633761022 RemTlrAxle1RightWheel 22755;
BA_ "SigType" SG_ 2633761022 RemTlrAxle1LeftWheel 1;
BA_ "SPN" SG_ 2633761022 RemTlrAxle1LeftWheel 22754;
BA_ "SigType" SG_ 2566648574 FuelFilter 1;
BA_ "SPN" SG_ 2566648574 FuelFilter 22745;
BA_ "SigType" SG_ 2566648574 FuelFilterDiffPress 1;
BA_ "SPN" SG_ 2566648574 FuelFilterDiffPress 22744;
BA_ "SigType" SG_ 2566584574 TrqValue 1;
BA_ "SPN" SG_ 2566584574 TrqValue 22717;
BA_ "SigType" SG_ 2566584574 SpdValue 1;
BA_ "SPN" SG_ 2566584574 SpdValue 22716;
BA_ "SigType" SG_ 2566584574 ReferenceNetTrq 1;
BA_ "SPN" SG_ 2566584574 ReferenceNetTrq 22715;
BA_ "SigType" SG_ 2566584574 ActiveDerate 5;
BA_ "SPN" SG_ 2566584574 ActiveDerate 22714;
BA_ "SPN" SG_ 2566584574 TotalCount 22774;
BA_ "SPN" SG_ 2566584574 ActiveInstance 22713;
BA_ "GenSigStartValue" SG_ 2566584574 Instance 1;
BA_ "SPN" SG_ 2566584574 Instance 22712;
BA_ "GenSigStartValue" SG_ 2566584574 NumOfPoints 2;
BA_ "SPN" SG_ 2566584574 NumOfPoints 22711;
BA_ "SigType" SG_ 2566537214 CoolingFanInManifoldActTemp 1;
BA_ "SPN" SG_ 2566537214 CoolingFanInManifoldActTemp 21791;
BA_ "SigType" SG_ 2566537214 CoolingFanCoolantActTemp 1;
BA_ "SPN" SG_ 2566537214 CoolingFanCoolantActTemp 21790;
BA_ "SigType" SG_ 2499428094 SignSpdLmt 1;
BA_ "SPN" SG_ 2499428094 SignSpdLmt 21793;
BA_ "SigType" SG_ 2566536702 GasFuel2SupplyPressRegPos 1;
BA_ "SPN" SG_ 2566536702 GasFuel2SupplyPressRegPos 21847;
BA_ "SigType" SG_ 2566536702 GasFuel1SupplyPressRegPos 1;
BA_ "SPN" SG_ 2566536702 GasFuel1SupplyPressRegPos 21846;
BA_ "SigType" SG_ 2566536702 GasFuel2SupplyPressRegOutPress 1;
BA_ "SPN" SG_ 2566536702 GasFuel2SupplyPressRegOutPress 21845;
BA_ "SigType" SG_ 2566536702 GasFuel1SupplyPressRegOutPress 1;
BA_ "SPN" SG_ 2566536702 GasFuel1SupplyPressRegOutPress 21844;
BA_ "SigType" SG_ 2566536702 GasFuel2SupplyPress1 1;
BA_ "SPN" SG_ 2566536702 GasFuel2SupplyPress1 21843;
BA_ "SigType" SG_ 2566536446 TwoV 1;
BA_ "SPN" SG_ 2566536446 TwoV 22142;
BA_ "SigType" SG_ 2566536446 TwoAir_FuelEquivalenceRatio 1;
BA_ "SPN" SG_ 2566536446 TwoAir_FuelEquivalenceRatio 22141;
BA_ "SigType" SG_ 2566536446 OneV 1;
BA_ "SPN" SG_ 2566536446 OneV 22140;
BA_ "SigType" SG_ 2566536446 OneAir_FuelEquivalenceRatio 1;
BA_ "SPN" SG_ 2566536446 OneAir_FuelEquivalenceRatio 22139;
BA_ "SigType" SG_ 2566536190 EPTO1V 1;
BA_ "SPN" SG_ 2566536190 EPTO1V 22156;
BA_ "SigType" SG_ 2566536190 EPTO1Cur 1;
BA_ "SPN" SG_ 2566536190 EPTO1Cur 22155;
BA_ "SigType" SG_ 2566536190 EPTO1CurLmt 1;
BA_ "SPN" SG_ 2566536190 EPTO1CurLmt 22154;
BA_ "SigType" SG_ 2566535934 ErrorIndEPTO1 5;
BA_ "SPN" SG_ 2566535934 ErrorIndEPTO1 22153;
BA_ "SigType" SG_ 2566535934 SysReadinessEPTO1 5;
BA_ "SPN" SG_ 2566535934 SysReadinessEPTO1 22152;
BA_ "SigType" SG_ 2566535934 EmergDeEnergizeSwEPTO1 5;
BA_ "SPN" SG_ 2566535934 EmergDeEnergizeSwEPTO1 22151;
BA_ "SigType" SG_ 2566535934 EngagementStEPTO1 5;
BA_ "SPN" SG_ 2566535934 EngagementStEPTO1 22150;
BA_ "SigType" SG_ 2566535934 EngagementConsentEPTO1 5;
BA_ "SPN" SG_ 2566535934 EngagementConsentEPTO1 22149;
BA_ "SigType" SG_ 2566535934 EnableSwEPTO1 5;
BA_ "SPN" SG_ 2566535934 EnableSwEPTO1 22148;
BA_ "SigType" SG_ 2566535934 Counter 11;
BA_ "SPN" SG_ 2566535934 Counter 22147;
BA_ "SigType" SG_ 2566535934 CRC 12;
BA_ "SPN" SG_ 2566535934 CRC 22146;
BA_ "SPN" SG_ 2566535678 OutPressProtLvlActiveSt 22213;
BA_ "SigType" SG_ 2566535678 InitialRampGainFactor 1;
BA_ "SPN" SG_ 2566535678 InitialRampGainFactor 22212;
BA_ "SigType" SG_ 2566535678 DisPressRespLvl5Factor 1;
BA_ "SPN" SG_ 2566535678 DisPressRespLvl5Factor 22211;
BA_ "SigType" SG_ 2566535678 DisPressRespLvl4Factor 1;
BA_ "SPN" SG_ 2566535678 DisPressRespLvl4Factor 22210;
BA_ "SigType" SG_ 2566535678 DisPressRespLvl3Factor 1;
BA_ "SPN" SG_ 2566535678 DisPressRespLvl3Factor 22209;
BA_ "SigType" SG_ 2566535678 DisPressRespLvl2Factor 1;
BA_ "SPN" SG_ 2566535678 DisPressRespLvl2Factor 22208;
BA_ "SigType" SG_ 2566535678 DisPressRespLvl1Factor 1;
BA_ "SPN" SG_ 2566535678 DisPressRespLvl1Factor 22207;
BA_ "SigType" SG_ 2566535422 SysCtrlEnableSt 5;
BA_ "SPN" SG_ 2566535422 SysCtrlEnableSt 22206;
BA_ "SigType" SG_ 2566535422 OutPressDiffFromAvg 5;
BA_ "SPN" SG_ 2566535422 OutPressDiffFromAvg 22205;
BA_ "SigType" SG_ 2566535422 PadOperatingPressUpperLmt 1;
BA_ "SPN" SG_ 2566535422 PadOperatingPressUpperLmt 22204;
BA_ "SigType" SG_ 2566535422 OutPressLvl5Percent 1;
BA_ "SPN" SG_ 2566535422 OutPressLvl5Percent 22203;
BA_ "SigType" SG_ 2566535422 OutPressLvl4Percent 1;
BA_ "SPN" SG_ 2566535422 OutPressLvl4Percent 22202;
BA_ "SigType" SG_ 2566535422 OutPressLvl3Percent 1;
BA_ "SPN" SG_ 2566535422 OutPressLvl3Percent 22201;
BA_ "SigType" SG_ 2566535422 OutPressLvl2Percent 1;
BA_ "SPN" SG_ 2566535422 OutPressLvl2Percent 22200;
BA_ "SigType" SG_ 2566535422 OutPressLvl1Percent 1;
BA_ "SPN" SG_ 2566535422 OutPressLvl1Percent 22199;
BA_ "SigType" SG_ 2566535166 TSC1EngCtrlAbortCmd 5;
BA_ "SPN" SG_ 2566535166 TSC1EngCtrlAbortCmd 22216;
BA_ "SigType" SG_ 2566535166 PumpDriveType 5;
BA_ "SPN" SG_ 2566535166 PumpDriveType 22198;
BA_ "SigType" SG_ 2566535166 PumpOutPressHiLmt 1;
BA_ "SPN" SG_ 2566535166 PumpOutPressHiLmt 22197;
BA_ "SigType" SG_ 2566535166 LFCtrlHoldSt 5;
BA_ "SPN" SG_ 2566535166 LFCtrlHoldSt 22196;
BA_ "SigType" SG_ 2566535166 LFCtrlDesSpdInputConfig 5;
BA_ "SPN" SG_ 2566535166 LFCtrlDesSpdInputConfig 22195;
BA_ "SigType" SG_ 2566535166 LFCtrlInputConfig 5;
BA_ "SPN" SG_ 2566535166 LFCtrlInputConfig 22194;
BA_ "SigType" SG_ 2566535166 LFCtrlInstallation 5;
BA_ "SPN" SG_ 2566535166 LFCtrlInstallation 22193;
BA_ "SigType" SG_ 2566534910 ThrotVlv2OutAbsPress 1;
BA_ "SPN" SG_ 2566534910 ThrotVlv2OutAbsPress 22312;
BA_ "SigType" SG_ 2566534910 ThrotVlv2OutPress 1;
BA_ "SPN" SG_ 2566534910 ThrotVlv2OutPress 22311;
BA_ "SigType" SG_ 2566534910 ThrotVlv1OutAbsPress 1;
BA_ "SPN" SG_ 2566534910 ThrotVlv1OutAbsPress 22310;
BA_ "SigType" SG_ 2566534910 ThrotVlv1OutPress 1;
BA_ "SPN" SG_ 2566534910 ThrotVlv1OutPress 22309;
BA_ "SigType" SG_ 2499425790 Overheight_OverwidthSt 5;
BA_ "SPN" SG_ 2499425790 Overheight_OverwidthSt 22317;
BA_ "SigType" SG_ 2499425790 TailgatePos 5;
BA_ "SPN" SG_ 2499425790 TailgatePos 22316;
BA_ "SigType" SG_ 2499425790 FrontLoaderForkPos 5;
BA_ "SPN" SG_ 2499425790 FrontLoaderForkPos 22315;
BA_ "SPN" SG_ 2499425790 FrontLoaderArmPos 22314;
BA_ "SigType" SG_ 2499425790 TransitSt 5;
BA_ "SPN" SG_ 2499425790 TransitSt 22313;
BA_ "SPN" SG_ 2365207806 GeneralFault 22347;
BA_ "SPN" SG_ 2365207806 Color14St 22346;
BA_ "SPN" SG_ 2365207806 Color13St 22345;
BA_ "SPN" SG_ 2365207806 Color12St 22344;
BA_ "SPN" SG_ 2365207806 Color11St 22343;
BA_ "SPN" SG_ 2365207806 Color10St 22342;
BA_ "SPN" SG_ 2365207806 Color9St 22341;
BA_ "SPN" SG_ 2365207806 Color8St 22340;
BA_ "SPN" SG_ 2365207806 Color7St 22339;
BA_ "SPN" SG_ 2365207806 Color6St 22338;
BA_ "SPN" SG_ 2365207806 Color5St 22337;
BA_ "SPN" SG_ 2365207806 Color4St 22336;
BA_ "SPN" SG_ 2365207806 Color3St 22335;
BA_ "SPN" SG_ 2365207806 Color2St 22334;
BA_ "SPN" SG_ 2365207806 Color1St 22333;
BA_ "SPN" SG_ 2365207806 FeedbackSequenceCounter 22332;
BA_ "SPN" SG_ 2365207550 Freq 22331;
BA_ "SigType" SG_ 2365207550 Synch 5;
BA_ "SPN" SG_ 2365207550 Synch 22330;
BA_ "SigType" SG_ 2365207550 Brightness 1;
BA_ "SPN" SG_ 2365207550 Brightness 22329;
BA_ "SPN" SG_ 2365207550 TimeSlot10 22327;
BA_ "SPN" SG_ 2365207550 TimeSlot9 22328;
BA_ "SPN" SG_ 2365207550 TimeSlot8 22325;
BA_ "SPN" SG_ 2365207550 TimeSlot7 22326;
BA_ "SPN" SG_ 2365207550 TimeSlot6 22323;
BA_ "SPN" SG_ 2365207550 TimeSlot5 22324;
BA_ "SPN" SG_ 2365207550 TimeSlot4 22321;
BA_ "SPN" SG_ 2365207550 TimeSlot3 22322;
BA_ "SPN" SG_ 2365207550 TimeSlot2 22319;
BA_ "SPN" SG_ 2365207550 TimeSlot1 22320;
BA_ "SPN" SG_ 2365207550 SequenceCounter 22318;
BA_ "SigType" SG_ 2365207294 HVInternalContactor8St22621 4;
BA_ "SPN" SG_ 2365207294 HVInternalContactor8St22621 22621;
BA_ "SigType" SG_ 2365207294 HVInternalContactor7St22620 4;
BA_ "SPN" SG_ 2365207294 HVInternalContactor7St22620 22620;
BA_ "SigType" SG_ 2365207294 HVInternalContactor6St22619 4;
BA_ "SPN" SG_ 2365207294 HVInternalContactor6St22619 22619;
BA_ "SigType" SG_ 2365207294 HVInternalContactor5St22618 4;
BA_ "SPN" SG_ 2365207294 HVInternalContactor5St22618 22618;
BA_ "SigType" SG_ 2365207294 HVInternalContactor4St22617 4;
BA_ "SPN" SG_ 2365207294 HVInternalContactor4St22617 22617;
BA_ "SigType" SG_ 2365207294 HVInternalContactor3St22616 4;
BA_ "SPN" SG_ 2365207294 HVInternalContactor3St22616 22616;
BA_ "SigType" SG_ 2365207294 HVInternalContactor2St22615 4;
BA_ "SPN" SG_ 2365207294 HVInternalContactor2St22615 22615;
BA_ "SigType" SG_ 2365207294 HVInternalContactor1St22614 4;
BA_ "SPN" SG_ 2365207294 HVInternalContactor1St22614 22614;
BA_ "SigType" SG_ 2365207294 HVInternalContactor8St 4;
BA_ "SPN" SG_ 2365207294 HVInternalContactor8St 22613;
BA_ "SigType" SG_ 2365207294 HVInternalContactor7St 4;
BA_ "SPN" SG_ 2365207294 HVInternalContactor7St 22612;
BA_ "SigType" SG_ 2365207294 HVInternalContactor6St 4;
BA_ "SPN" SG_ 2365207294 HVInternalContactor6St 22611;
BA_ "SigType" SG_ 2365207294 HVInternalContactor5St 4;
BA_ "SPN" SG_ 2365207294 HVInternalContactor5St 22610;
BA_ "SigType" SG_ 2365207294 HVInternalContactor4St 4;
BA_ "SPN" SG_ 2365207294 HVInternalContactor4St 22609;
BA_ "SigType" SG_ 2365207294 HVInternalContactor3St 4;
BA_ "SPN" SG_ 2365207294 HVInternalContactor3St 22608;
BA_ "SigType" SG_ 2365207294 HVInternalContactor2St 4;
BA_ "SPN" SG_ 2365207294 HVInternalContactor2St 22607;
BA_ "SigType" SG_ 2365207294 HVInternalContactor1St 4;
BA_ "SPN" SG_ 2365207294 HVInternalContactor1St 22606;
BA_ "SigType" SG_ 2365207038 HVInternalContactor8St22599 4;
BA_ "SPN" SG_ 2365207038 HVInternalContactor8St22599 22599;
BA_ "SigType" SG_ 2365207038 HVInternalContactor7St22598 4;
BA_ "SPN" SG_ 2365207038 HVInternalContactor7St22598 22598;
BA_ "SigType" SG_ 2365207038 HVInternalContactor6St22597 4;
BA_ "SPN" SG_ 2365207038 HVInternalContactor6St22597 22597;
BA_ "SigType" SG_ 2365207038 HVInternalContactor5St22596 4;
BA_ "SPN" SG_ 2365207038 HVInternalContactor5St22596 22596;
BA_ "SigType" SG_ 2365207038 HVInternalContactor4St22595 4;
BA_ "SPN" SG_ 2365207038 HVInternalContactor4St22595 22595;
BA_ "SigType" SG_ 2365207038 HVInternalContactor3St22594 4;
BA_ "SPN" SG_ 2365207038 HVInternalContactor3St22594 22594;
BA_ "SigType" SG_ 2365207038 HVInternalContactor2St22593 4;
BA_ "SPN" SG_ 2365207038 HVInternalContactor2St22593 22593;
BA_ "SigType" SG_ 2365207038 HVInternalContactor1St22592 4;
BA_ "SPN" SG_ 2365207038 HVInternalContactor1St22592 22592;
BA_ "SigType" SG_ 2365207038 HVInternalContactor8St 4;
BA_ "SPN" SG_ 2365207038 HVInternalContactor8St 22591;
BA_ "SigType" SG_ 2365207038 HVInternalContactor7St 4;
BA_ "SPN" SG_ 2365207038 HVInternalContactor7St 22590;
BA_ "SigType" SG_ 2365207038 HVInternalContactor6St 4;
BA_ "SPN" SG_ 2365207038 HVInternalContactor6St 22589;
BA_ "SigType" SG_ 2365207038 HVInternalContactor5St 4;
BA_ "SPN" SG_ 2365207038 HVInternalContactor5St 22588;
BA_ "SigType" SG_ 2365207038 HVInternalContactor4St 4;
BA_ "SPN" SG_ 2365207038 HVInternalContactor4St 22587;
BA_ "SigType" SG_ 2365207038 HVInternalContactor3St 4;
BA_ "SPN" SG_ 2365207038 HVInternalContactor3St 22586;
BA_ "SigType" SG_ 2365207038 HVInternalContactor2St 4;
BA_ "SPN" SG_ 2365207038 HVInternalContactor2St 22585;
BA_ "SigType" SG_ 2365207038 HVInternalContactor1St 4;
BA_ "SPN" SG_ 2365207038 HVInternalContactor1St 22584;
BA_ "SigType" SG_ 2365206782 HVInternalContactor8St22577 4;
BA_ "SPN" SG_ 2365206782 HVInternalContactor8St22577 22577;
BA_ "SigType" SG_ 2365206782 HVInternalContactor7St22576 4;
BA_ "SPN" SG_ 2365206782 HVInternalContactor7St22576 22576;
BA_ "SigType" SG_ 2365206782 HVInternalContactor6St22575 4;
BA_ "SPN" SG_ 2365206782 HVInternalContactor6St22575 22575;
BA_ "SigType" SG_ 2365206782 HVInternalContactor5St22574 4;
BA_ "SPN" SG_ 2365206782 HVInternalContactor5St22574 22574;
BA_ "SigType" SG_ 2365206782 HVInternalContactor4St22573 4;
BA_ "SPN" SG_ 2365206782 HVInternalContactor4St22573 22573;
BA_ "SigType" SG_ 2365206782 HVInternalContactor3St22572 4;
BA_ "SPN" SG_ 2365206782 HVInternalContactor3St22572 22572;
BA_ "SigType" SG_ 2365206782 HVInternalContactor2St22571 4;
BA_ "SPN" SG_ 2365206782 HVInternalContactor2St22571 22571;
BA_ "SigType" SG_ 2365206782 HVInternalContactor1St22570 4;
BA_ "SPN" SG_ 2365206782 HVInternalContactor1St22570 22570;
BA_ "SigType" SG_ 2365206782 HVInternalContactor8St 4;
BA_ "SPN" SG_ 2365206782 HVInternalContactor8St 22569;
BA_ "SigType" SG_ 2365206782 HVInternalContactor7St 4;
BA_ "SPN" SG_ 2365206782 HVInternalContactor7St 22568;
BA_ "SigType" SG_ 2365206782 HVInternalContactor6St 4;
BA_ "SPN" SG_ 2365206782 HVInternalContactor6St 22567;
BA_ "SigType" SG_ 2365206782 HVInternalContactor5St 4;
BA_ "SPN" SG_ 2365206782 HVInternalContactor5St 22566;
BA_ "SigType" SG_ 2365206782 HVInternalContactor4St 4;
BA_ "SPN" SG_ 2365206782 HVInternalContactor4St 22565;
BA_ "SigType" SG_ 2365206782 HVInternalContactor3St 4;
BA_ "SPN" SG_ 2365206782 HVInternalContactor3St 22564;
BA_ "SigType" SG_ 2365206782 HVInternalContactor2St 4;
BA_ "SPN" SG_ 2365206782 HVInternalContactor2St 22563;
BA_ "SigType" SG_ 2365206782 HVInternalContactor1St 4;
BA_ "SPN" SG_ 2365206782 HVInternalContactor1St 22562;
BA_ "SigType" SG_ 2365206526 HVInternalContactor8St22555 4;
BA_ "SPN" SG_ 2365206526 HVInternalContactor8St22555 22555;
BA_ "SigType" SG_ 2365206526 HVInternalContactor7St22554 4;
BA_ "SPN" SG_ 2365206526 HVInternalContactor7St22554 22554;
BA_ "SigType" SG_ 2365206526 HVInternalContactor6St22553 4;
BA_ "SPN" SG_ 2365206526 HVInternalContactor6St22553 22553;
BA_ "SigType" SG_ 2365206526 HVInternalContactor5St22552 4;
BA_ "SPN" SG_ 2365206526 HVInternalContactor5St22552 22552;
BA_ "SigType" SG_ 2365206526 HVInternalContactor4St22551 4;
BA_ "SPN" SG_ 2365206526 HVInternalContactor4St22551 22551;
BA_ "SigType" SG_ 2365206526 HVInternalContactor3St22550 4;
BA_ "SPN" SG_ 2365206526 HVInternalContactor3St22550 22550;
BA_ "SigType" SG_ 2365206526 HVInternalContactor2St22549 4;
BA_ "SPN" SG_ 2365206526 HVInternalContactor2St22549 22549;
BA_ "SigType" SG_ 2365206526 HVInternalContactor1St22548 4;
BA_ "SPN" SG_ 2365206526 HVInternalContactor1St22548 22548;
BA_ "SigType" SG_ 2365206526 HVInternalContactor8St 4;
BA_ "SPN" SG_ 2365206526 HVInternalContactor8St 22547;
BA_ "SigType" SG_ 2365206526 HVInternalContactor7St 4;
BA_ "SPN" SG_ 2365206526 HVInternalContactor7St 22546;
BA_ "SigType" SG_ 2365206526 HVInternalContactor6St 4;
BA_ "SPN" SG_ 2365206526 HVInternalContactor6St 22545;
BA_ "SigType" SG_ 2365206526 HVInternalContactor5St 4;
BA_ "SPN" SG_ 2365206526 HVInternalContactor5St 22544;
BA_ "SigType" SG_ 2365206526 HVInternalContactor4St 4;
BA_ "SPN" SG_ 2365206526 HVInternalContactor4St 22543;
BA_ "SigType" SG_ 2365206526 HVInternalContactor3St 4;
BA_ "SPN" SG_ 2365206526 HVInternalContactor3St 22542;
BA_ "SigType" SG_ 2365206526 HVInternalContactor2St 4;
BA_ "SPN" SG_ 2365206526 HVInternalContactor2St 22541;
BA_ "SigType" SG_ 2365206526 HVInternalContactor1St 4;
BA_ "SPN" SG_ 2365206526 HVInternalContactor1St 22540;
BA_ "SigType" SG_ 2365206270 HVInternalContactor8St22533 4;
BA_ "SPN" SG_ 2365206270 HVInternalContactor8St22533 22533;
BA_ "SigType" SG_ 2365206270 HVInternalContactor7St22532 4;
BA_ "SPN" SG_ 2365206270 HVInternalContactor7St22532 22532;
BA_ "SigType" SG_ 2365206270 HVInternalContactor6St22531 4;
BA_ "SPN" SG_ 2365206270 HVInternalContactor6St22531 22531;
BA_ "SigType" SG_ 2365206270 HVInternalContactor5St22530 4;
BA_ "SPN" SG_ 2365206270 HVInternalContactor5St22530 22530;
BA_ "SigType" SG_ 2365206270 HVInternalContactor4St22529 4;
BA_ "SPN" SG_ 2365206270 HVInternalContactor4St22529 22529;
BA_ "SigType" SG_ 2365206270 HVInternalContactor3St22528 4;
BA_ "SPN" SG_ 2365206270 HVInternalContactor3St22528 22528;
BA_ "SigType" SG_ 2365206270 HVInternalContactor2St22527 4;
BA_ "SPN" SG_ 2365206270 HVInternalContactor2St22527 22527;
BA_ "SigType" SG_ 2365206270 HVInternalContactor1St22526 4;
BA_ "SPN" SG_ 2365206270 HVInternalContactor1St22526 22526;
BA_ "SigType" SG_ 2365206270 HVInternalContactor8St 4;
BA_ "SPN" SG_ 2365206270 HVInternalContactor8St 22525;
BA_ "SigType" SG_ 2365206270 HVInternalContactor7St 4;
BA_ "SPN" SG_ 2365206270 HVInternalContactor7St 22524;
BA_ "SigType" SG_ 2365206270 HVInternalContactor6St 4;
BA_ "SPN" SG_ 2365206270 HVInternalContactor6St 22523;
BA_ "SigType" SG_ 2365206270 HVInternalContactor5St 4;
BA_ "SPN" SG_ 2365206270 HVInternalContactor5St 22522;
BA_ "SigType" SG_ 2365206270 HVInternalContactor4St 4;
BA_ "SPN" SG_ 2365206270 HVInternalContactor4St 22521;
BA_ "SigType" SG_ 2365206270 HVInternalContactor3St 4;
BA_ "SPN" SG_ 2365206270 HVInternalContactor3St 22520;
BA_ "SigType" SG_ 2365206270 HVInternalContactor2St 4;
BA_ "SPN" SG_ 2365206270 HVInternalContactor2St 22519;
BA_ "SigType" SG_ 2365206270 HVInternalContactor1St 4;
BA_ "SPN" SG_ 2365206270 HVInternalContactor1St 22518;
BA_ "SigType" SG_ 2365206014 HVInternalContactor8St22511 4;
BA_ "SPN" SG_ 2365206014 HVInternalContactor8St22511 22511;
BA_ "SigType" SG_ 2365206014 HVInternalContactor7St22510 4;
BA_ "SPN" SG_ 2365206014 HVInternalContactor7St22510 22510;
BA_ "SigType" SG_ 2365206014 HVInternalContactor6St22509 4;
BA_ "SPN" SG_ 2365206014 HVInternalContactor6St22509 22509;
BA_ "SigType" SG_ 2365206014 HVInternalContactor5St22508 4;
BA_ "SPN" SG_ 2365206014 HVInternalContactor5St22508 22508;
BA_ "SigType" SG_ 2365206014 HVInternalContactor4St22507 4;
BA_ "SPN" SG_ 2365206014 HVInternalContactor4St22507 22507;
BA_ "SigType" SG_ 2365206014 HVInternalContactor3St22506 4;
BA_ "SPN" SG_ 2365206014 HVInternalContactor3St22506 22506;
BA_ "SigType" SG_ 2365206014 HVInternalContactor2St22505 4;
BA_ "SPN" SG_ 2365206014 HVInternalContactor2St22505 22505;
BA_ "SigType" SG_ 2365206014 HVInternalContactor1St22504 4;
BA_ "SPN" SG_ 2365206014 HVInternalContactor1St22504 22504;
BA_ "SigType" SG_ 2365206014 HVInternalContactor8St 4;
BA_ "SPN" SG_ 2365206014 HVInternalContactor8St 22503;
BA_ "SigType" SG_ 2365206014 HVInternalContactor7St 4;
BA_ "SPN" SG_ 2365206014 HVInternalContactor7St 22502;
BA_ "SigType" SG_ 2365206014 HVInternalContactor6St 4;
BA_ "SPN" SG_ 2365206014 HVInternalContactor6St 22501;
BA_ "SigType" SG_ 2365206014 HVInternalContactor5St 4;
BA_ "SPN" SG_ 2365206014 HVInternalContactor5St 22500;
BA_ "SigType" SG_ 2365206014 HVInternalContactor4St 4;
BA_ "SPN" SG_ 2365206014 HVInternalContactor4St 22499;
BA_ "SigType" SG_ 2365206014 HVInternalContactor3St 4;
BA_ "SPN" SG_ 2365206014 HVInternalContactor3St 22498;
BA_ "SigType" SG_ 2365206014 HVInternalContactor2St 4;
BA_ "SPN" SG_ 2365206014 HVInternalContactor2St 22497;
BA_ "SigType" SG_ 2365206014 HVInternalContactor1St 4;
BA_ "SPN" SG_ 2365206014 HVInternalContactor1St 22496;
VAL_ 3221225472 TirePressThresholdDetection 7 "Not available" 6 "Error indicator" 5 "Not defined" 4 "Extreme under pressure" 3 "Under pressure" 2 "No warning pressure" 1 "Over pressure" 0 "Extreme over pressure" ;
VAL_ 3221225472 CTIWheelEndElectricalFault 3 "Not Supported" 2 "Error" 1 "Not Defined" 0 "Ok  No Fault" ;
VAL_ 3221225472 CTITireStatus 3 "Not Supported" 2 "Error" 1 "Tire leak detected" 0 "Ok no fault" ;
VAL_ 3221225472 CTIWheelSensorStatus 3 "Not Supported" 2 "Not Defined" 1 "On tire is polled" 0 "Off / isolated from CTI Pressure Controller" ;
VAL_ 3221225472 EngTurningGearEngaged 1 "Engaged" 0 "Not engaged" 3 "Not available" 2 "Error" ;
VAL_ 2566662398 CurRoadwayVSLmtMode 15 "Not Available" 14 "Reserved" 13 "Reserved" 12 "Reserved" 11 "Reserved" 10 "Reserved" 9 "Reserved" 8 "Reserved" 7 "Reserved" 6 "Reserved" 5 "Reserved" 4 "Reserved" 3 "Operator Override" 2 "Active" 1 "Inactive" 0 "Disabled" ;
VAL_ 2365334014 Module96OperationalSt 3 "Not Available" 2 "Error" 1 "Operational" 0 "Not Operational" ;
VAL_ 2365334014 Module95OperationalSt 3 "Not Available" 2 "Error" 1 "Operational" 0 "Not Operational" ;
VAL_ 2365334014 Module94OperationalSt 3 "Not Available" 2 "Error" 1 "Operational" 0 "Not Operational" ;
VAL_ 2365334014 Module93OperationalSt 3 "Not Available" 2 "Error" 1 "Operational" 0 "Not Operational" ;
VAL_ 2365334014 Module92OperationalSt 3 "Not Available" 2 "Error" 1 "Operational" 0 "Not Operational" ;
VAL_ 2365334014 Module91OperationalSt 3 "Not Available" 2 "Error" 1 "Operational" 0 "Not Operational" ;
VAL_ 2365334014 Module90OperationalSt 3 "Not Available" 2 "Error" 1 "Operational" 0 "Not Operational" ;
VAL_ 2365334014 Module89OperationalSt 3 "Not Available" 2 "Error" 1 "Operational" 0 "Not Operational" ;
VAL_ 2365334014 Module88OperationalSt 3 "Not Available" 2 "Error" 1 "Operational" 0 "Not Operational" ;
VAL_ 2365334014 Module87OperationalSt 3 "Not Available" 2 "Error" 1 "Operational" 0 "Not Operational" ;
VAL_ 2365334014 Module86OperationalSt 3 "Not Available" 2 "Error" 1 "Operational" 0 "Not Operational" ;
VAL_ 2365334014 Module85OperationalSt 3 "Not Available" 2 "Error" 1 "Operational" 0 "Not Operational" ;
VAL_ 2365334014 Module84OperationalSt 3 "Not Available" 2 "Error" 1 "Operational" 0 "Not Operational" ;
VAL_ 2365334014 Module83OperationalSt 3 "Not Available" 2 "Error" 1 "Operational" 0 "Not Operational" ;
VAL_ 2365334014 Module82OperationalSt 3 "Not Available" 2 "Error" 1 "Operational" 0 "Not Operational" ;
VAL_ 2365334014 Module81OperationalSt 3 "Not Available" 2 "Error" 1 "Operational" 0 "Not Operational" ;
VAL_ 2365334014 Module80OperationalSt 3 "Not Available" 2 "Error" 1 "Operational" 0 "Not Operational" ;
VAL_ 2365334014 Module79OperationalSt 3 "Not Available" 2 "Error" 1 "Operational" 0 "Not Operational" ;
VAL_ 2365334014 Module78OperationalSt 3 "Not Available" 2 "Error" 1 "Operational" 0 "Not Operational" ;
VAL_ 2365334014 Module77OperationalSt 3 "Not Available" 2 "Error" 1 "Operational" 0 "Not Operational" ;
VAL_ 2365334014 Module76OperationalSt 3 "Not Available" 2 "Error" 1 "Operational" 0 "Not Operational" ;
VAL_ 2365334014 Module75OperationalSt 3 "Not Available" 2 "Error" 1 "Operational" 0 "Not Operational" ;
VAL_ 2365334014 Module74OperationalSt 3 "Not Available" 2 "Error" 1 "Operational" 0 "Not Operational" ;
VAL_ 2365334014 Module73OperationalSt 3 "Not Available" 2 "Error" 1 "Operational" 0 "Not Operational" ;
VAL_ 2365334014 Module72OperationalSt 3 "Not Available" 2 "Error" 1 "Operational" 0 "Not Operational" ;
VAL_ 2365334014 Module71OperationalSt 3 "Not Available" 2 "Error" 1 "Operational" 0 "Not Operational" ;
VAL_ 2365334014 Module70OperationalSt 3 "Not Available" 2 "Error" 1 "Operational" 0 "Not Operational" ;
VAL_ 2365334014 Module69OperationalSt 3 "Not Available" 2 "Error" 1 "Operational" 0 "Not Operational" ;
VAL_ 2365334014 Module68OperationalSt 3 "Not Available" 2 "Error" 1 "Operational" 0 "Not Operational" ;
VAL_ 2365334014 Module67OperationalSt 3 "Not Available" 2 "Error" 1 "Operational" 0 "Not Operational" ;
VAL_ 2365334014 Module66OperationalSt 3 "Not Available" 2 "Error" 1 "Operational" 0 "Not Operational" ;
VAL_ 2365334014 Module65OperationalSt 3 "Not Available" 2 "Error" 1 "Operational" 0 "Not Operational" ;
VAL_ 2365333758 Module64OperationalSt 3 "Not Available" 2 "Error" 1 "Operational" 0 "Not Operational" ;
VAL_ 2365333758 Module63OperationalSt 3 "Not Available" 2 "Error" 1 "Operational" 0 "Not Operational" ;
VAL_ 2365333758 Module62OperationalSt 3 "Not Available" 2 "Error" 1 "Operational" 0 "Not Operational" ;
VAL_ 2365333758 Module61OperationalSt 3 "Not Available" 2 "Error" 1 "Operational" 0 "Not Operational" ;
VAL_ 2365333758 Module60OperationalSt 3 "Not Available" 2 "Error" 1 "Operational" 0 "Not Operational" ;
VAL_ 2365333758 Module59OperationalSt 3 "Not Available" 2 "Error" 1 "Operational" 0 "Not Operational" ;
VAL_ 2365333758 Module58OperationalSt 3 "Not Available" 2 "Error" 1 "Operational" 0 "Not Operational" ;
VAL_ 2365333758 Module57OperationalSt 3 "Not Available" 2 "Error" 1 "Operational" 0 "Not Operational" ;
VAL_ 2365333758 Module56OperationalSt 3 "Not Available" 2 "Error" 1 "Operational" 0 "Not Operational" ;
VAL_ 2365333758 Module55OperationalSt 3 "Not Available" 2 "Error" 1 "Operational" 0 "Not Operational" ;
VAL_ 2365333758 Module54OperationalSt 3 "Not Available" 2 "Error" 1 "Operational" 0 "Not Operational" ;
VAL_ 2365333758 Module53OperationalSt 3 "Not Available" 2 "Error" 1 "Operational" 0 "Not Operational" ;
VAL_ 2365333758 Module52OperationalSt 3 "Not Available" 2 "Error" 1 "Operational" 0 "Not Operational" ;
VAL_ 2365333758 Module51OperationalSt 3 "Not Available" 2 "Error" 1 "Operational" 0 "Not Operational" ;
VAL_ 2365333758 Module50OperationalSt 3 "Not Available" 2 "Error" 1 "Operational" 0 "Not Operational" ;
VAL_ 2365333758 Module49OperationalSt 3 "Not Available" 2 "Error" 1 "Operational" 0 "Not Operational" ;
VAL_ 2365333758 Module48OperationalSt 3 "Not Available" 2 "Error" 1 "Operational" 0 "Not Operational" ;
VAL_ 2365333758 Module47OperationalSt 3 "Not Available" 2 "Error" 1 "Operational" 0 "Not Operational" ;
VAL_ 2365333758 Module46OperationalSt 3 "Not Available" 2 "Error" 1 "Operational" 0 "Not Operational" ;
VAL_ 2365333758 Module45OperationalSt 3 "Not Available" 2 "Error" 1 "Operational" 0 "Not Operational" ;
VAL_ 2365333758 Module44OperationalSt 3 "Not Available" 2 "Error" 1 "Operational" 0 "Not Operational" ;
VAL_ 2365333758 Module43OperationalSt 3 "Not Available" 2 "Error" 1 "Operational" 0 "Not Operational" ;
VAL_ 2365333758 Module42OperationalSt 3 "Not Available" 2 "Error" 1 "Operational" 0 "Not Operational" ;
VAL_ 2365333758 Module41OperationalSt 3 "Not Available" 2 "Error" 1 "Operational" 0 "Not Operational" ;
VAL_ 2365333758 Module40OperationalSt 3 "Not Available" 2 "Error" 1 "Operational" 0 "Not Operational" ;
VAL_ 2365333758 Module39OperationalSt 3 "Not Available" 2 "Error" 1 "Operational" 0 "Not Operational" ;
VAL_ 2365333758 Module38OperationalSt 3 "Not Available" 2 "Error" 1 "Operational" 0 "Not Operational" ;
VAL_ 2365333758 Module37OperationalSt 3 "Not Available" 2 "Error" 1 "Operational" 0 "Not Operational" ;
VAL_ 2365333758 Module36OperationalSt 3 "Not Available" 2 "Error" 1 "Operational" 0 "Not Operational" ;
VAL_ 2365333758 Module35OperationalSt 3 "Not Available" 2 "Error" 1 "Operational" 0 "Not Operational" ;
VAL_ 2365333758 Module34OperationalSt 3 "Not Available" 2 "Error" 1 "Operational" 0 "Not Operational" ;
VAL_ 2365333758 Module33OperationalSt 3 "Not Available" 2 "Error" 1 "Operational" 0 "Not Operational" ;
VAL_ 2633768446 TransportationCompartmentDoorSt 3 "Not available" 2 "Error" 1 "Door closed" 0 "Door open" ;
VAL_ 2566535934 ErrorIndEPTO1 3 "Not available" 2 "Reserved" 1 "ePTO error detected" 0 "no ePTO error detected or ePTO not enabled" ;
VAL_ 2566535934 SysReadinessEPTO1 3 "Not available" 2 "Reserved" 1 "ePTO available" 0 "ePTO not available due to system error" ;
VAL_ 2566535934 EmergDeEnergizeSwEPTO1 3 "Not available" 2 "Error" 1 "Emergency De-energize active" 0 "Emergency De-energize not active" ;
VAL_ 2566535934 EngagementStEPTO1 3 "Not available" 2 "Error" 1 "Drive is activated or 'engaged'" 0 "Drive not activated or 'engaged'" ;
VAL_ 2566535934 EngagementConsentEPTO1 3 "Not available" 2 "Error" 1 "Consent given" 0 "Consent not given" ;
VAL_ 2566535934 EnableSwEPTO1 3 "Not available" 2 "Error" 1 "Enable switch on" 0 "Enable switch off" ;
VAL_ 2566535678 OutPressProtLvlActiveSt 15 "Not Available" 14 "Error" 13 "Initial Ramp Gain Outlet Pressure Active" 12 "Reserved" 11 "Reserved" 10 "Reserved" 9 "Reserved" 8 "Reserved" 7 "Reserved" 6 "Outlet Pressure Protection Level 5 Active" 5 "Outlet Pressure Protection Level 4 Active" 4 "Outlet Pressure Protection Level 3 Active" 3 "Outlet Pressure Protection Level 2 Active" 2 "Outlet Pressure Protection Level 1 Active" 1 "Outlet Pressure Protection Waiting" 0 "Not in use" ;
VAL_ 2566535422 SysCtrlEnableSt 3 "Not Available" 2 "Reserved" 1 "Enabled" 0 "Disabled" ;
VAL_ 2566535422 OutPressDiffFromAvg 3 "Not Available" 2 "Reserved" 1 "Outlet Pressure Discrepancy Detected" 0 "No Outlet Pressure Discrepancy Detected" ;
VAL_ 2566535166 TSC1EngCtrlAbortCmd 3 "Don't Care / Take No Action" 2 "Reserved" 1 "Abort requested" 0 "Abort Not Requested" ;
VAL_ 2566535166 PumpDriveType 3 "Not Supported" 2 "Electrical Drive" 1 "Mechincal Drive" 0 "Not Configured" ;
VAL_ 2566535166 LFCtrlHoldSt 3 "Not Available" 2 "Error" 1 "Active" 0 "Inactive" ;
VAL_ 2566535166 LFCtrlDesSpdInputConfig 3 "Not Available" 2 "Error" 1 "SAE J1939" 0 "Hardwired" ;
VAL_ 2566535166 LFCtrlInputConfig 3 "Not Available" 2 "Error" 1 "SAE J1939" 0 "Hardwired" ;
VAL_ 2566535166 LFCtrlInstallation 3 "Not Available" 2 "Error" 1 "Installed" 0 "Not Installed" ;
VAL_ 2499425790 Overheight_OverwidthSt 3 "Not Available" 2 "Error" 1 "overheight/overwidth condition detected" 0 "no overheight/overwidth condition detected" ;
VAL_ 2499425790 TailgatePos 3 "Not Available" 2 "Error" 1 "tailgate is closed" 0 "tailgate is not closed" ;
VAL_ 2499425790 FrontLoaderForkPos 3 "Not Available" 2 "Error" 1 "forks are tucked" 0 "forks are not tucked" ;
VAL_ 2499425790 FrontLoaderArmPos 15 "Not Available" 14 "Error" 13 "reserved" 12 "reserved" 11 "reserved" 10 "reserved" 9 "reserved" 8 "reserved" 7 "reserved" 6 "reserved" 5 "reserved" 4 "reserved" 3 "reserved" 2 "reserved" 1 "arms are above cab" 0 "arms are lowered" ;
VAL_ 2499425790 TransitSt 3 "Not Available" 2 "Error" 1 "All equipment is ready for transit" 0 "Some equipment is not in transit position" ;
VAL_ 2365207806 GeneralFault 15 "Not Available" 14 "Reserved" 13 "Reserved" 12 "Reserved" 11 "Reserved" 10 "Reserved" 9 "Reserved" 8 "Reserved" 7 "Reserved" 6 "Reserved" 5 "Reserved" 4 "Reserved" 3 "Reserved" 2 "Command message not received" 1 "Out of Sync with other lamps" 0 "No Fault" ;
VAL_ 2365207806 Color14St 15 "Not Available" 14 "Reserved" 13 "Reserved" 12 "Reserved" 11 "Reserved" 10 "Reserved" 9 "Reserved" 8 "Reserved" 7 "Reserved" 6 "Reserved" 5 "LED chipset failure" 4 "High Brightness" 3 "Low Brightness" 2 "Color Off fault" 1 "Color On Fault" 0 "No Fault" ;
VAL_ 2365207806 Color13St 15 "Not Available" 14 "Reserved" 13 "Reserved" 12 "Reserved" 11 "Reserved" 10 "Reserved" 9 "Reserved" 8 "Reserved" 7 "Reserved" 6 "Reserved" 5 "LED chipset failure" 4 "High Brightness" 3 "Low Brightness" 2 "Color Off fault" 1 "Color On Fault" 0 "No Fault" ;
VAL_ 2365207806 Color12St 15 "Not Available" 14 "Reserved" 13 "Reserved" 12 "Reserved" 11 "Reserved" 10 "Reserved" 9 "Reserved" 8 "Reserved" 7 "Reserved" 6 "Reserved" 5 "LED chipset failure" 4 "High Brightness" 3 "Low Brightness" 2 "Color Off fault" 1 "Color On Fault" 0 "No Fault" ;
VAL_ 2365207806 Color11St 15 "Not Available" 14 "Reserved" 13 "Reserved" 12 "Reserved" 11 "Reserved" 10 "Reserved" 9 "Reserved" 8 "Reserved" 7 "Reserved" 6 "Reserved" 5 "LED chipset failure" 4 "High Brightness" 3 "Low Brightness" 2 "Color Off fault" 1 "Color On Fault" 0 "No Fault" ;
VAL_ 2365207806 Color10St 15 "Not Available" 14 "Reserved" 13 "Reserved" 12 "Reserved" 11 "Reserved" 10 "Reserved" 9 "Reserved" 8 "Reserved" 7 "Reserved" 6 "Reserved" 5 "LED chipset failure" 4 "High Brightness" 3 "Low Brightness" 2 "Color Off fault" 1 "Color On Fault" 0 "No Fault" ;
VAL_ 2365207806 Color9St 15 "Not Available" 14 "Reserved" 13 "Reserved" 12 "Reserved" 11 "Reserved" 10 "Reserved" 9 "Reserved" 8 "Reserved" 7 "Reserved" 6 "Reserved" 5 "LED chipset failure" 4 "High Brightness" 3 "Low Brightness" 2 "Color Off fault" 1 "Color On Fault" 0 "No Fault" ;
VAL_ 2365207806 Color8St 15 "Not Available" 14 "Reserved" 13 "Reserved" 12 "Reserved" 11 "Reserved" 10 "Reserved" 9 "Reserved" 8 "Reserved" 7 "Reserved" 6 "Reserved" 5 "LED chipset failure" 4 "High Brightness" 3 "Low Brightness" 2 "Color Off fault" 1 "Color On Fault" 0 "No Fault" ;
VAL_ 2365207806 Color7St 15 "Not Available" 14 "Reserved" 13 "Reserved" 12 "Reserved" 11 "Reserved" 10 "Reserved" 9 "Reserved" 8 "Reserved" 7 "Reserved" 6 "Reserved" 5 "LED chipset failure" 4 "High Brightness" 3 "Low Brightness" 2 "Color Off fault" 1 "Color On Fault" 0 "No Fault" ;
VAL_ 2365207806 Color6St 15 "Not Available" 14 "Reserved" 13 "Reserved" 12 "Reserved" 11 "Reserved" 10 "Reserved" 9 "Reserved" 8 "Reserved" 7 "Reserved" 6 "Reserved" 5 "LED chipset failure" 4 "High Brightness" 3 "Low Brightness" 2 "Color Off fault" 1 "Color On Fault" 0 "No Fault" ;
VAL_ 2365207806 Color5St 15 "Not Available" 14 "Reserved" 13 "Reserved" 12 "Reserved" 11 "Reserved" 10 "Reserved" 9 "Reserved" 8 "Reserved" 7 "Reserved" 6 "Reserved" 5 "LED chipset failure" 4 "High Brightness" 3 "Low Brightness" 2 "Color Off fault" 1 "Color On Fault" 0 "No Fault" ;
VAL_ 2365207806 Color4St 15 "Not Available" 14 "Reserved" 13 "Reserved" 12 "Reserved" 11 "Reserved" 10 "Reserved" 9 "Reserved" 8 "Reserved" 7 "Reserved" 6 "Reserved" 5 "LED chipset failure" 4 "High Brightness" 3 "Low Brightness" 2 "Color Off fault" 1 "Color On Fault" 0 "No Fault" ;
VAL_ 2365207806 Color3St 15 "Not Available" 14 "Reserved" 13 "Reserved" 12 "Reserved" 11 "Reserved" 10 "Reserved" 9 "Reserved" 8 "Reserved" 7 "Reserved" 6 "Reserved" 5 "LED chipset failure" 4 "High Brightness" 3 "Low Brightness" 2 "Color Off fault" 1 "Color On Fault" 0 "No Fault" ;
VAL_ 2365207806 Color2St 15 "Not Available" 14 "Reserved" 13 "Reserved" 12 "Reserved" 11 "Reserved" 10 "Reserved" 9 "Reserved" 8 "Reserved" 7 "Reserved" 6 "Reserved" 5 "LED chipset failure" 4 "High Brightness" 3 "Low Brightness" 2 "Color Off fault" 1 "Color On Fault" 0 "No Fault" ;
VAL_ 2365207806 Color1St 15 "Not Available" 14 "Reserved" 13 "Reserved" 12 "Reserved" 11 "Reserved" 10 "Reserved" 9 "Reserved" 8 "Reserved" 7 "Reserved" 6 "Reserved" 5 "LED chipset failure" 4 "High Brightness" 3 "Low Brightness" 2 "Color Off fault" 1 "Color On Fault" 0 "No Fault" ;
VAL_ 2365207550 Freq 15 "Not Available" 14 "Reserved" 13 "Reserved" 12 "Reserved" 11 "Reserved" 10 "Reserved" 9 "Reserved" 8 "Reserved" 7 "Reserved" 6 "Reserved" 5 "Reserved" 4 "Reserved" 3 "Reserved" 2 "2 Hz" 1 "1 Hz" 0 "0.5 Hz" ;
VAL_ 2365207550 Synch 3 "Not Available" 2 "Reserved" 1 "Requested" 0 "Not Requested" ;
VAL_ 2365207550 TimeSlot10 15 "Not Available" 14 "Color 14" 13 "Color 13" 12 "Color 12" 11 "Color 11" 10 "Color 10" 9 "Color 9" 8 "Color 8" 7 "Color 7" 6 "Color 6" 5 "Color 5" 4 "Color 4" 3 "Color 3" 2 "Color 2" 1 "Color 1" 0 "Off" ;
VAL_ 2365207550 TimeSlot9 15 "Not Available" 14 "Color 14" 13 "Color 13" 12 "Color 12" 11 "Color 11" 10 "Color 10" 9 "Color 9" 8 "Color 8" 7 "Color 7" 6 "Color 6" 5 "Color 5" 4 "Color 4" 3 "Color 3" 2 "Color 2" 1 "Color 1" 0 "Off" ;
VAL_ 2365207550 TimeSlot8 15 "Not Available" 14 "Color 14" 13 "Color 13" 12 "Color 12" 11 "Color 11" 10 "Color 10" 9 "Color 9" 8 "Color 8" 7 "Color 7" 6 "Color 6" 5 "Color 5" 4 "Color 4" 3 "Color 3" 2 "Color 2" 1 "Color 1" 0 "Off" ;
VAL_ 2365207550 TimeSlot7 15 "Not Available" 14 "Color 14" 13 "Color 13" 12 "Color 12" 11 "Color 11" 10 "Color 10" 9 "Color 9" 8 "Color 8" 7 "Color 7" 6 "Color 6" 5 "Color 5" 4 "Color 4" 3 "Color 3" 2 "Color 2" 1 "Color 1" 0 "Off" ;
VAL_ 2365207550 TimeSlot6 15 "Not Available" 14 "Color 14" 13 "Color 13" 12 "Color 12" 11 "Color 11" 10 "Color 10" 9 "Color 9" 8 "Color 8" 7 "Color 7" 6 "Color 6" 5 "Color 5" 4 "Color 4" 3 "Color 3" 2 "Color 2" 1 "Color 1" 0 "Off" ;
VAL_ 2365207550 TimeSlot5 15 "Not Available" 14 "Color 14" 13 "Color 13" 12 "Color 12" 11 "Color 11" 10 "Color 10" 9 "Color 9" 8 "Color 8" 7 "Color 7" 6 "Color 6" 5 "Color 5" 4 "Color 4" 3 "Color 3" 2 "Color 2" 1 "Color 1" 0 "Off" ;
VAL_ 2365207550 TimeSlot4 15 "Not Available" 14 "Color 14" 13 "Color 13" 12 "Color 12" 11 "Color 11" 10 "Color 10" 9 "Color 9" 8 "Color 8" 7 "Color 7" 6 "Color 6" 5 "Color 5" 4 "Color 4" 3 "Color 3" 2 "Color 2" 1 "Color 1" 0 "Off" ;
VAL_ 2365207550 TimeSlot3 15 "Not Available" 14 "Color 14" 13 "Color 13" 12 "Color 12" 11 "Color 11" 10 "Color 10" 9 "Color 9" 8 "Color 8" 7 "Color 7" 6 "Color 6" 5 "Color 5" 4 "Color 4" 3 "Color 3" 2 "Color 2" 1 "Color 1" 0 "Off" ;
VAL_ 2365207550 TimeSlot2 15 "Not Available" 14 "Color 14" 13 "Color 13" 12 "Color 12" 11 "Color 11" 10 "Color 10" 9 "Color 9" 8 "Color 8" 7 "Color 7" 6 "Color 6" 5 "Color 5" 4 "Color 4" 3 "Color 3" 2 "Color 2" 1 "Color 1" 0 "Off" ;
VAL_ 2365207550 TimeSlot1 15 "Not Available" 14 "Color 14" 13 "Color 13" 12 "Color 12" 11 "Color 11" 10 "Color 10" 9 "Color 9" 8 "Color 8" 7 "Color 7" 6 "Color 6" 5 "Color 5" 4 "Color 4" 3 "Color 3" 2 "Color 2" 1 "Color 1" 0 "Off" ;
VAL_ 2365207294 HVInternalContactor8St22621 3 "Not Available" 2 "Error" 1 "Contactor Closed" 0 "Contactor Open" ;
VAL_ 2365207294 HVInternalContactor7St22620 3 "Not Available" 2 "Error" 1 "Contactor Closed" 0 "Contactor Open" ;
VAL_ 2365207294 HVInternalContactor6St22619 3 "Not Available" 2 "Error" 1 "Contactor Closed" 0 "Contactor Open" ;
VAL_ 2365207294 HVInternalContactor5St22618 3 "Not Available" 2 "Error" 1 "Contactor Closed" 0 "Contactor Open" ;
VAL_ 2365207294 HVInternalContactor4St22617 3 "Not Available" 2 "Error" 1 "Contactor Closed" 0 "Contactor Open" ;
VAL_ 2365207294 HVInternalContactor3St22616 3 "Not Available" 2 "Error" 1 "Contactor Closed" 0 "Contactor Open" ;
VAL_ 2365207294 HVInternalContactor2St22615 3 "Not Available" 2 "Error" 1 "Contactor Closed" 0 "Contactor Open" ;
VAL_ 2365207294 HVInternalContactor1St22614 3 "Not Available" 2 "Error" 1 "Contactor Closed" 0 "Contactor Open" ;
VAL_ 2365207294 HVInternalContactor8St 3 "Not Available" 2 "Error" 1 "Contactor Closed" 0 "Contactor Open" ;
VAL_ 2365207294 HVInternalContactor7St 3 "Not Available" 2 "Error" 1 "Contactor Closed" 0 "Contactor Open" ;
VAL_ 2365207294 HVInternalContactor6St 3 "Not Available" 2 "Error" 1 "Contactor Closed" 0 "Contactor Open" ;
VAL_ 2365207294 HVInternalContactor5St 3 "Not Available" 2 "Error" 1 "Contactor Closed" 0 "Contactor Open" ;
VAL_ 2365207294 HVInternalContactor4St 3 "Not Available" 2 "Error" 1 "Contactor Closed" 0 "Contactor Open" ;
VAL_ 2365207294 HVInternalContactor3St 3 "Not Available" 2 "Error" 1 "Contactor Closed" 0 "Contactor Open" ;
VAL_ 2365207294 HVInternalContactor2St 3 "Not Available" 2 "Error" 1 "Contactor Closed" 0 "Contactor Open" ;
VAL_ 2365207294 HVInternalContactor1St 3 "Not Available" 2 "Error" 1 "Contactor Closed" 0 "Contactor Open" ;
VAL_ 2365207038 HVInternalContactor8St22599 3 "Not Available" 2 "Error" 1 "Contactor Closed" 0 "Contactor Open" ;
VAL_ 2365207038 HVInternalContactor7St22598 3 "Not Available" 2 "Error" 1 "Contactor Closed" 0 "Contactor Open" ;
VAL_ 2365207038 HVInternalContactor6St22597 3 "Not Available" 2 "Error" 1 "Contactor Closed" 0 "Contactor Open" ;
VAL_ 2365207038 HVInternalContactor5St22596 3 "Not Available" 2 "Error" 1 "Contactor Closed" 0 "Contactor Open" ;
VAL_ 2365207038 HVInternalContactor4St22595 3 "Not Available" 2 "Error" 1 "Contactor Closed" 0 "Contactor Open" ;
VAL_ 2365207038 HVInternalContactor3St22594 3 "Not Available" 2 "Error" 1 "Contactor Closed" 0 "Contactor Open" ;
VAL_ 2365207038 HVInternalContactor2St22593 3 "Not Available" 2 "Error" 1 "Contactor Closed" 0 "Contactor Open" ;
VAL_ 2365207038 HVInternalContactor1St22592 3 "Not Available" 2 "Error" 1 "Contactor Closed" 0 "Contactor Open" ;
VAL_ 2365207038 HVInternalContactor8St 3 "Not Available" 2 "Error" 1 "Contactor Closed" 0 "Contactor Open" ;
VAL_ 2365207038 HVInternalContactor7St 3 "Not Available" 2 "Error" 1 "Contactor Closed" 0 "Contactor Open" ;
VAL_ 2365207038 HVInternalContactor6St 3 "Not Available" 2 "Error" 1 "Contactor Closed" 0 "Contactor Open" ;
VAL_ 2365207038 HVInternalContactor5St 3 "Not Available" 2 "Error" 1 "Contactor Closed" 0 "Contactor Open" ;
VAL_ 2365207038 HVInternalContactor4St 3 "Not Available" 2 "Error" 1 "Contactor Closed" 0 "Contactor Open" ;
VAL_ 2365207038 HVInternalContactor3St 3 "Not Available" 2 "Error" 1 "Contactor Closed" 0 "Contactor Open" ;
VAL_ 2365207038 HVInternalContactor2St 3 "Not Available" 2 "Error" 1 "Contactor Closed" 0 "Contactor Open" ;
VAL_ 2365207038 HVInternalContactor1St 3 "Not Available" 2 "Error" 1 "Contactor Closed" 0 "Contactor Open" ;
VAL_ 2365206782 HVInternalContactor8St22577 3 "Not Available" 2 "Error" 1 "Contactor Closed" 0 "Contactor Open" ;
VAL_ 2365206782 HVInternalContactor7St22576 3 "Not Available" 2 "Error" 1 "Contactor Closed" 0 "Contactor Open" ;
VAL_ 2365206782 HVInternalContactor6St22575 3 "Not Available" 2 "Error" 1 "Contactor Closed" 0 "Contactor Open" ;
VAL_ 2365206782 HVInternalContactor5St22574 3 "Not Available" 2 "Error" 1 "Contactor Closed" 0 "Contactor Open" ;
VAL_ 2365206782 HVInternalContactor4St22573 3 "Not Available" 2 "Error" 1 "Contactor Closed" 0 "Contactor Open" ;
VAL_ 2365206782 HVInternalContactor3St22572 3 "Not Available" 2 "Error" 1 "Contactor Closed" 0 "Contactor Open" ;
VAL_ 2365206782 HVInternalContactor2St22571 3 "Not Available" 2 "Error" 1 "Contactor Closed" 0 "Contactor Open" ;
VAL_ 2365206782 HVInternalContactor1St22570 3 "Not Available" 2 "Error" 1 "Contactor Closed" 0 "Contactor Open" ;
VAL_ 2365206782 HVInternalContactor8St 3 "Not Available" 2 "Error" 1 "Contactor Closed" 0 "Contactor Open" ;
VAL_ 2365206782 HVInternalContactor7St 3 "Not Available" 2 "Error" 1 "Contactor Closed" 0 "Contactor Open" ;
VAL_ 2365206782 HVInternalContactor6St 3 "Not Available" 2 "Error" 1 "Contactor Closed" 0 "Contactor Open" ;
VAL_ 2365206782 HVInternalContactor5St 3 "Not Available" 2 "Error" 1 "Contactor Closed" 0 "Contactor Open" ;
VAL_ 2365206782 HVInternalContactor4St 3 "Not Available" 2 "Error" 1 "Contactor Closed" 0 "Contactor Open" ;
VAL_ 2365206782 HVInternalContactor3St 3 "Not Available" 2 "Error" 1 "Contactor Closed" 0 "Contactor Open" ;
VAL_ 2365206782 HVInternalContactor2St 3 "Not Available" 2 "Error" 1 "Contactor Closed" 0 "Contactor Open" ;
VAL_ 2365206782 HVInternalContactor1St 3 "Not Available" 2 "Error" 1 "Contactor Closed" 0 "Contactor Open" ;
VAL_ 2365206526 HVInternalContactor8St22555 3 "Not Available" 2 "Error" 1 "Contactor Closed" 0 "Contactor Open" ;
VAL_ 2365206526 HVInternalContactor7St22554 3 "Not Available" 2 "Error" 1 "Contactor Closed" 0 "Contactor Open" ;
VAL_ 2365206526 HVInternalContactor6St22553 3 "Not Available" 2 "Error" 1 "Contactor Closed" 0 "Contactor Open" ;
VAL_ 2365206526 HVInternalContactor5St22552 3 "Not Available" 2 "Error" 1 "Contactor Closed" 0 "Contactor Open" ;
VAL_ 2365206526 HVInternalContactor4St22551 3 "Not Available" 2 "Error" 1 "Contactor Closed" 0 "Contactor Open" ;
VAL_ 2365206526 HVInternalContactor3St22550 3 "Not Available" 2 "Error" 1 "Contactor Closed" 0 "Contactor Open" ;
VAL_ 2365206526 HVInternalContactor2St22549 3 "Not Available" 2 "Error" 1 "Contactor Closed" 0 "Contactor Open" ;
VAL_ 2365206526 HVInternalContactor1St22548 3 "Not Available" 2 "Error" 1 "Contactor Closed" 0 "Contactor Open" ;
VAL_ 2365206526 HVInternalContactor8St 3 "Not Available" 2 "Error" 1 "Contactor Closed" 0 "Contactor Open" ;
VAL_ 2365206526 HVInternalContactor7St 3 "Not Available" 2 "Error" 1 "Contactor Closed" 0 "Contactor Open" ;
VAL_ 2365206526 HVInternalContactor6St 3 "Not Available" 2 "Error" 1 "Contactor Closed" 0 "Contactor Open" ;
VAL_ 2365206526 HVInternalContactor5St 3 "Not Available" 2 "Error" 1 "Contactor Closed" 0 "Contactor Open" ;
VAL_ 2365206526 HVInternalContactor4St 3 "Not Available" 2 "Error" 1 "Contactor Closed" 0 "Contactor Open" ;
VAL_ 2365206526 HVInternalContactor3St 3 "Not Available" 2 "Error" 1 "Contactor Closed" 0 "Contactor Open" ;
VAL_ 2365206526 HVInternalContactor2St 3 "Not Available" 2 "Error" 1 "Contactor Closed" 0 "Contactor Open" ;
VAL_ 2365206526 HVInternalContactor1St 3 "Not Available" 2 "Error" 1 "Contactor Closed" 0 "Contactor Open" ;
VAL_ 2365206270 HVInternalContactor8St22533 3 "Not Available" 2 "Error" 1 "Contactor Closed" 0 "Contactor Open" ;
VAL_ 2365206270 HVInternalContactor7St22532 3 "Not Available" 2 "Error" 1 "Contactor Closed" 0 "Contactor Open" ;
VAL_ 2365206270 HVInternalContactor6St22531 3 "Not Available" 2 "Error" 1 "Contactor Closed" 0 "Contactor Open" ;
VAL_ 2365206270 HVInternalContactor5St22530 3 "Not Available" 2 "Error" 1 "Contactor Closed" 0 "Contactor Open" ;
VAL_ 2365206270 HVInternalContactor4St22529 3 "Not Available" 2 "Error" 1 "Contactor Closed" 0 "Contactor Open" ;
VAL_ 2365206270 HVInternalContactor3St22528 3 "Not Available" 2 "Error" 1 "Contactor Closed" 0 "Contactor Open" ;
VAL_ 2365206270 HVInternalContactor2St22527 3 "Not Available" 2 "Error" 1 "Contactor Closed" 0 "Contactor Open" ;
VAL_ 2365206270 HVInternalContactor1St22526 3 "Not Available" 2 "Error" 1 "Contactor Closed" 0 "Contactor Open" ;
VAL_ 2365206270 HVInternalContactor8St 3 "Not Available" 2 "Error" 1 "Contactor Closed" 0 "Contactor Open" ;
VAL_ 2365206270 HVInternalContactor7St 3 "Not Available" 2 "Error" 1 "Contactor Closed" 0 "Contactor Open" ;
VAL_ 2365206270 HVInternalContactor6St 3 "Not Available" 2 "Error" 1 "Contactor Closed" 0 "Contactor Open" ;
VAL_ 2365206270 HVInternalContactor5St 3 "Not Available" 2 "Error" 1 "Contactor Closed" 0 "Contactor Open" ;
VAL_ 2365206270 HVInternalContactor4St 3 "Not Available" 2 "Error" 1 "Contactor Closed" 0 "Contactor Open" ;
VAL_ 2365206270 HVInternalContactor3St 3 "Not Available" 2 "Error" 1 "Contactor Closed" 0 "Contactor Open" ;
VAL_ 2365206270 HVInternalContactor2St 3 "Not Available" 2 "Error" 1 "Contactor Closed" 0 "Contactor Open" ;
VAL_ 2365206270 HVInternalContactor1St 3 "Not Available" 2 "Error" 1 "Contactor Closed" 0 "Contactor Open" ;
VAL_ 2365206014 HVInternalContactor8St22511 3 "Not Available" 2 "Error" 1 "Contactor Closed" 0 "Contactor Open" ;
VAL_ 2365206014 HVInternalContactor7St22510 3 "Not Available" 2 "Error" 1 "Contactor Closed" 0 "Contactor Open" ;
VAL_ 2365206014 HVInternalContactor6St22509 3 "Not Available" 2 "Error" 1 "Contactor Closed" 0 "Contactor Open" ;
VAL_ 2365206014 HVInternalContactor5St22508 3 "Not Available" 2 "Error" 1 "Contactor Closed" 0 "Contactor Open" ;
VAL_ 2365206014 HVInternalContactor4St22507 3 "Not Available" 2 "Error" 1 "Contactor Closed" 0 "Contactor Open" ;
VAL_ 2365206014 HVInternalContactor3St22506 3 "Not Available" 2 "Error" 1 "Contactor Closed" 0 "Contactor Open" ;
VAL_ 2365206014 HVInternalContactor2St22505 3 "Not Available" 2 "Error" 1 "Contactor Closed" 0 "Contactor Open" ;
VAL_ 2365206014 HVInternalContactor1St22504 3 "Not Available" 2 "Error" 1 "Contactor Closed" 0 "Contactor Open" ;
VAL_ 2365206014 HVInternalContactor8St 3 "Not Available" 2 "Error" 1 "Contactor Closed" 0 "Contactor Open" ;
VAL_ 2365206014 HVInternalContactor7St 3 "Not Available" 2 "Error" 1 "Contactor Closed" 0 "Contactor Open" ;
VAL_ 2365206014 HVInternalContactor6St 3 "Not Available" 2 "Error" 1 "Contactor Closed" 0 "Contactor Open" ;
VAL_ 2365206014 HVInternalContactor5St 3 "Not Available" 2 "Error" 1 "Contactor Closed" 0 "Contactor Open" ;
VAL_ 2365206014 HVInternalContactor4St 3 "Not Available" 2 "Error" 1 "Contactor Closed" 0 "Contactor Open" ;
VAL_ 2365206014 HVInternalContactor3St 3 "Not Available" 2 "Error" 1 "Contactor Closed" 0 "Contactor Open" ;
VAL_ 2365206014 HVInternalContactor2St 3 "Not Available" 2 "Error" 1 "Contactor Closed" 0 "Contactor Open" ;
VAL_ 2365206014 HVInternalContactor1St 3 "Not Available" 2 "Error" 1 "Contactor Closed" 0 "Contactor Open" ;
